VERSION ""

NS_ :

BS_:

BU_: VCM SCIM IC CCM

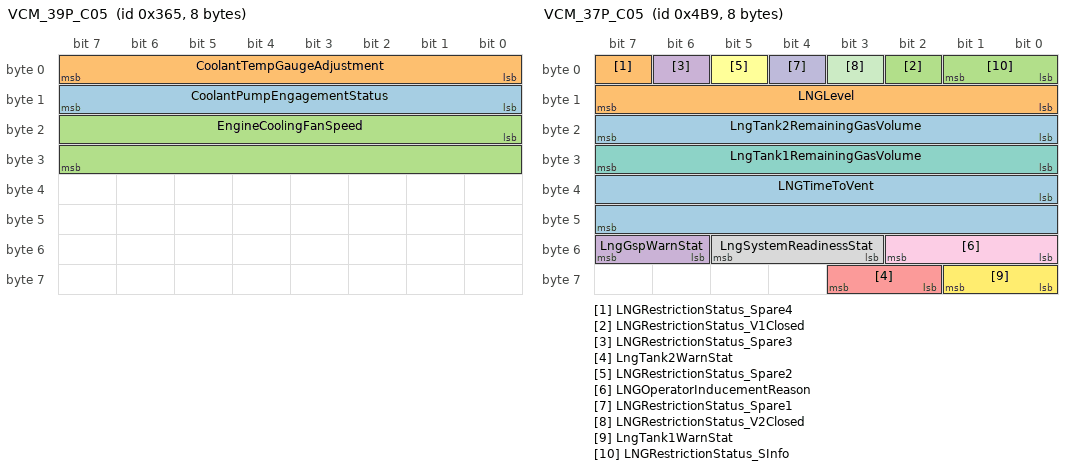
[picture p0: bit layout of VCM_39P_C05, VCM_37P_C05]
BO_ 869 VCM_39P_C05: 8 VCM
 SG_ CoolantPumpEngagementStatus : 8|8@1+ (0.4,0) [0|102] "Percent"  CCM
 SG_ CoolantTempGaugeAdjustment : 0|8@1+ (0.4,0) [0|102] "Percent"  IC
 SG_ EngineCoolingFanSpeed : 16|16@1+ (1,0) [0|65535] "rpm"  CCM

BO_ 881 VCM_38P_C05_FCM: 8 CCM
 SG_ VCM_38P_C05_FCS : 0|64@1+ (1,0) [0|0] ""  VCM

BO_ 880 VCM_38P_C05: 13 VCM
 SG_ PHTimerTGWEvCmd_PhTimer1_cmd : 46|3@1+ (1,0) [0|0] ""  CCM
 SG_ PHTimerTGWEvCmd_Timer2Temp : 7|5@1+ (1,0) [0|0] ""  CCM
 SG_ PHTimerTGWEvCmd_Timer2Hours : 95|8@1+ (1,0) [0|255] "h"  CCM
 SG_ PHTimerTGWEvCmd_Timer3StartDay : 30|4@1+ (1,0) [0|0] ""  CCM
 SG_ PHTimerTGWEvCmd_Timer2StartDay : 38|4@1+ (1,0) [0|0] ""  CCM
 SG_ PHTimerTGWEvCmd_PhTimer3_cmd : 52|3@1+ (1,0) [0|0] ""  CCM
 SG_ PHTimerTGWEvCmd_Timer3Hours : 87|8@1+ (1,0) [0|255] "h"  CCM
 SG_ PHTimerTGWEvCmd_Timer2Recur : 42|4@1+ (1,0) [0|0] ""  CCM
 SG_ PHTimerTGWEvCmd_PhTimer2_cmd : 49|3@1+ (1,0) [0|0] ""  CCM
 SG_ PHTimerTGWEvCmd_Timer3Temp : 12|5@1+ (1,0) [0|0] ""  CCM
 SG_ PHTimerTGWEvCmd_Timer1Hours : 71|8@1+ (1,0) [0|255] "h"  CCM
 SG_ PHTimerTGWEvCmd_Timer3Recur : 26|4@1+ (1,0) [0|0] ""  CCM
 SG_ PHTimerTGWEvCmd_Timer3Minutes : 55|8@1+ (1,0) [0|255] "min"  CCM
 SG_ PHTimerTGWEvCmd_Timer1Minutes : 79|8@1+ (1,0) [0|255] "min"  CCM
 SG_ PHTimerTGWEvCmd_Timer1Recur : 34|4@1+ (1,0) [0|0] ""  CCM
 SG_ PHTimerTGWEvCmd_Timer1StartDay : 22|4@1+ (1,0) [0|0] ""  CCM
 SG_ PHTimerTGWEvCmd_Timer2Minutes : 63|8@1+ (1,0) [0|255] "min"  CCM
 SG_ PHTimerTGWEvCmd_Timer1Duration : 0|7@1+ (1,0) [0|127] "min"  CCM
 SG_ PHTimerTGWEvCmd_Timer1Temp : 17|5@1+ (1,0) [0|0] ""  CCM

BO_ 1209 VCM_37P_C05: 8 VCM
 SG_ LngTank2RemainingGasVolume : 16|8@1+ (0.4,0) [0|102] "Percent"  IC
 SG_ LNGRestrictionStatus_Spare4 : 7|1@1+ (1,0) [0|0] ""  IC
 SG_ LNGRestrictionStatus_V1Closed : 2|1@1+ (1,0) [0|0] ""  IC
 SG_ LNGRestrictionStatus_Spare3 : 6|1@1+ (1,0) [0|0] ""  IC
 SG_ LngTank2WarnStat : 58|2@1+ (1,0) [0|0] ""  IC
 SG_ LNGRestrictionStatus_Spare2 : 5|1@1+ (1,0) [0|0] ""  IC
 SG_ LngTank1RemainingGasVolume : 24|8@1+ (0.4,0) [0|102] "Percent"  IC
 SG_ LngSystemReadinessStat : 51|3@1+ (1,0) [0|0] ""  IC
 SG_ LNGOperatorInducementReason : 48|3@1+ (1,0) [0|0] ""  IC
 SG_ LNGRestrictionStatus_Spare1 : 4|1@1+ (1,0) [0|0] ""  IC
 SG_ LNGRestrictionStatus_V2Closed : 3|1@1+ (1,0) [0|0] ""  IC
 SG_ LngTank1WarnStat : 56|2@1+ (1,0) [0|0] ""  IC
 SG_ LNGTimeToVent : 32|16@1+ (1,0) [0|65535] "min"  IC
 SG_ LNGLevel : 8|8@1+ (0.4,0) [0|102] "Percent"  IC
 SG_ LNGRestrictionStatus_SInfo : 0|2@1+ (1,0) [0|0] ""  IC
 SG_ LngGspWarnStat : 54|2@1+ (1,0) [0|0] ""  IC

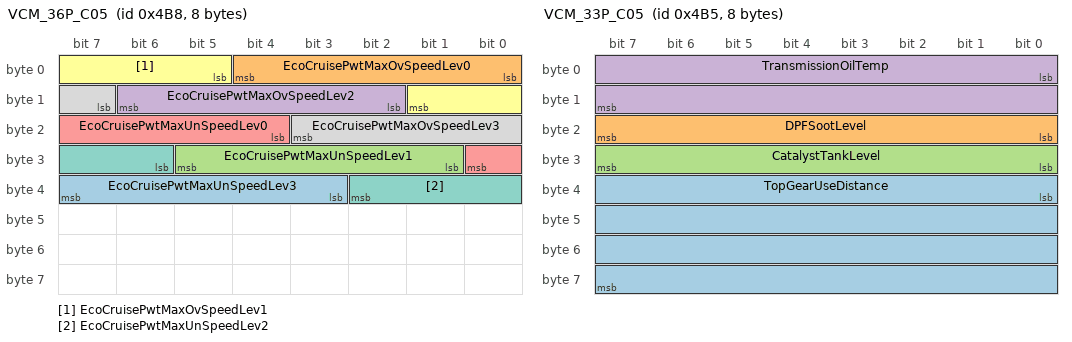
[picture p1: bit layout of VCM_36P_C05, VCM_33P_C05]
BO_ 1208 VCM_36P_C05: 8 VCM
 SG_ EcoCruisePwtMaxUnSpeedLev3 : 35|5@1+ (1,0) [0|31] "Km_per_h"  IC
 SG_ EcoCruisePwtMaxOvSpeedLev0 : 0|5@1+ (1,0) [0|31] "Km_per_h"  IC
 SG_ EcoCruisePwtMaxUnSpeedLev1 : 25|5@1+ (1,0) [0|31] "Km_per_h"  IC
 SG_ EcoCruisePwtMaxOvSpeedLev2 : 10|5@1+ (1,0) [0|31] "Km_per_h"  IC
 SG_ EcoCruisePwtMaxUnSpeedLev0 : 20|5@1+ (1,0) [0|31] "Km_per_h"  IC
 SG_ EcoCruisePwtMaxOvSpeedLev1 : 5|5@1+ (1,0) [0|31] "Km_per_h"  IC
 SG_ EcoCruisePwtMaxUnSpeedLev2 : 30|5@1+ (1,0) [0|31] "Km_per_h"  IC
 SG_ EcoCruisePwtMaxOvSpeedLev3 : 15|5@1+ (1,0) [0|31] "Km_per_h"  IC

BO_ 1207 VCM_35P_C05: 8 VCM
 SG_ EngineTotalLngConsumed : 32|32@1+ (0.01,0) [0|42949672.95] "kg"  IC
 SG_ TotalVehicleDistanceHighRes : 0|32@1+ (5,0) [0|21474836475] "m"  CCM

BO_ 1206 VCM_34P_C05: 8 VCM
 SG_ PredictedMileageOfNextPadChg : 0|32@1+ (1,0) [0|4294967295] "km"  IC
 SG_ EngineRunningTime : 32|32@1+ (1,0) [0|4294967295] "s"  IC

BO_ 1205 VCM_33P_C05: 8 VCM
 SG_ TopGearUseDistance : 32|32@1+ (0.01,0) [0|42949672.95] "km"  IC
 SG_ DPFSootLevel : 16|8@1+ (1,0) [0|255] "Percent"  IC
 SG_ CatalystTankLevel : 24|8@1+ (0.4,0) [0|102] "Percent"  IC
 SG_ TransmissionOilTemp : 0|16@1+ (0.03125,-273) [-273|1774.96875] "DegreeC"  IC

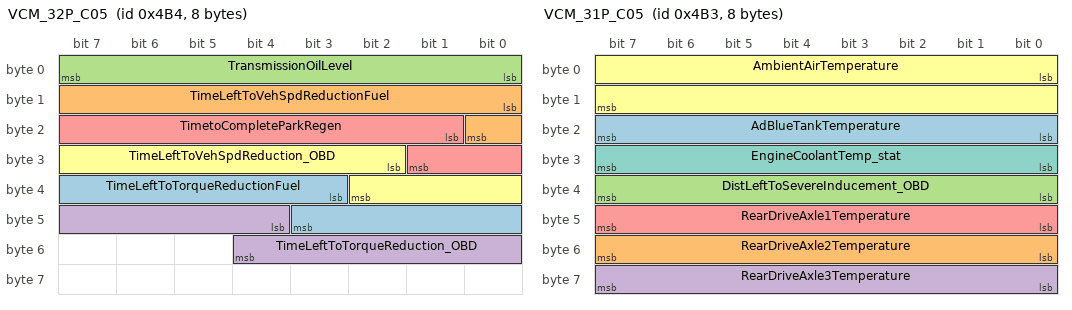
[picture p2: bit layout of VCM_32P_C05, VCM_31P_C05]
BO_ 1204 VCM_32P_C05: 8 VCM
 SG_ TimeLeftToTorqueReductionFuel : 35|9@1+ (12,0) [0|6132] "min"  IC
 SG_ TimeLeftToVehSpdReductionFuel : 8|9@1+ (15,0) [0|7665] "min"  IC
 SG_ TransmissionOilLevel : 0|8@1+ (0.4,0) [0|102] "Percent"  IC
 SG_ TimeLeftToTorqueReduction_OBD : 44|9@1+ (12,0) [0|6132] "min"  IC
 SG_ TimetoCompleteParkRegen : 17|9@1+ (15,0) [0|7665] "min"  IC
 SG_ TimeLeftToVehSpdReduction_OBD : 26|9@1+ (15,0) [0|7665] "min"  IC

BO_ 1203 VCM_31P_C05: 8 VCM
 SG_ AdBlueTankTemperature : 16|8@1+ (1,-50) [-50|205] "DegreeC"  IC
 SG_ RearDriveAxle2Temperature : 48|8@1+ (1,0) [0|255] "DegreeC"  IC
 SG_ DistLeftToSevereInducement_OBD : 32|8@1+ (5,0) [0|1275] "km"  IC
 SG_ RearDriveAxle3Temperature : 56|8@1+ (1,0) [0|255] "DegreeC"  IC
 SG_ RearDriveAxle1Temperature : 40|8@1+ (1,0) [0|255] "DegreeC"  IC
 SG_ AmbientAirTemperature : 0|16@1+ (0.03125,-273) [-273|1774.96875] "DegreeC"  CCM
 SG_ EngineCoolantTemp_stat : 24|8@1+ (1,-40) [-40|215] "DegreeC"  CCM

BO_ 1202 VCM_30P_C05: 8 VCM
 SG_ FasUsrDefinedDampingSetting : 42|5@1+ (1,-10) [-10|21] ""  IC
 SG_ SCROperatorInducementSeverity : 12|3@1+ (1,0) [0|0] ""  IC
 SG_ CatalystTankLevelLow : 57|2@1+ (1,0) [0|0] ""  IC
 SG_ MIStatusExtEMS : 61|2@1+ (1,0) [0|0] ""  IC
 SG_ FuelOperatorDeratingReason : 4|2@1+ (1,0) [0|0] ""  IC
 SG_ ActualFasPersSettingsButton : 18|3@1+ (1,0) [0|0] ""  IC
 SG_ BatteryEndOfCharge : 0|2@1+ (1,0) [0|0] ""  IC
 SG_ FasUsrDefStiffStraightSetting : 32|5@1+ (1,-10) [-10|21] ""  IC
 SG_ LiningWearWarning : 2|2@1+ (1,0) [0|0] ""  IC
 SG_ TorqueReductionStatus_OBD : 21|3@1+ (1,0) [0|0] ""  IC
 SG_ LoadCalibrationFeedback : 9|3@1+ (1,0) [0|0] ""  IC
 SG_ FasUsrDefLowSpeedReturnSetting : 47|5@1+ (1,-10) [-10|21] ""  IC
 SG_ FuelOperatorDeratingSeverity : 6|3@1+ (1,0) [0|0] ""  IC
 SG_ FasUsrDefStiffnessCurveSetting : 37|5@1+ (1,-10) [-10|21] ""  IC
 SG_ SCROperatorInducementReason : 15|3@1+ (1,0) [0|0] ""  IC
 SG_ ActualFasManualOffsetSetting : 52|5@1+ (1,-10) [-10|21] ""  IC
 SG_ MIDistinctWarningExtEMS : 24|4@1+ (1,0) [0|0] ""  IC
 SG_ FasDriver : 28|4@1+ (1,0) [0|0] ""  IC
 SG_ MIDistinctWarning : 59|2@1+ (1,0) [0|0] ""  IC

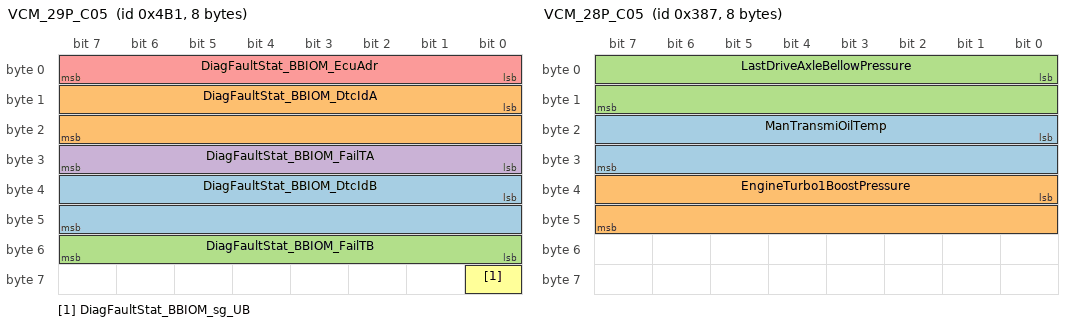
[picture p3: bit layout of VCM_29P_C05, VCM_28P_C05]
BO_ 1201 VCM_29P_C05: 8 VCM
 SG_ DiagFaultStat_BBIOM_DtcIdB : 32|16@1+ (1,0) [0|65535] ""  IC
 SG_ DiagFaultStat_BBIOM_DtcIdA : 8|16@1+ (1,0) [0|65535] ""  IC
 SG_ DiagFaultStat_BBIOM_FailTB : 48|8@1+ (1,0) [0|255] ""  IC
 SG_ DiagFaultStat_BBIOM_FailTA : 24|8@1+ (1,0) [0|255] ""  IC
 SG_ DiagFaultStat_BBIOM_EcuAdr : 0|8@1+ (1,0) [0|255] ""  IC
 SG_ DiagFaultStat_BBIOM_sg_UB : 56|1@1+ (1,0) [0|0] ""  IC

BO_ 903 VCM_28P_C05: 8 VCM
 SG_ ManTransmiOilTemp : 16|16@1+ (0.03125,-273) [-273|1774.96875] "DegreeC"  IC
 SG_ EngineTurbo1BoostPressure : 32|16@1+ (0.125,0) [0|8191.875] "kPa"  IC
 SG_ LastDriveAxleBellowPressure : 0|16@1+ (0.1,0) [0|6553.5] "kPa"  IC

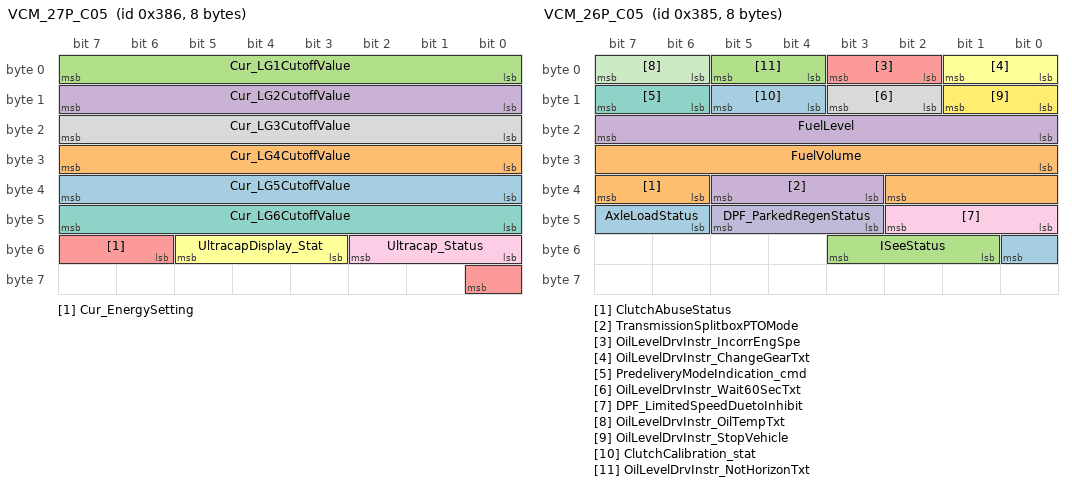
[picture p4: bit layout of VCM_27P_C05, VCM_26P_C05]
BO_ 902 VCM_27P_C05: 8 VCM
 SG_ Cur_LG5CutoffValue : 32|8@1+ (1,0) [0|255] "Percent"  IC
 SG_ Cur_LG4CutoffValue : 24|8@1+ (1,0) [0|255] "Percent"  IC
 SG_ Cur_LG1CutoffValue : 0|8@1+ (1,0) [0|255] "Percent"  IC
 SG_ Cur_LG2CutoffValue : 8|8@1+ (1,0) [0|255] "Percent"  IC
 SG_ Cur_EnergySetting : 54|3@1+ (1,0) [0|0] ""  IC
 SG_ UltracapDisplay_Stat : 51|3@1+ (1,0) [0|0] ""  IC
 SG_ Cur_LG6CutoffValue : 40|8@1+ (1,0) [0|255] "Percent"  IC
 SG_ Cur_LG3CutoffValue : 16|8@1+ (1,0) [0|255] "Percent"  IC
 SG_ Ultracap_Status : 48|3@1+ (1,0) [0|0] ""  IC

BO_ 901 VCM_26P_C05: 8 VCM
 SG_ AxleLoadStatus : 46|3@1+ (1,0) [0|0] ""  IC
 SG_ ClutchAbuseStatus : 38|2@1+ (1,0) [0|0] ""  IC
 SG_ ISeeStatus : 49|3@1+ (1,0) [0|0] ""  IC
 SG_ TransmissionSplitboxPTOMode : 35|3@1+ (1,0) [0|0] ""  IC
 SG_ OilLevelDrvInstr_IncorrEngSpe : 2|2@1+ (1,0) [0|0] ""  IC
 SG_ OilLevelDrvInstr_ChangeGearTxt : 0|2@1+ (1,0) [0|0] ""  IC
 SG_ PredeliveryModeIndication_cmd : 14|2@1+ (1,0) [0|0] ""  IC
 SG_ OilLevelDrvInstr_Wait60SecTxt : 10|2@1+ (1,0) [0|0] ""  IC
 SG_ DPF_LimitedSpeedDuetoInhibit : 40|3@1+ (1,0) [0|0] ""  IC
 SG_ DPF_ParkedRegenStatus : 43|3@1+ (1,0) [0|0] ""  IC
 SG_ OilLevelDrvInstr_OilTempTxt : 6|2@1+ (1,0) [0|0] ""  IC
 SG_ OilLevelDrvInstr_StopVehicle : 8|2@1+ (1,0) [0|0] ""  IC
 SG_ ClutchCalibration_stat : 12|2@1+ (1,0) [0|0] ""  IC
 SG_ FuelVolume : 24|11@1+ (1,0) [0|2047] "l"  CCM,IC
 SG_ OilLevelDrvInstr_NotHorizonTxt : 4|2@1+ (1,0) [0|0] ""  IC
 SG_ FuelLevel : 16|8@1+ (0.4,0) [0|102] "Percent"  CCM

BO_ 868 VCM_25P_C05: 8 VCM
 SG_ DrainPrimingStatus : 60|3@1+ (1,0) [0|0] ""  IC
 SG_ FrontConspicLamp_stat_HiRight : 0|3@1+ (1,0) [0|0] ""  IC
 SG_ FrontConspicLamp_stat_LoRight : 3|3@1+ (1,0) [0|0] ""  IC
 SG_ CoolantTempHigh : 54|3@1+ (1,0) [0|0] ""  IC
 SG_ AutoWheelBrakesStatus : 32|3@1+ (1,0) [0|0] ""  IC
 SG_ OilLevelLow : 51|3@1+ (1,0) [0|0] ""  IC
 SG_ InletAirHeaterStatus1 : 40|2@1+ (1,0) [0|0] ""  IC
 SG_ DeicingFunction_Stat : 45|3@1+ (1,0) [0|0] ""  IC
 SG_ SelfStartAssist_stat : 14|2@1+ (1,0) [0|0] ""  IC
 SG_ TrailerDirIndLeftOutputStat : 19|3@1+ (1,0) [0|0] ""  IC
 SG_ TrailerPosLightLeftOutputStat : 24|3@1+ (1,0) [0|0] ""  IC
 SG_ TrailerBrakeLightOutputStat : 16|3@1+ (1,0) [0|0] ""  IC
 SG_ StartBatteryDisplay_stat : 35|3@1+ (1,0) [0|0] ""  IC
 SG_ DeicingBulb_Stat : 42|3@1+ (1,0) [0|0] ""  IC
 SG_ LivBatDisconnectDetectStat : 30|2@1+ (1,0) [0|0] ""  IC
 SG_ FrontConspicLamp_stat_LoLeft : 9|3@1+ (1,0) [0|0] ""  IC
 SG_ FuelFilterClogged : 57|3@1+ (1,0) [0|0] ""  IC
 SG_ EngineFanOverspeed : 22|2@1+ (1,0) [0|0] ""  IC
 SG_ JumpChargeInterface_stat : 38|2@1+ (1,0) [0|0] ""  IC
 SG_ OilPressureLow : 48|3@1+ (1,0) [0|0] ""  IC
 SG_ FrontConspicLamp_stat_HiLeft : 6|3@1+ (1,0) [0|0] ""  IC
 SG_ GChargerStatus : 27|3@1+ (1,0) [0|0] ""  IC
 SG_ TrailerRevAndFogOutput_stat : 12|2@1+ (1,0) [0|0] ""  IC

BO_ 867 VCM_24P_C05: 8 VCM
 SG_ DirIndSideLamp_stat : 54|3@1+ (1,0) [0|0] ""  IC
 SG_ DirInd_Front_Status : 27|3@1+ (1,0) [0|0] ""  IC
 SG_ FogLightFrontLamp_stat : 3|3@1+ (1,0) [0|0] ""  IC
 SG_ MainBeamLEDStatusRight : 33|3@1+ (1,0) [0|0] ""  IC
 SG_ RevLightLamp_stat : 0|3@1+ (1,0) [0|0] ""  IC
 SG_ ExtraMainBeamLamp_stat : 24|3@1+ (1,0) [0|0] ""  IC
 SG_ MainBeamLEDStatusLeft : 18|3@1+ (1,0) [0|0] ""  IC
 SG_ PositionLightRearLamp_stat : 36|3@1+ (1,0) [0|0] ""  IC
 SG_ TrailerPosLightRightOutputStat : 12|3@1+ (1,0) [0|0] ""  IC
 SG_ DirIndRearLamp_Stat : 51|3@1+ (1,0) [0|0] ""  IC
 SG_ FogLightRearLamp_stat : 48|3@1+ (1,0) [0|0] ""  IC
 SG_ BrakeLightLamp_stat : 45|3@1+ (1,0) [0|0] ""  IC
 SG_ DippedBeamLamp_stat : 15|3@1+ (1,0) [0|0] ""  IC
 SG_ ChassiInstepLightsLamp_stat : 30|3@1+ (1,0) [0|0] ""  IC
 SG_ DRLLamp_stat : 42|3@1+ (1,0) [0|0] ""  IC
 SG_ TrailerDirIndRightOutputStat : 6|3@1+ (1,0) [0|0] ""  IC
 SG_ HeadlampFan_stat : 60|3@1+ (1,0) [0|0] ""  IC
 SG_ MainBeamLamp_stat : 21|3@1+ (1,0) [0|0] ""  IC
 SG_ StaticCornerLightLamp_stat : 57|3@1+ (1,0) [0|0] ""  IC
 SG_ AuxFogLightLamp_stat : 9|3@1+ (1,0) [0|0] ""  IC
 SG_ PositionLightLamp_stat : 39|3@1+ (1,0) [0|0] ""  IC

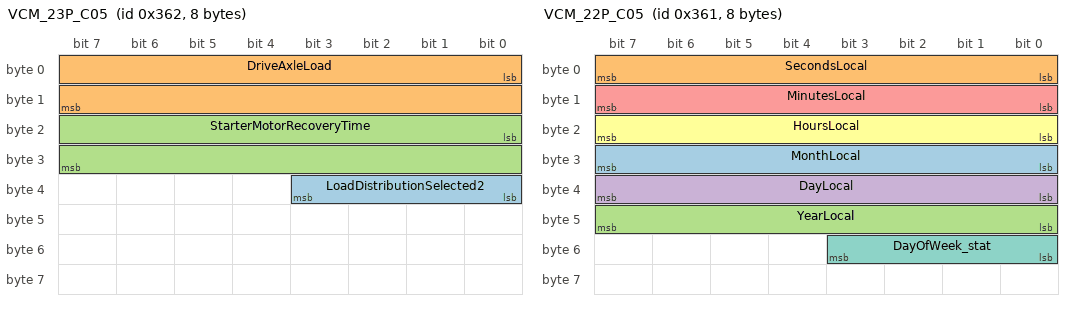
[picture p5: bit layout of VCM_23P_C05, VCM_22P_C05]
BO_ 866 VCM_23P_C05: 8 VCM
 SG_ LoadDistributionSelected2 : 32|4@1+ (1,0) [0|0] ""  IC
 SG_ DriveAxleLoad : 0|16@1+ (0.5,0) [0|32767.5] "kg"  IC
 SG_ StarterMotorRecoveryTime : 16|16@1+ (1,0) [0|65535] "s"  IC

BO_ 865 VCM_22P_C05: 8 VCM
 SG_ MonthLocal : 24|8@1+ (1,0) [0|255] "Months"  CCM
 SG_ SecondsLocal : 0|8@1+ (0.25,0) [0|63.75] "s"  CCM
 SG_ YearLocal : 40|8@1+ (1,1985) [1985|2240] "Years"  CCM
 SG_ DayLocal : 32|8@1+ (0.25,0) [0|63.75] "Days"  CCM
 SG_ MinutesLocal : 8|8@1+ (1,0) [0|255] "min"  CCM
 SG_ HoursLocal : 16|8@1+ (1,0) [0|255] "h"  CCM
 SG_ DayOfWeek_stat : 48|4@1+ (1,0) [0|0] ""  CCM,IC

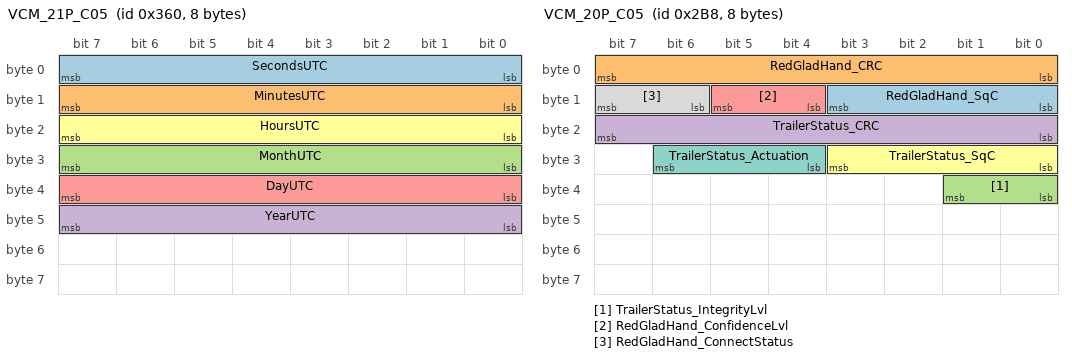
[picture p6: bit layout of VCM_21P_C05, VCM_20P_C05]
BO_ 864 VCM_21P_C05: 8 VCM
 SG_ SecondsUTC : 0|8@1+ (0.25,0) [0|63.75] "s"  CCM
 SG_ MinutesUTC : 8|8@1+ (1,0) [0|255] "min"  CCM
 SG_ MonthUTC : 24|8@1+ (1,0) [0|255] "Months"  CCM
 SG_ YearUTC : 40|8@1+ (1,1985) [1985|2240] "Years"  CCM
 SG_ DayUTC : 32|8@1+ (0.25,0) [0|63.75] "Days"  CCM
 SG_ HoursUTC : 16|8@1+ (1,0) [0|255] "h"  CCM

BO_ 696 VCM_20P_C05: 8 VCM
 SG_ RedGladHand_SqC : 8|4@1+ (1,0) [0|14] "NotApplicable"  IC
 SG_ RedGladHand_CRC : 0|8@1+ (1,0) [0|255] ""  IC
 SG_ TrailerStatus_IntegrityLvl : 32|2@1+ (1,0) [0|0] ""  IC
 SG_ TrailerStatus_CRC : 16|8@1+ (1,0) [0|255] ""  IC
 SG_ RedGladHand_ConfidenceLvl : 12|2@1+ (1,0) [0|0] ""  IC
 SG_ TrailerStatus_SqC : 24|4@1+ (1,0) [0|14] "NotApplicable"  IC
 SG_ TrailerStatus_Actuation : 28|3@1+ (1,0) [0|0] ""  IC
 SG_ RedGladHand_ConnectStatus : 14|2@1+ (1,0) [0|0] ""  IC

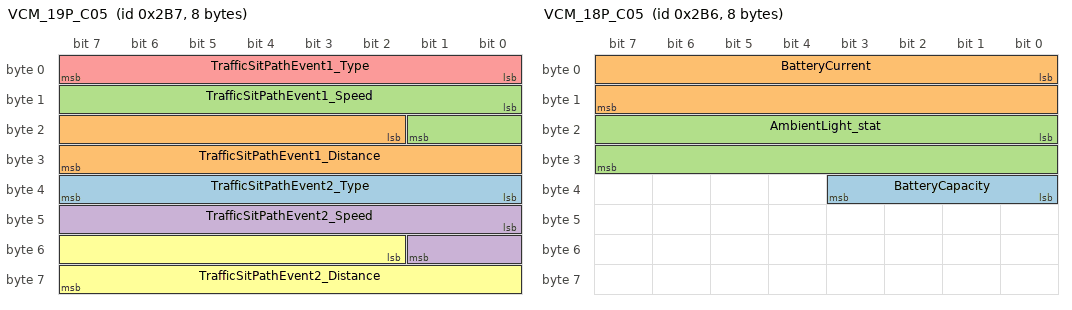
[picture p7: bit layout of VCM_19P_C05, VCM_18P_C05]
BO_ 695 VCM_19P_C05: 8 VCM
 SG_ TrafficSitPathEvent2_Type : 32|8@1+ (1,0) [0|0] ""  IC
 SG_ TrafficSitPathEvent1_Distance : 18|14@1+ (1,0) [0|16383] "m"  IC
 SG_ TrafficSitPathEvent1_Speed : 8|10@1+ (0.25,0) [0|255.75] "Km_per_h"  IC
 SG_ TrafficSitPathEvent2_Speed : 40|10@1+ (0.25,0) [0|255.75] "Km_per_h"  IC
 SG_ TrafficSitPathEvent1_Type : 0|8@1+ (1,0) [0|0] ""  IC
 SG_ TrafficSitPathEvent2_Distance : 50|14@1+ (1,0) [0|16383] "m"  IC

BO_ 694 VCM_18P_C05: 8 VCM
 SG_ BatteryCapacity : 32|4@1+ (1,0) [0|0] ""  IC
 SG_ BatteryCurrent : 0|16@1+ (0.05,-1600) [-1600|1676.75] "A"  IC
 SG_ AmbientLight_stat : 16|16@1+ (1,0) [0|65535] "lx"  IC

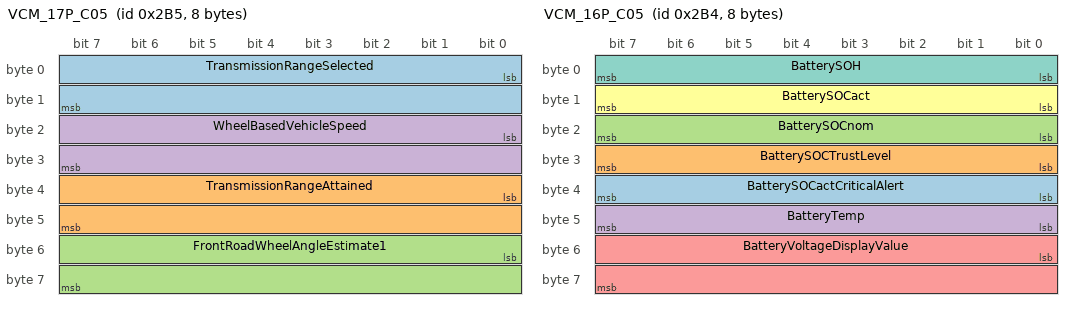
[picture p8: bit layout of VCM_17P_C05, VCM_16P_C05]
BO_ 693 VCM_17P_C05: 8 VCM
 SG_ TransmissionRangeSelected : 0|16@1+ (1,0) [0|0] ""  IC
 SG_ TransmissionRangeAttained : 32|16@1+ (1,0) [0|0] ""  IC
 SG_ FrontRoadWheelAngleEstimate1 : 48|16@1+ (5E-005,-1.6) [-1.6|1.67675] "rad"  IC
 SG_ WheelBasedVehicleSpeed : 16|16@1+ (0.00390625,0) [0|255.99609375] "Km_per_h"  CCM

BO_ 692 VCM_16P_C05: 8 VCM
 SG_ BatterySOCactCriticalAlert : 32|8@1+ (0.5,0) [0|127.5] "Percent"  IC
 SG_ BatterySOCTrustLevel : 24|8@1+ (0.5,0) [0|127.5] "Percent"  IC
 SG_ BatterySOCnom : 16|8@1+ (0.5,0) [0|127.5] "Percent"  IC
 SG_ BatteryTemp : 40|8@1+ (1,-45) [-45|210] "DegreeC"  IC
 SG_ BatteryVoltageDisplayValue : 48|16@1+ (0.05,0) [0|3276.75] "V"  IC
 SG_ BatterySOCact : 8|8@1+ (0.5,0) [0|127.5] "Percent"  IC
 SG_ BatterySOH : 0|8@1+ (0.5,0) [0|127.5] "Percent"  IC

CM_ "COM_MATRIX_T3_1.9.0";
CM_ BU_ VCM "Vehicle Control Module";
CM_ BU_ SCIM "Security and Cab Interface Module";
CM_ BU_ IC "Instrument Cluster";
CM_ BU_ CCM "Climate Control Module";
BA_DEF_ BO_  "GenMsgStartDelayTime" INT 0 0;
BA_DEF_ BO_  "GenMsgDelayTime" INT 0 0;
BA_DEF_ BO_  "GenMsgCycleTime" INT 0 0;
BA_DEF_ BO_  "GenMsgSendType" ENUM  "Cyclic","NotUsed","NotUsed","NotUsed","NotUsed","NotUsed","NotUsed","IfActive","NoMsgSendType","NotUsed";
BA_DEF_ SG_  "GenSigStartValue" INT 0 0;
BA_DEF_ SG_  "GenSigCycleTimeActive" INT 0 0;
BA_DEF_ SG_  "GenSigCycleTime" INT 0 0;
BA_DEF_ SG_  "GenSigSendType" ENUM  "Cyclic","OnWrite","OnWriteWithRepetition","OnChange","OnChangeWithRepetition","IfActive","IfActiveWithRepetition","NoSigSendType","NotUsed","NotUsed","NotUsed","NotUsed","NotUsed";
BA_DEF_  "Baudrate" INT 0 1000000;
BA_DEF_  "NmType" STRING ;
BA_DEF_  "Manufacturer" STRING ;
BA_DEF_  "VersionYear" INT 0 99;
BA_DEF_  "VersionNumber" INT 0 99;
BA_DEF_  "VersionMonth" INT 1 12;
BA_DEF_  "VersionDay" INT 1 31;
BA_DEF_ BO_  "VFrameFormat" ENUM  "StandardCAN","ExtendedCAN","reserved","J1939PG","reserved","reserved","reserved","reserved","reserved","reserved","reserved","reserved","reserved","reserved","StandardCAN_FD","ExtendedCAN_FD";
BA_DEF_ BU_  "TpOwnSystemEcuNumber" HEX 0 255;
BA_DEF_ SG_  "SigType" ENUM  "Default","Range","RangeSigned","ASCII","Discrete","Control","ReferencePGN","DTC","StringDelimiter","StringLength","StringLengthControl";
BA_DEF_ BU_  "NmStationAddress" INT 0 255;
BA_DEF_  "NmAsrWaitBusSleepTime" INT 0 65535;
BA_DEF_  "NmAsrTimeoutTime" INT 0 65535;
BA_DEF_  "NmAsrRepeatMessageTime" INT 0 65535;
BA_DEF_ BU_  "NmAsrNodeIdentifier" HEX 0 253;
BA_DEF_ BU_  "NmAsrNode" ENUM  "No","Yes";
BA_DEF_  "NmAsrMessageCount" INT 1 256;
BA_DEF_ BO_  "NmAsrMessage" ENUM  "No","Yes";
BA_DEF_  "NmAsrCanMsgCycleTime" INT 0 65535;
BA_DEF_  "NmAsrBaseAddress" HEX 0 536870911;
BA_DEF_ SG_  "NeedsUpdateBit" ENUM  "No","Yes";
BA_DEF_ SG_  "MmAnSignal" ENUM  "No","Yes";
BA_DEF_ BU_  "IsOBDrelevant" ENUM  "No","Yes";
BA_DEF_ SG_  "GenSigMaxLatency" INT 0 65535;
BA_DEF_ SG_  "GenSigILSupport" ENUM  "Yes","No";
BA_DEF_ BO_  "GenMsgILSupport" ENUM  "No","Yes";
BA_DEF_ SG_  "E2EProfile" STRING ;
BA_DEF_  "E2EP05WindowSize" INT 0 65535;
BA_DEF_  "E2EP05ProfileName" STRING ;
BA_DEF_  "E2EP05MinOkStateValid" INT 0 65535;
BA_DEF_  "E2EP05MinOkStateInvalid" INT 0 65535;
BA_DEF_  "E2EP05MinOkStateInit" INT 0 65535;
BA_DEF_  "E2EP05MaxErrorStateValid" INT 0 65535;
BA_DEF_  "E2EP05MaxErrorStateInvalid" INT 0 65535;
BA_DEF_  "E2EP05MaxErrorStateInit" INT 0 65535;
BA_DEF_  "E2EP05MaxDeltaCounter" INT 0 65535;
BA_DEF_  "E2EP01WindowSize" INT 0 65535;
BA_DEF_  "E2EP01SyncCounterInit" INT 0 65535;
BA_DEF_  "E2EP01ProfileName" STRING ;
BA_DEF_  "E2EP01MinOkStateValid" INT 0 65535;
BA_DEF_  "E2EP01MinOkStateInvalid" INT 0 65535;
BA_DEF_  "E2EP01MinOkStateInit" INT 0 65535;
BA_DEF_  "E2EP01MaxNoNewOrRepeatedData" INT 0 65535;
BA_DEF_  "E2EP01MaxErrorStateValid" INT 0 65535;
BA_DEF_  "E2EP01MaxErrorStateInvalid" INT 0 65535;
BA_DEF_  "E2EP01MaxErrorStateInit" INT 0 65535;
BA_DEF_  "E2EP01MaxDeltaCounter" INT 0 65535;
BA_DEF_  "E2EP01DataIdMode" ENUM  "all16Bit","alternating8Bit","lower12Bit","lower8Bit";
BA_DEF_  "E2EP01CounterOffset" INT 0 65535;
BA_DEF_ SG_  "E2EDataLength" INT 0 65535;
BA_DEF_ SG_  "E2EDataId" INT 0 65535;
BA_DEF_ BU_  "DiagnosticClientAddress" HEX 0 255;
BA_DEF_ BO_  "DiagUUDTResponse" ENUM  "No","Yes";
BA_DEF_ BO_  "DiagState" ENUM  "No","Yes";
BA_DEF_ BU_  "DiagRole" ENUM  "None","OBDTester","ExternalTester","InternalTester";
BA_DEF_ BO_  "DiagResponse" ENUM  "No","Yes";
BA_DEF_ BO_  "DiagRequest" ENUM  "No","Yes";
BA_DEF_ BO_  "DiagConnection" HEX 0 65535;
BA_DEF_  "DBName" STRING ;
BA_DEF_ BO_  "CanTpFcFrameId" HEX 0 2147483647;
BA_DEF_ BO_  "CanTpBs" INT 0 255;
BA_DEF_  "BusType" STRING ;
BA_DEF_  "BaudrateCANFD" INT 0 5000000;
BA_DEF_REL_ BU_SG_REL_  "GenSigTimeoutTime" INT 0 65535;
BA_DEF_REL_ BU_SG_REL_  "GenSigFirstTimeoutTime" INT 0 65535;
BA_DEF_DEF_  "GenMsgStartDelayTime" 0;
BA_DEF_DEF_  "GenMsgDelayTime" 0;
BA_DEF_DEF_  "GenMsgCycleTime" 0;
BA_DEF_DEF_  "GenMsgSendType" "Cyclic";
BA_DEF_DEF_  "GenSigStartValue" 0;
BA_DEF_DEF_  "GenSigCycleTimeActive" 0;
BA_DEF_DEF_  "GenSigCycleTime" 0;
BA_DEF_DEF_  "GenSigSendType" "Cyclic";
BA_DEF_DEF_  "Baudrate" 500000;
BA_DEF_DEF_  "NmType" "";
BA_DEF_DEF_  "Manufacturer" "VOLVO_AB";
BA_DEF_DEF_  "VersionYear" 0;
BA_DEF_DEF_  "VersionNumber" 0;
BA_DEF_DEF_  "VersionMonth" 1;
BA_DEF_DEF_  "VersionDay" 1;
BA_DEF_DEF_  "VFrameFormat" "ExtendedCAN";
BA_DEF_DEF_  "TpOwnSystemEcuNumber" 0;
BA_DEF_DEF_  "SigType" "Default";
BA_DEF_DEF_  "NmStationAddress" 254;
BA_DEF_DEF_  "NmAsrWaitBusSleepTime" 750;
BA_DEF_DEF_  "NmAsrTimeoutTime" 5000;
BA_DEF_DEF_  "NmAsrRepeatMessageTime" 300;
BA_DEF_DEF_  "NmAsrNodeIdentifier" 0;
BA_DEF_DEF_  "NmAsrNode" "Yes";
BA_DEF_DEF_  "NmAsrMessageCount" 256;
BA_DEF_DEF_  "NmAsrMessage" "No";
BA_DEF_DEF_  "NmAsrCanMsgCycleTime" 200;
BA_DEF_DEF_  "NmAsrBaseAddress" 486506496;
BA_DEF_DEF_  "NeedsUpdateBit" "No";
BA_DEF_DEF_  "MmAnSignal" "No";
BA_DEF_DEF_  "IsOBDrelevant" "No";
BA_DEF_DEF_  "GenSigMaxLatency" 0;
BA_DEF_DEF_  "GenSigILSupport" "Yes";
BA_DEF_DEF_  "GenMsgILSupport" "Yes";
BA_DEF_DEF_  "E2EProfile" "none";
BA_DEF_DEF_  "E2EP05WindowSize" 5;
BA_DEF_DEF_  "E2EP05ProfileName" "PROFILE_05";
BA_DEF_DEF_  "E2EP05MinOkStateValid" 1;
BA_DEF_DEF_  "E2EP05MinOkStateInvalid" 3;
BA_DEF_DEF_  "E2EP05MinOkStateInit" 1;
BA_DEF_DEF_  "E2EP05MaxErrorStateValid" 3;
BA_DEF_DEF_  "E2EP05MaxErrorStateInvalid" 1;
BA_DEF_DEF_  "E2EP05MaxErrorStateInit" 2;
BA_DEF_DEF_  "E2EP05MaxDeltaCounter" 1;
BA_DEF_DEF_  "E2EP01WindowSize" 5;
BA_DEF_DEF_  "E2EP01SyncCounterInit" 1;
BA_DEF_DEF_  "E2EP01ProfileName" "PROFILE_01";
BA_DEF_DEF_  "E2EP01MinOkStateValid" 1;
BA_DEF_DEF_  "E2EP01MinOkStateInvalid" 3;
BA_DEF_DEF_  "E2EP01MinOkStateInit" 1;
BA_DEF_DEF_  "E2EP01MaxNoNewOrRepeatedData" 5;
BA_DEF_DEF_  "E2EP01MaxErrorStateValid" 3;
BA_DEF_DEF_  "E2EP01MaxErrorStateInvalid" 1;
BA_DEF_DEF_  "E2EP01MaxErrorStateInit" 2;
BA_DEF_DEF_  "E2EP01MaxDeltaCounter" 1;
BA_DEF_DEF_  "E2EP01DataIdMode" "all16Bit";
BA_DEF_DEF_  "E2EP01CounterOffset" 8;
BA_DEF_DEF_  "E2EDataLength" 0;
BA_DEF_DEF_  "E2EDataId" 0;
BA_DEF_DEF_  "DiagnosticClientAddress" 0;
BA_DEF_DEF_  "DiagUUDTResponse" "No";
BA_DEF_DEF_  "DiagState" "No";
BA_DEF_DEF_  "DiagRole" "None";
BA_DEF_DEF_  "DiagResponse" "No";
BA_DEF_DEF_  "DiagRequest" "No";
BA_DEF_DEF_  "DiagConnection" 0;
BA_DEF_DEF_  "DBName" "";
BA_DEF_DEF_  "CanTpFcFrameId" 2147483647;
BA_DEF_DEF_  "CanTpBs" 255;
BA_DEF_DEF_  "BusType" "";
BA_DEF_DEF_  "BaudrateCANFD" 0;
BA_DEF_DEF_REL_ "GenSigTimeoutTime" 0;
BA_DEF_DEF_REL_ "GenSigFirstTimeoutTime" 0;
BA_ "NmType" "NmAsr";
BA_ "BusType" "CAN";
BA_ "BaudrateCANFD" 1000000;
BA_ "VersionDay" 24;
BA_ "VersionMonth" 2;
BA_ "VersionNumber" 1;
BA_ "VersionYear" 22;
BA_ "DBName" "CAN05";
BA_ "DiagRole" BU_ VCM 3;
BA_ "DiagnosticClientAddress" BU_ VCM 244;
BA_ "IsOBDrelevant" BU_ VCM 1;
BA_ "TpOwnSystemEcuNumber" BU_ VCM 36;
BA_ "NmAsrNodeIdentifier" BU_ VCM 36;
BA_ "TpOwnSystemEcuNumber" BU_ SCIM 64;
BA_ "NmAsrNodeIdentifier" BU_ SCIM 64;
BA_ "TpOwnSystemEcuNumber" BU_ IC 97;
BA_ "NmAsrNodeIdentifier" BU_ IC 97;
BA_ "TpOwnSystemEcuNumber" BU_ CCM 152;
BA_ "NmAsrNodeIdentifier" BU_ CCM 152;
BA_ "VFrameFormat" BO_ 869 0;
BA_ "GenMsgCycleTime" BO_ 869 250;
BA_ "GenMsgILSupport" BO_ 881 0;
BA_ "VFrameFormat" BO_ 881 0;
BA_ "GenMsgSendType" BO_ 881 8;
BA_ "CanTpFcFrameId" BO_ 880 881;
BA_ "VFrameFormat" BO_ 880 0;
BA_ "GenMsgCycleTime" BO_ 880 100;
BA_ "VFrameFormat" BO_ 1209 0;
BA_ "GenMsgCycleTime" BO_ 1209 1000;
BA_ "VFrameFormat" BO_ 1208 0;
BA_ "GenMsgCycleTime" BO_ 1208 1000;
BA_ "VFrameFormat" BO_ 1207 0;
BA_ "GenMsgCycleTime" BO_ 1207 1000;
BA_ "VFrameFormat" BO_ 1206 0;
BA_ "GenMsgCycleTime" BO_ 1206 1000;
BA_ "VFrameFormat" BO_ 1205 0;
BA_ "GenMsgCycleTime" BO_ 1205 1000;
BA_ "VFrameFormat" BO_ 1204 0;
BA_ "GenMsgCycleTime" BO_ 1204 1000;
BA_ "VFrameFormat" BO_ 1203 0;
BA_ "GenMsgCycleTime" BO_ 1203 1000;
BA_ "VFrameFormat" BO_ 1202 0;
BA_ "GenMsgCycleTime" BO_ 1202 1000;
BA_ "VFrameFormat" BO_ 1201 0;
BA_ "GenMsgCycleTime" BO_ 1201 1000;
BA_ "VFrameFormat" BO_ 903 0;
BA_ "GenMsgCycleTime" BO_ 903 500;
BA_ "VFrameFormat" BO_ 902 0;
BA_ "GenMsgCycleTime" BO_ 902 500;
BA_ "VFrameFormat" BO_ 901 0;
BA_ "GenMsgCycleTime" BO_ 901 500;
BA_ "VFrameFormat" BO_ 868 0;
BA_ "GenMsgCycleTime" BO_ 868 250;
BA_ "VFrameFormat" BO_ 867 0;
BA_ "GenMsgCycleTime" BO_ 867 250;
BA_ "VFrameFormat" BO_ 866 0;
BA_ "GenMsgCycleTime" BO_ 866 250;
BA_ "VFrameFormat" BO_ 865 0;
BA_ "GenMsgCycleTime" BO_ 865 250;
BA_ "VFrameFormat" BO_ 864 0;
BA_ "GenMsgCycleTime" BO_ 864 250;
BA_ "VFrameFormat" BO_ 696 0;
BA_ "GenMsgCycleTime" BO_ 696 100;
BA_ "VFrameFormat" BO_ 695 0;
BA_ "GenMsgCycleTime" BO_ 695 100;
BA_ "VFrameFormat" BO_ 694 0;
BA_ "GenMsgCycleTime" BO_ 694 100;
BA_ "VFrameFormat" BO_ 693 0;
BA_ "GenMsgCycleTime" BO_ 693 100;
BA_ "VFrameFormat" BO_ 692 0;
BA_ "GenMsgCycleTime" BO_ 692 100;
BA_ "GenSigCycleTime" SG_ 869 CoolantPumpEngagementStatus 100;
BA_ "GenSigCycleTimeActive" SG_ 869 CoolantPumpEngagementStatus 100;
BA_ "GenSigStartValue" SG_ 869 CoolantPumpEngagementStatus 255;
BA_ "GenSigMaxLatency" SG_ 869 CoolantPumpEngagementStatus 260;
BA_ "GenSigCycleTime" SG_ 869 CoolantTempGaugeAdjustment 100;
BA_ "GenSigCycleTimeActive" SG_ 869 CoolantTempGaugeAdjustment 100;
BA_ "GenSigStartValue" SG_ 869 CoolantTempGaugeAdjustment 255;
BA_ "GenSigMaxLatency" SG_ 869 CoolantTempGaugeAdjustment 260;
BA_ "GenSigCycleTime" SG_ 869 EngineCoolingFanSpeed 100;
BA_ "GenSigCycleTimeActive" SG_ 869 EngineCoolingFanSpeed 100;
BA_ "GenSigStartValue" SG_ 869 EngineCoolingFanSpeed 65535;
BA_ "GenSigMaxLatency" SG_ 869 EngineCoolingFanSpeed 250;
BA_ "GenSigSendType" SG_ 881 VCM_38P_C05_FCS 7;
BA_ "GenSigCycleTime" SG_ 880 PHTimerTGWEvCmd_PhTimer1_cmd 100;
BA_ "GenSigCycleTimeActive" SG_ 880 PHTimerTGWEvCmd_PhTimer1_cmd 100;
BA_ "GenSigStartValue" SG_ 880 PHTimerTGWEvCmd_PhTimer1_cmd 7;
BA_ "GenSigMaxLatency" SG_ 880 PHTimerTGWEvCmd_PhTimer1_cmd 100;
BA_ "GenSigCycleTime" SG_ 880 PHTimerTGWEvCmd_Timer2Temp 100;
BA_ "GenSigCycleTimeActive" SG_ 880 PHTimerTGWEvCmd_Timer2Temp 100;
BA_ "GenSigStartValue" SG_ 880 PHTimerTGWEvCmd_Timer2Temp 31;
BA_ "GenSigMaxLatency" SG_ 880 PHTimerTGWEvCmd_Timer2Temp 100;
BA_ "GenSigCycleTime" SG_ 880 PHTimerTGWEvCmd_Timer2Hours 100;
BA_ "GenSigCycleTimeActive" SG_ 880 PHTimerTGWEvCmd_Timer2Hours 100;
BA_ "GenSigStartValue" SG_ 880 PHTimerTGWEvCmd_Timer2Hours 255;
BA_ "GenSigMaxLatency" SG_ 880 PHTimerTGWEvCmd_Timer2Hours 100;
BA_ "GenSigCycleTime" SG_ 880 PHTimerTGWEvCmd_Timer3StartDay 100;
BA_ "GenSigCycleTimeActive" SG_ 880 PHTimerTGWEvCmd_Timer3StartDay 100;
BA_ "GenSigStartValue" SG_ 880 PHTimerTGWEvCmd_Timer3StartDay 15;
BA_ "GenSigMaxLatency" SG_ 880 PHTimerTGWEvCmd_Timer3StartDay 100;
BA_ "GenSigCycleTime" SG_ 880 PHTimerTGWEvCmd_Timer2StartDay 100;
BA_ "GenSigCycleTimeActive" SG_ 880 PHTimerTGWEvCmd_Timer2StartDay 100;
BA_ "GenSigStartValue" SG_ 880 PHTimerTGWEvCmd_Timer2StartDay 15;
BA_ "GenSigMaxLatency" SG_ 880 PHTimerTGWEvCmd_Timer2StartDay 100;
BA_ "GenSigCycleTime" SG_ 880 PHTimerTGWEvCmd_PhTimer3_cmd 100;
BA_ "GenSigCycleTimeActive" SG_ 880 PHTimerTGWEvCmd_PhTimer3_cmd 100;
BA_ "GenSigStartValue" SG_ 880 PHTimerTGWEvCmd_PhTimer3_cmd 7;
BA_ "GenSigMaxLatency" SG_ 880 PHTimerTGWEvCmd_PhTimer3_cmd 100;
BA_ "GenSigCycleTime" SG_ 880 PHTimerTGWEvCmd_Timer3Hours 100;
BA_ "GenSigCycleTimeActive" SG_ 880 PHTimerTGWEvCmd_Timer3Hours 100;
BA_ "GenSigStartValue" SG_ 880 PHTimerTGWEvCmd_Timer3Hours 255;
BA_ "GenSigMaxLatency" SG_ 880 PHTimerTGWEvCmd_Timer3Hours 100;
BA_ "GenSigCycleTime" SG_ 880 PHTimerTGWEvCmd_Timer2Recur 100;
BA_ "GenSigCycleTimeActive" SG_ 880 PHTimerTGWEvCmd_Timer2Recur 100;
BA_ "GenSigStartValue" SG_ 880 PHTimerTGWEvCmd_Timer2Recur 15;
BA_ "GenSigMaxLatency" SG_ 880 PHTimerTGWEvCmd_Timer2Recur 100;
BA_ "GenSigCycleTime" SG_ 880 PHTimerTGWEvCmd_PhTimer2_cmd 100;
BA_ "GenSigCycleTimeActive" SG_ 880 PHTimerTGWEvCmd_PhTimer2_cmd 100;
BA_ "GenSigStartValue" SG_ 880 PHTimerTGWEvCmd_PhTimer2_cmd 7;
BA_ "GenSigMaxLatency" SG_ 880 PHTimerTGWEvCmd_PhTimer2_cmd 100;
BA_ "GenSigCycleTime" SG_ 880 PHTimerTGWEvCmd_Timer3Temp 100;
BA_ "GenSigCycleTimeActive" SG_ 880 PHTimerTGWEvCmd_Timer3Temp 100;
BA_ "GenSigStartValue" SG_ 880 PHTimerTGWEvCmd_Timer3Temp 31;
BA_ "GenSigMaxLatency" SG_ 880 PHTimerTGWEvCmd_Timer3Temp 100;
BA_ "GenSigCycleTime" SG_ 880 PHTimerTGWEvCmd_Timer1Hours 100;
BA_ "GenSigCycleTimeActive" SG_ 880 PHTimerTGWEvCmd_Timer1Hours 100;
BA_ "GenSigStartValue" SG_ 880 PHTimerTGWEvCmd_Timer1Hours 255;
BA_ "GenSigMaxLatency" SG_ 880 PHTimerTGWEvCmd_Timer1Hours 100;
BA_ "GenSigCycleTime" SG_ 880 PHTimerTGWEvCmd_Timer3Recur 100;
BA_ "GenSigCycleTimeActive" SG_ 880 PHTimerTGWEvCmd_Timer3Recur 100;
BA_ "GenSigStartValue" SG_ 880 PHTimerTGWEvCmd_Timer3Recur 15;
BA_ "GenSigMaxLatency" SG_ 880 PHTimerTGWEvCmd_Timer3Recur 100;
BA_ "GenSigCycleTime" SG_ 880 PHTimerTGWEvCmd_Timer3Minutes 100;
BA_ "GenSigCycleTimeActive" SG_ 880 PHTimerTGWEvCmd_Timer3Minutes 100;
BA_ "GenSigStartValue" SG_ 880 PHTimerTGWEvCmd_Timer3Minutes 255;
BA_ "GenSigMaxLatency" SG_ 880 PHTimerTGWEvCmd_Timer3Minutes 100;
BA_ "GenSigCycleTime" SG_ 880 PHTimerTGWEvCmd_Timer1Minutes 100;
BA_ "GenSigCycleTimeActive" SG_ 880 PHTimerTGWEvCmd_Timer1Minutes 100;
BA_ "GenSigStartValue" SG_ 880 PHTimerTGWEvCmd_Timer1Minutes 255;
BA_ "GenSigMaxLatency" SG_ 880 PHTimerTGWEvCmd_Timer1Minutes 100;
BA_ "GenSigCycleTime" SG_ 880 PHTimerTGWEvCmd_Timer1Recur 100;
BA_ "GenSigCycleTimeActive" SG_ 880 PHTimerTGWEvCmd_Timer1Recur 100;
BA_ "GenSigStartValue" SG_ 880 PHTimerTGWEvCmd_Timer1Recur 15;
BA_ "GenSigMaxLatency" SG_ 880 PHTimerTGWEvCmd_Timer1Recur 100;
BA_ "GenSigCycleTime" SG_ 880 PHTimerTGWEvCmd_Timer1StartDay 100;
BA_ "GenSigCycleTimeActive" SG_ 880 PHTimerTGWEvCmd_Timer1StartDay 100;
BA_ "GenSigStartValue" SG_ 880 PHTimerTGWEvCmd_Timer1StartDay 15;
BA_ "GenSigMaxLatency" SG_ 880 PHTimerTGWEvCmd_Timer1StartDay 100;
BA_ "GenSigCycleTime" SG_ 880 PHTimerTGWEvCmd_Timer2Minutes 100;
BA_ "GenSigCycleTimeActive" SG_ 880 PHTimerTGWEvCmd_Timer2Minutes 100;
BA_ "GenSigStartValue" SG_ 880 PHTimerTGWEvCmd_Timer2Minutes 255;
BA_ "GenSigMaxLatency" SG_ 880 PHTimerTGWEvCmd_Timer2Minutes 100;
BA_ "GenSigCycleTime" SG_ 880 PHTimerTGWEvCmd_Timer1Duration 100;
BA_ "GenSigCycleTimeActive" SG_ 880 PHTimerTGWEvCmd_Timer1Duration 100;
BA_ "GenSigStartValue" SG_ 880 PHTimerTGWEvCmd_Timer1Duration 127;
BA_ "GenSigMaxLatency" SG_ 880 PHTimerTGWEvCmd_Timer1Duration 100;
BA_ "GenSigCycleTime" SG_ 880 PHTimerTGWEvCmd_Timer1Temp 100;
BA_ "GenSigCycleTimeActive" SG_ 880 PHTimerTGWEvCmd_Timer1Temp 100;
BA_ "GenSigStartValue" SG_ 880 PHTimerTGWEvCmd_Timer1Temp 31;
BA_ "GenSigMaxLatency" SG_ 880 PHTimerTGWEvCmd_Timer1Temp 100;
BA_ "GenSigCycleTime" SG_ 1209 LngTank2RemainingGasVolume 100;
BA_ "GenSigCycleTimeActive" SG_ 1209 LngTank2RemainingGasVolume 100;
BA_ "GenSigStartValue" SG_ 1209 LngTank2RemainingGasVolume 255;
BA_ "GenSigMaxLatency" SG_ 1209 LngTank2RemainingGasVolume 1030;
BA_ "GenSigCycleTime" SG_ 1209 LNGRestrictionStatus_Spare4 100;
BA_ "GenSigCycleTimeActive" SG_ 1209 LNGRestrictionStatus_Spare4 100;
BA_ "GenSigMaxLatency" SG_ 1209 LNGRestrictionStatus_Spare4 1030;
BA_ "GenSigCycleTime" SG_ 1209 LNGRestrictionStatus_V1Closed 100;
BA_ "GenSigCycleTimeActive" SG_ 1209 LNGRestrictionStatus_V1Closed 100;
BA_ "GenSigMaxLatency" SG_ 1209 LNGRestrictionStatus_V1Closed 1030;
BA_ "GenSigCycleTime" SG_ 1209 LNGRestrictionStatus_Spare3 100;
BA_ "GenSigCycleTimeActive" SG_ 1209 LNGRestrictionStatus_Spare3 100;
BA_ "GenSigMaxLatency" SG_ 1209 LNGRestrictionStatus_Spare3 1030;
BA_ "GenSigCycleTime" SG_ 1209 LngTank2WarnStat 100;
BA_ "GenSigCycleTimeActive" SG_ 1209 LngTank2WarnStat 100;
BA_ "GenSigStartValue" SG_ 1209 LngTank2WarnStat 3;
BA_ "GenSigMaxLatency" SG_ 1209 LngTank2WarnStat 1030;
BA_ "GenSigCycleTime" SG_ 1209 LNGRestrictionStatus_Spare2 100;
BA_ "GenSigCycleTimeActive" SG_ 1209 LNGRestrictionStatus_Spare2 100;
BA_ "GenSigMaxLatency" SG_ 1209 LNGRestrictionStatus_Spare2 1030;
BA_ "GenSigCycleTime" SG_ 1209 LngTank1RemainingGasVolume 100;
BA_ "GenSigCycleTimeActive" SG_ 1209 LngTank1RemainingGasVolume 100;
BA_ "GenSigStartValue" SG_ 1209 LngTank1RemainingGasVolume 255;
BA_ "GenSigMaxLatency" SG_ 1209 LngTank1RemainingGasVolume 1030;
BA_ "GenSigCycleTime" SG_ 1209 LngSystemReadinessStat 100;
BA_ "GenSigCycleTimeActive" SG_ 1209 LngSystemReadinessStat 100;
BA_ "GenSigStartValue" SG_ 1209 LngSystemReadinessStat 7;
BA_ "GenSigMaxLatency" SG_ 1209 LngSystemReadinessStat 1030;
BA_ "GenSigCycleTime" SG_ 1209 LNGOperatorInducementReason 100;
BA_ "GenSigCycleTimeActive" SG_ 1209 LNGOperatorInducementReason 100;
BA_ "GenSigStartValue" SG_ 1209 LNGOperatorInducementReason 7;
BA_ "GenSigMaxLatency" SG_ 1209 LNGOperatorInducementReason 1030;
BA_ "GenSigCycleTime" SG_ 1209 LNGRestrictionStatus_Spare1 100;
BA_ "GenSigCycleTimeActive" SG_ 1209 LNGRestrictionStatus_Spare1 100;
BA_ "GenSigMaxLatency" SG_ 1209 LNGRestrictionStatus_Spare1 1030;
BA_ "GenSigCycleTime" SG_ 1209 LNGRestrictionStatus_V2Closed 100;
BA_ "GenSigCycleTimeActive" SG_ 1209 LNGRestrictionStatus_V2Closed 100;
BA_ "GenSigMaxLatency" SG_ 1209 LNGRestrictionStatus_V2Closed 1030;
BA_ "GenSigCycleTime" SG_ 1209 LngTank1WarnStat 100;
BA_ "GenSigCycleTimeActive" SG_ 1209 LngTank1WarnStat 100;
BA_ "GenSigStartValue" SG_ 1209 LngTank1WarnStat 3;
BA_ "GenSigMaxLatency" SG_ 1209 LngTank1WarnStat 1030;
BA_ "GenSigCycleTime" SG_ 1209 LNGTimeToVent 100;
BA_ "GenSigCycleTimeActive" SG_ 1209 LNGTimeToVent 100;
BA_ "GenSigStartValue" SG_ 1209 LNGTimeToVent 65535;
BA_ "GenSigMaxLatency" SG_ 1209 LNGTimeToVent 1030;
BA_ "GenSigCycleTime" SG_ 1209 LNGLevel 100;
BA_ "GenSigCycleTimeActive" SG_ 1209 LNGLevel 100;
BA_ "GenSigStartValue" SG_ 1209 LNGLevel 255;
BA_ "GenSigMaxLatency" SG_ 1209 LNGLevel 1030;
BA_ "GenSigCycleTime" SG_ 1209 LNGRestrictionStatus_SInfo 100;
BA_ "GenSigCycleTimeActive" SG_ 1209 LNGRestrictionStatus_SInfo 100;
BA_ "GenSigStartValue" SG_ 1209 LNGRestrictionStatus_SInfo 3;
BA_ "GenSigMaxLatency" SG_ 1209 LNGRestrictionStatus_SInfo 1030;
BA_ "GenSigCycleTime" SG_ 1209 LngGspWarnStat 100;
BA_ "GenSigCycleTimeActive" SG_ 1209 LngGspWarnStat 100;
BA_ "GenSigStartValue" SG_ 1209 LngGspWarnStat 3;
BA_ "GenSigMaxLatency" SG_ 1209 LngGspWarnStat 1030;
BA_ "GenSigCycleTime" SG_ 1208 EcoCruisePwtMaxUnSpeedLev3 100;
BA_ "GenSigCycleTimeActive" SG_ 1208 EcoCruisePwtMaxUnSpeedLev3 100;
BA_ "GenSigStartValue" SG_ 1208 EcoCruisePwtMaxUnSpeedLev3 31;
BA_ "GenSigMaxLatency" SG_ 1208 EcoCruisePwtMaxUnSpeedLev3 1020;
BA_ "GenSigCycleTime" SG_ 1208 EcoCruisePwtMaxOvSpeedLev0 100;
BA_ "GenSigCycleTimeActive" SG_ 1208 EcoCruisePwtMaxOvSpeedLev0 100;
BA_ "GenSigStartValue" SG_ 1208 EcoCruisePwtMaxOvSpeedLev0 31;
BA_ "GenSigMaxLatency" SG_ 1208 EcoCruisePwtMaxOvSpeedLev0 1020;
BA_ "GenSigCycleTime" SG_ 1208 EcoCruisePwtMaxUnSpeedLev1 100;
BA_ "GenSigCycleTimeActive" SG_ 1208 EcoCruisePwtMaxUnSpeedLev1 100;
BA_ "GenSigStartValue" SG_ 1208 EcoCruisePwtMaxUnSpeedLev1 31;
BA_ "GenSigMaxLatency" SG_ 1208 EcoCruisePwtMaxUnSpeedLev1 1020;
BA_ "GenSigCycleTime" SG_ 1208 EcoCruisePwtMaxOvSpeedLev2 100;
BA_ "GenSigCycleTimeActive" SG_ 1208 EcoCruisePwtMaxOvSpeedLev2 100;
BA_ "GenSigStartValue" SG_ 1208 EcoCruisePwtMaxOvSpeedLev2 31;
BA_ "GenSigMaxLatency" SG_ 1208 EcoCruisePwtMaxOvSpeedLev2 1020;
BA_ "GenSigCycleTime" SG_ 1208 EcoCruisePwtMaxUnSpeedLev0 100;
BA_ "GenSigCycleTimeActive" SG_ 1208 EcoCruisePwtMaxUnSpeedLev0 100;
BA_ "GenSigStartValue" SG_ 1208 EcoCruisePwtMaxUnSpeedLev0 31;
BA_ "GenSigMaxLatency" SG_ 1208 EcoCruisePwtMaxUnSpeedLev0 1020;
BA_ "GenSigCycleTime" SG_ 1208 EcoCruisePwtMaxOvSpeedLev1 100;
BA_ "GenSigCycleTimeActive" SG_ 1208 EcoCruisePwtMaxOvSpeedLev1 100;
BA_ "GenSigStartValue" SG_ 1208 EcoCruisePwtMaxOvSpeedLev1 31;
BA_ "GenSigMaxLatency" SG_ 1208 EcoCruisePwtMaxOvSpeedLev1 1020;
BA_ "GenSigCycleTime" SG_ 1208 EcoCruisePwtMaxUnSpeedLev2 100;
BA_ "GenSigCycleTimeActive" SG_ 1208 EcoCruisePwtMaxUnSpeedLev2 100;
BA_ "GenSigStartValue" SG_ 1208 EcoCruisePwtMaxUnSpeedLev2 31;
BA_ "GenSigMaxLatency" SG_ 1208 EcoCruisePwtMaxUnSpeedLev2 1020;
BA_ "GenSigCycleTime" SG_ 1208 EcoCruisePwtMaxOvSpeedLev3 100;
BA_ "GenSigCycleTimeActive" SG_ 1208 EcoCruisePwtMaxOvSpeedLev3 100;
BA_ "GenSigStartValue" SG_ 1208 EcoCruisePwtMaxOvSpeedLev3 31;
BA_ "GenSigMaxLatency" SG_ 1208 EcoCruisePwtMaxOvSpeedLev3 1020;
BA_ "GenSigCycleTime" SG_ 1207 EngineTotalLngConsumed 100;
BA_ "GenSigCycleTimeActive" SG_ 1207 EngineTotalLngConsumed 100;
BA_ "GenSigStartValue" SG_ 1207 EngineTotalLngConsumed 4294967295;
BA_ "GenSigMaxLatency" SG_ 1207 EngineTotalLngConsumed 1000;
BA_ "GenSigCycleTime" SG_ 1207 TotalVehicleDistanceHighRes 100;
BA_ "GenSigCycleTimeActive" SG_ 1207 TotalVehicleDistanceHighRes 100;
BA_ "GenSigStartValue" SG_ 1207 TotalVehicleDistanceHighRes 4294967295;
BA_ "GenSigMaxLatency" SG_ 1207 TotalVehicleDistanceHighRes 1000;
BA_ "GenSigCycleTime" SG_ 1206 PredictedMileageOfNextPadChg 100;
BA_ "GenSigCycleTimeActive" SG_ 1206 PredictedMileageOfNextPadChg 100;
BA_ "GenSigStartValue" SG_ 1206 PredictedMileageOfNextPadChg 4294967295;
BA_ "GenSigMaxLatency" SG_ 1206 PredictedMileageOfNextPadChg 1000;
BA_ "GenSigCycleTime" SG_ 1206 EngineRunningTime 100;
BA_ "GenSigCycleTimeActive" SG_ 1206 EngineRunningTime 100;
BA_ "GenSigStartValue" SG_ 1206 EngineRunningTime 4294967295;
BA_ "GenSigMaxLatency" SG_ 1206 EngineRunningTime 1000;
BA_ "GenSigCycleTime" SG_ 1205 TopGearUseDistance 100;
BA_ "GenSigCycleTimeActive" SG_ 1205 TopGearUseDistance 100;
BA_ "GenSigStartValue" SG_ 1205 TopGearUseDistance 4294967295;
BA_ "GenSigMaxLatency" SG_ 1205 TopGearUseDistance 1000;
BA_ "GenSigCycleTime" SG_ 1205 DPFSootLevel 100;
BA_ "GenSigCycleTimeActive" SG_ 1205 DPFSootLevel 100;
BA_ "GenSigStartValue" SG_ 1205 DPFSootLevel 255;
BA_ "GenSigMaxLatency" SG_ 1205 DPFSootLevel 1000;
BA_ "GenSigCycleTime" SG_ 1205 CatalystTankLevel 100;
BA_ "GenSigCycleTimeActive" SG_ 1205 CatalystTankLevel 100;
BA_ "GenSigStartValue" SG_ 1205 CatalystTankLevel 255;
BA_ "GenSigMaxLatency" SG_ 1205 CatalystTankLevel 1000;
BA_ "GenSigCycleTime" SG_ 1205 TransmissionOilTemp 100;
BA_ "GenSigCycleTimeActive" SG_ 1205 TransmissionOilTemp 100;
BA_ "GenSigStartValue" SG_ 1205 TransmissionOilTemp 65535;
BA_ "GenSigMaxLatency" SG_ 1205 TransmissionOilTemp 1000;
BA_ "GenSigCycleTime" SG_ 1204 TimeLeftToTorqueReductionFuel 100;
BA_ "GenSigCycleTimeActive" SG_ 1204 TimeLeftToTorqueReductionFuel 100;
BA_ "GenSigStartValue" SG_ 1204 TimeLeftToTorqueReductionFuel 511;
BA_ "GenSigMaxLatency" SG_ 1204 TimeLeftToTorqueReductionFuel 1000;
BA_ "GenSigCycleTime" SG_ 1204 TimeLeftToVehSpdReductionFuel 100;
BA_ "GenSigCycleTimeActive" SG_ 1204 TimeLeftToVehSpdReductionFuel 100;
BA_ "GenSigStartValue" SG_ 1204 TimeLeftToVehSpdReductionFuel 511;
BA_ "GenSigMaxLatency" SG_ 1204 TimeLeftToVehSpdReductionFuel 1000;
BA_ "GenSigCycleTime" SG_ 1204 TransmissionOilLevel 100;
BA_ "GenSigCycleTimeActive" SG_ 1204 TransmissionOilLevel 100;
BA_ "GenSigStartValue" SG_ 1204 TransmissionOilLevel 255;
BA_ "GenSigMaxLatency" SG_ 1204 TransmissionOilLevel 1000;
BA_ "GenSigCycleTime" SG_ 1204 TimeLeftToTorqueReduction_OBD 100;
BA_ "GenSigCycleTimeActive" SG_ 1204 TimeLeftToTorqueReduction_OBD 100;
BA_ "GenSigStartValue" SG_ 1204 TimeLeftToTorqueReduction_OBD 511;
BA_ "GenSigMaxLatency" SG_ 1204 TimeLeftToTorqueReduction_OBD 1000;
BA_ "GenSigCycleTime" SG_ 1204 TimetoCompleteParkRegen 100;
BA_ "GenSigCycleTimeActive" SG_ 1204 TimetoCompleteParkRegen 100;
BA_ "GenSigStartValue" SG_ 1204 TimetoCompleteParkRegen 511;
BA_ "GenSigMaxLatency" SG_ 1204 TimetoCompleteParkRegen 1000;
BA_ "GenSigCycleTime" SG_ 1204 TimeLeftToVehSpdReduction_OBD 100;
BA_ "GenSigCycleTimeActive" SG_ 1204 TimeLeftToVehSpdReduction_OBD 100;
BA_ "GenSigStartValue" SG_ 1204 TimeLeftToVehSpdReduction_OBD 511;
BA_ "GenSigMaxLatency" SG_ 1204 TimeLeftToVehSpdReduction_OBD 1000;
BA_ "GenSigCycleTime" SG_ 1203 AdBlueTankTemperature 100;
BA_ "GenSigCycleTimeActive" SG_ 1203 AdBlueTankTemperature 100;
BA_ "GenSigStartValue" SG_ 1203 AdBlueTankTemperature 255;
BA_ "GenSigMaxLatency" SG_ 1203 AdBlueTankTemperature 1000;
BA_ "GenSigCycleTime" SG_ 1203 RearDriveAxle2Temperature 100;
BA_ "GenSigCycleTimeActive" SG_ 1203 RearDriveAxle2Temperature 100;
BA_ "GenSigStartValue" SG_ 1203 RearDriveAxle2Temperature 255;
BA_ "GenSigMaxLatency" SG_ 1203 RearDriveAxle2Temperature 1000;
BA_ "GenSigCycleTime" SG_ 1203 DistLeftToSevereInducement_OBD 100;
BA_ "GenSigCycleTimeActive" SG_ 1203 DistLeftToSevereInducement_OBD 100;
BA_ "GenSigStartValue" SG_ 1203 DistLeftToSevereInducement_OBD 255;
BA_ "GenSigMaxLatency" SG_ 1203 DistLeftToSevereInducement_OBD 1000;
BA_ "GenSigCycleTime" SG_ 1203 RearDriveAxle3Temperature 100;
BA_ "GenSigCycleTimeActive" SG_ 1203 RearDriveAxle3Temperature 100;
BA_ "GenSigStartValue" SG_ 1203 RearDriveAxle3Temperature 255;
BA_ "GenSigMaxLatency" SG_ 1203 RearDriveAxle3Temperature 1000;
BA_ "GenSigCycleTime" SG_ 1203 RearDriveAxle1Temperature 100;
BA_ "GenSigCycleTimeActive" SG_ 1203 RearDriveAxle1Temperature 100;
BA_ "GenSigStartValue" SG_ 1203 RearDriveAxle1Temperature 255;
BA_ "GenSigMaxLatency" SG_ 1203 RearDriveAxle1Temperature 1000;
BA_ "GenSigCycleTime" SG_ 1203 AmbientAirTemperature 100;
BA_ "GenSigCycleTimeActive" SG_ 1203 AmbientAirTemperature 100;
BA_ "GenSigStartValue" SG_ 1203 AmbientAirTemperature 65535;
BA_ "GenSigMaxLatency" SG_ 1203 AmbientAirTemperature 1000;
BA_ "GenSigCycleTime" SG_ 1203 EngineCoolantTemp_stat 100;
BA_ "GenSigCycleTimeActive" SG_ 1203 EngineCoolantTemp_stat 100;
BA_ "GenSigStartValue" SG_ 1203 EngineCoolantTemp_stat 255;
BA_ "GenSigMaxLatency" SG_ 1203 EngineCoolantTemp_stat 1000;
BA_ "GenSigCycleTime" SG_ 1202 FasUsrDefinedDampingSetting 100;
BA_ "GenSigCycleTimeActive" SG_ 1202 FasUsrDefinedDampingSetting 100;
BA_ "GenSigStartValue" SG_ 1202 FasUsrDefinedDampingSetting 31;
BA_ "GenSigMaxLatency" SG_ 1202 FasUsrDefinedDampingSetting 1000;
BA_ "GenSigCycleTime" SG_ 1202 SCROperatorInducementSeverity 100;
BA_ "GenSigCycleTimeActive" SG_ 1202 SCROperatorInducementSeverity 100;
BA_ "GenSigStartValue" SG_ 1202 SCROperatorInducementSeverity 7;
BA_ "GenSigMaxLatency" SG_ 1202 SCROperatorInducementSeverity 1000;
BA_ "GenSigCycleTime" SG_ 1202 CatalystTankLevelLow 100;
BA_ "GenSigCycleTimeActive" SG_ 1202 CatalystTankLevelLow 100;
BA_ "GenSigStartValue" SG_ 1202 CatalystTankLevelLow 3;
BA_ "GenSigMaxLatency" SG_ 1202 CatalystTankLevelLow 1000;
BA_ "GenSigCycleTime" SG_ 1202 MIStatusExtEMS 100;
BA_ "GenSigCycleTimeActive" SG_ 1202 MIStatusExtEMS 100;
BA_ "GenSigStartValue" SG_ 1202 MIStatusExtEMS 3;
BA_ "GenSigMaxLatency" SG_ 1202 MIStatusExtEMS 1000;
BA_ "GenSigCycleTime" SG_ 1202 FuelOperatorDeratingReason 100;
BA_ "GenSigCycleTimeActive" SG_ 1202 FuelOperatorDeratingReason 100;
BA_ "GenSigStartValue" SG_ 1202 FuelOperatorDeratingReason 3;
BA_ "GenSigMaxLatency" SG_ 1202 FuelOperatorDeratingReason 1000;
BA_ "GenSigCycleTime" SG_ 1202 ActualFasPersSettingsButton 100;
BA_ "GenSigCycleTimeActive" SG_ 1202 ActualFasPersSettingsButton 100;
BA_ "GenSigStartValue" SG_ 1202 ActualFasPersSettingsButton 7;
BA_ "GenSigMaxLatency" SG_ 1202 ActualFasPersSettingsButton 1000;
BA_ "GenSigCycleTime" SG_ 1202 BatteryEndOfCharge 100;
BA_ "GenSigCycleTimeActive" SG_ 1202 BatteryEndOfCharge 100;
BA_ "GenSigStartValue" SG_ 1202 BatteryEndOfCharge 3;
BA_ "GenSigMaxLatency" SG_ 1202 BatteryEndOfCharge 1000;
BA_ "GenSigCycleTime" SG_ 1202 FasUsrDefStiffStraightSetting 100;
BA_ "GenSigCycleTimeActive" SG_ 1202 FasUsrDefStiffStraightSetting 100;
BA_ "GenSigStartValue" SG_ 1202 FasUsrDefStiffStraightSetting 31;
BA_ "GenSigMaxLatency" SG_ 1202 FasUsrDefStiffStraightSetting 1000;
BA_ "GenSigCycleTime" SG_ 1202 LiningWearWarning 100;
BA_ "GenSigCycleTimeActive" SG_ 1202 LiningWearWarning 100;
BA_ "GenSigStartValue" SG_ 1202 LiningWearWarning 3;
BA_ "GenSigMaxLatency" SG_ 1202 LiningWearWarning 1000;
BA_ "GenSigCycleTime" SG_ 1202 TorqueReductionStatus_OBD 100;
BA_ "GenSigCycleTimeActive" SG_ 1202 TorqueReductionStatus_OBD 100;
BA_ "GenSigStartValue" SG_ 1202 TorqueReductionStatus_OBD 7;
BA_ "GenSigMaxLatency" SG_ 1202 TorqueReductionStatus_OBD 1000;
BA_ "GenSigCycleTime" SG_ 1202 LoadCalibrationFeedback 100;
BA_ "GenSigCycleTimeActive" SG_ 1202 LoadCalibrationFeedback 100;
BA_ "GenSigStartValue" SG_ 1202 LoadCalibrationFeedback 7;
BA_ "GenSigMaxLatency" SG_ 1202 LoadCalibrationFeedback 1000;
BA_ "GenSigCycleTime" SG_ 1202 FasUsrDefLowSpeedReturnSetting 100;
BA_ "GenSigCycleTimeActive" SG_ 1202 FasUsrDefLowSpeedReturnSetting 100;
BA_ "GenSigStartValue" SG_ 1202 FasUsrDefLowSpeedReturnSetting 31;
BA_ "GenSigMaxLatency" SG_ 1202 FasUsrDefLowSpeedReturnSetting 1000;
BA_ "GenSigCycleTime" SG_ 1202 FuelOperatorDeratingSeverity 100;
BA_ "GenSigCycleTimeActive" SG_ 1202 FuelOperatorDeratingSeverity 100;
BA_ "GenSigStartValue" SG_ 1202 FuelOperatorDeratingSeverity 7;
BA_ "GenSigMaxLatency" SG_ 1202 FuelOperatorDeratingSeverity 1000;
BA_ "GenSigCycleTime" SG_ 1202 FasUsrDefStiffnessCurveSetting 100;
BA_ "GenSigCycleTimeActive" SG_ 1202 FasUsrDefStiffnessCurveSetting 100;
BA_ "GenSigStartValue" SG_ 1202 FasUsrDefStiffnessCurveSetting 31;
BA_ "GenSigMaxLatency" SG_ 1202 FasUsrDefStiffnessCurveSetting 1000;
BA_ "GenSigCycleTime" SG_ 1202 SCROperatorInducementReason 100;
BA_ "GenSigCycleTimeActive" SG_ 1202 SCROperatorInducementReason 100;
BA_ "GenSigStartValue" SG_ 1202 SCROperatorInducementReason 7;
BA_ "GenSigMaxLatency" SG_ 1202 SCROperatorInducementReason 1000;
BA_ "GenSigCycleTime" SG_ 1202 ActualFasManualOffsetSetting 100;
BA_ "GenSigCycleTimeActive" SG_ 1202 ActualFasManualOffsetSetting 100;
BA_ "GenSigStartValue" SG_ 1202 ActualFasManualOffsetSetting 31;
BA_ "GenSigMaxLatency" SG_ 1202 ActualFasManualOffsetSetting 1000;
BA_ "GenSigCycleTime" SG_ 1202 MIDistinctWarningExtEMS 100;
BA_ "GenSigCycleTimeActive" SG_ 1202 MIDistinctWarningExtEMS 100;
BA_ "GenSigStartValue" SG_ 1202 MIDistinctWarningExtEMS 15;
BA_ "GenSigMaxLatency" SG_ 1202 MIDistinctWarningExtEMS 1000;
BA_ "GenSigCycleTime" SG_ 1202 FasDriver 100;
BA_ "GenSigCycleTimeActive" SG_ 1202 FasDriver 100;
BA_ "GenSigStartValue" SG_ 1202 FasDriver 15;
BA_ "GenSigMaxLatency" SG_ 1202 FasDriver 1000;
BA_ "GenSigCycleTime" SG_ 1202 MIDistinctWarning 100;
BA_ "GenSigCycleTimeActive" SG_ 1202 MIDistinctWarning 100;
BA_ "GenSigStartValue" SG_ 1202 MIDistinctWarning 3;
BA_ "GenSigMaxLatency" SG_ 1202 MIDistinctWarning 1000;
BA_ "GenSigCycleTime" SG_ 1201 DiagFaultStat_BBIOM_DtcIdB 100;
BA_ "GenSigCycleTimeActive" SG_ 1201 DiagFaultStat_BBIOM_DtcIdB 100;
BA_ "GenSigStartValue" SG_ 1201 DiagFaultStat_BBIOM_DtcIdB 65535;
BA_ "GenSigMaxLatency" SG_ 1201 DiagFaultStat_BBIOM_DtcIdB 1000;
BA_ "NeedsUpdateBit" SG_ 1201 DiagFaultStat_BBIOM_DtcIdB 1;
BA_ "GenSigCycleTime" SG_ 1201 DiagFaultStat_BBIOM_DtcIdA 100;
BA_ "GenSigCycleTimeActive" SG_ 1201 DiagFaultStat_BBIOM_DtcIdA 100;
BA_ "GenSigStartValue" SG_ 1201 DiagFaultStat_BBIOM_DtcIdA 65535;
BA_ "GenSigMaxLatency" SG_ 1201 DiagFaultStat_BBIOM_DtcIdA 1000;
BA_ "NeedsUpdateBit" SG_ 1201 DiagFaultStat_BBIOM_DtcIdA 1;
BA_ "GenSigCycleTime" SG_ 1201 DiagFaultStat_BBIOM_FailTB 100;
BA_ "GenSigCycleTimeActive" SG_ 1201 DiagFaultStat_BBIOM_FailTB 100;
BA_ "GenSigStartValue" SG_ 1201 DiagFaultStat_BBIOM_FailTB 255;
BA_ "GenSigMaxLatency" SG_ 1201 DiagFaultStat_BBIOM_FailTB 1000;
BA_ "NeedsUpdateBit" SG_ 1201 DiagFaultStat_BBIOM_FailTB 1;
BA_ "GenSigCycleTime" SG_ 1201 DiagFaultStat_BBIOM_FailTA 100;
BA_ "GenSigCycleTimeActive" SG_ 1201 DiagFaultStat_BBIOM_FailTA 100;
BA_ "GenSigStartValue" SG_ 1201 DiagFaultStat_BBIOM_FailTA 255;
BA_ "GenSigMaxLatency" SG_ 1201 DiagFaultStat_BBIOM_FailTA 1000;
BA_ "NeedsUpdateBit" SG_ 1201 DiagFaultStat_BBIOM_FailTA 1;
BA_ "GenSigCycleTime" SG_ 1201 DiagFaultStat_BBIOM_EcuAdr 100;
BA_ "GenSigCycleTimeActive" SG_ 1201 DiagFaultStat_BBIOM_EcuAdr 100;
BA_ "GenSigStartValue" SG_ 1201 DiagFaultStat_BBIOM_EcuAdr 255;
BA_ "GenSigMaxLatency" SG_ 1201 DiagFaultStat_BBIOM_EcuAdr 1000;
BA_ "NeedsUpdateBit" SG_ 1201 DiagFaultStat_BBIOM_EcuAdr 1;
BA_ "GenSigSendType" SG_ 1201 DiagFaultStat_BBIOM_sg_UB 7;
BA_ "GenSigCycleTime" SG_ 903 ManTransmiOilTemp 100;
BA_ "GenSigCycleTimeActive" SG_ 903 ManTransmiOilTemp 100;
BA_ "GenSigStartValue" SG_ 903 ManTransmiOilTemp 65535;
BA_ "GenSigMaxLatency" SG_ 903 ManTransmiOilTemp 500;
BA_ "GenSigCycleTime" SG_ 903 EngineTurbo1BoostPressure 100;
BA_ "GenSigCycleTimeActive" SG_ 903 EngineTurbo1BoostPressure 100;
BA_ "GenSigStartValue" SG_ 903 EngineTurbo1BoostPressure 65535;
BA_ "GenSigMaxLatency" SG_ 903 EngineTurbo1BoostPressure 500;
BA_ "GenSigCycleTime" SG_ 903 LastDriveAxleBellowPressure 100;
BA_ "GenSigCycleTimeActive" SG_ 903 LastDriveAxleBellowPressure 100;
BA_ "GenSigStartValue" SG_ 903 LastDriveAxleBellowPressure 65535;
BA_ "GenSigMaxLatency" SG_ 903 LastDriveAxleBellowPressure 500;
BA_ "GenSigCycleTime" SG_ 902 Cur_LG5CutoffValue 100;
BA_ "GenSigCycleTimeActive" SG_ 902 Cur_LG5CutoffValue 100;
BA_ "GenSigStartValue" SG_ 902 Cur_LG5CutoffValue 255;
BA_ "GenSigMaxLatency" SG_ 902 Cur_LG5CutoffValue 500;
BA_ "GenSigCycleTime" SG_ 902 Cur_LG4CutoffValue 100;
BA_ "GenSigCycleTimeActive" SG_ 902 Cur_LG4CutoffValue 100;
BA_ "GenSigStartValue" SG_ 902 Cur_LG4CutoffValue 255;
BA_ "GenSigMaxLatency" SG_ 902 Cur_LG4CutoffValue 500;
BA_ "GenSigCycleTime" SG_ 902 Cur_LG1CutoffValue 100;
BA_ "GenSigCycleTimeActive" SG_ 902 Cur_LG1CutoffValue 100;
BA_ "GenSigStartValue" SG_ 902 Cur_LG1CutoffValue 255;
BA_ "GenSigMaxLatency" SG_ 902 Cur_LG1CutoffValue 500;
BA_ "GenSigCycleTime" SG_ 902 Cur_LG2CutoffValue 100;
BA_ "GenSigCycleTimeActive" SG_ 902 Cur_LG2CutoffValue 100;
BA_ "GenSigStartValue" SG_ 902 Cur_LG2CutoffValue 255;
BA_ "GenSigMaxLatency" SG_ 902 Cur_LG2CutoffValue 500;
BA_ "GenSigCycleTime" SG_ 902 Cur_EnergySetting 100;
BA_ "GenSigCycleTimeActive" SG_ 902 Cur_EnergySetting 100;
BA_ "GenSigStartValue" SG_ 902 Cur_EnergySetting 7;
BA_ "GenSigMaxLatency" SG_ 902 Cur_EnergySetting 500;
BA_ "GenSigCycleTime" SG_ 902 UltracapDisplay_Stat 100;
BA_ "GenSigCycleTimeActive" SG_ 902 UltracapDisplay_Stat 100;
BA_ "GenSigStartValue" SG_ 902 UltracapDisplay_Stat 7;
BA_ "GenSigMaxLatency" SG_ 902 UltracapDisplay_Stat 500;
BA_ "GenSigCycleTime" SG_ 902 Cur_LG6CutoffValue 100;
BA_ "GenSigCycleTimeActive" SG_ 902 Cur_LG6CutoffValue 100;
BA_ "GenSigStartValue" SG_ 902 Cur_LG6CutoffValue 255;
BA_ "GenSigMaxLatency" SG_ 902 Cur_LG6CutoffValue 500;
BA_ "GenSigCycleTime" SG_ 902 Cur_LG3CutoffValue 100;
BA_ "GenSigCycleTimeActive" SG_ 902 Cur_LG3CutoffValue 100;
BA_ "GenSigStartValue" SG_ 902 Cur_LG3CutoffValue 255;
BA_ "GenSigMaxLatency" SG_ 902 Cur_LG3CutoffValue 500;
BA_ "GenSigCycleTime" SG_ 902 Ultracap_Status 100;
BA_ "GenSigCycleTimeActive" SG_ 902 Ultracap_Status 100;
BA_ "GenSigStartValue" SG_ 902 Ultracap_Status 7;
BA_ "GenSigMaxLatency" SG_ 902 Ultracap_Status 500;
BA_ "GenSigCycleTime" SG_ 901 AxleLoadStatus 100;
BA_ "GenSigCycleTimeActive" SG_ 901 AxleLoadStatus 100;
BA_ "GenSigStartValue" SG_ 901 AxleLoadStatus 7;
BA_ "GenSigMaxLatency" SG_ 901 AxleLoadStatus 500;
BA_ "GenSigCycleTime" SG_ 901 ClutchAbuseStatus 100;
BA_ "GenSigCycleTimeActive" SG_ 901 ClutchAbuseStatus 100;
BA_ "GenSigStartValue" SG_ 901 ClutchAbuseStatus 3;
BA_ "GenSigMaxLatency" SG_ 901 ClutchAbuseStatus 500;
BA_ "GenSigCycleTime" SG_ 901 ISeeStatus 100;
BA_ "GenSigCycleTimeActive" SG_ 901 ISeeStatus 100;
BA_ "GenSigStartValue" SG_ 901 ISeeStatus 7;
BA_ "GenSigMaxLatency" SG_ 901 ISeeStatus 500;
BA_ "GenSigCycleTime" SG_ 901 TransmissionSplitboxPTOMode 100;
BA_ "GenSigCycleTimeActive" SG_ 901 TransmissionSplitboxPTOMode 100;
BA_ "GenSigStartValue" SG_ 901 TransmissionSplitboxPTOMode 7;
BA_ "GenSigMaxLatency" SG_ 901 TransmissionSplitboxPTOMode 500;
BA_ "GenSigCycleTime" SG_ 901 OilLevelDrvInstr_IncorrEngSpe 100;
BA_ "GenSigCycleTimeActive" SG_ 901 OilLevelDrvInstr_IncorrEngSpe 100;
BA_ "GenSigStartValue" SG_ 901 OilLevelDrvInstr_IncorrEngSpe 3;
BA_ "GenSigMaxLatency" SG_ 901 OilLevelDrvInstr_IncorrEngSpe 500;
BA_ "GenSigCycleTime" SG_ 901 OilLevelDrvInstr_ChangeGearTxt 100;
BA_ "GenSigCycleTimeActive" SG_ 901 OilLevelDrvInstr_ChangeGearTxt 100;
BA_ "GenSigStartValue" SG_ 901 OilLevelDrvInstr_ChangeGearTxt 3;
BA_ "GenSigMaxLatency" SG_ 901 OilLevelDrvInstr_ChangeGearTxt 500;
BA_ "GenSigCycleTime" SG_ 901 PredeliveryModeIndication_cmd 100;
BA_ "GenSigCycleTimeActive" SG_ 901 PredeliveryModeIndication_cmd 100;
BA_ "GenSigStartValue" SG_ 901 PredeliveryModeIndication_cmd 3;
BA_ "GenSigMaxLatency" SG_ 901 PredeliveryModeIndication_cmd 500;
BA_ "GenSigCycleTime" SG_ 901 OilLevelDrvInstr_Wait60SecTxt 100;
BA_ "GenSigCycleTimeActive" SG_ 901 OilLevelDrvInstr_Wait60SecTxt 100;
BA_ "GenSigStartValue" SG_ 901 OilLevelDrvInstr_Wait60SecTxt 3;
BA_ "GenSigMaxLatency" SG_ 901 OilLevelDrvInstr_Wait60SecTxt 500;
BA_ "GenSigCycleTime" SG_ 901 DPF_LimitedSpeedDuetoInhibit 100;
BA_ "GenSigCycleTimeActive" SG_ 901 DPF_LimitedSpeedDuetoInhibit 100;
BA_ "GenSigStartValue" SG_ 901 DPF_LimitedSpeedDuetoInhibit 7;
BA_ "GenSigMaxLatency" SG_ 901 DPF_LimitedSpeedDuetoInhibit 500;
BA_ "GenSigCycleTime" SG_ 901 DPF_ParkedRegenStatus 100;
BA_ "GenSigCycleTimeActive" SG_ 901 DPF_ParkedRegenStatus 100;
BA_ "GenSigStartValue" SG_ 901 DPF_ParkedRegenStatus 7;
BA_ "GenSigMaxLatency" SG_ 901 DPF_ParkedRegenStatus 500;
BA_ "GenSigCycleTime" SG_ 901 OilLevelDrvInstr_OilTempTxt 100;
BA_ "GenSigCycleTimeActive" SG_ 901 OilLevelDrvInstr_OilTempTxt 100;
BA_ "GenSigStartValue" SG_ 901 OilLevelDrvInstr_OilTempTxt 3;
BA_ "GenSigMaxLatency" SG_ 901 OilLevelDrvInstr_OilTempTxt 500;
BA_ "GenSigCycleTime" SG_ 901 OilLevelDrvInstr_StopVehicle 100;
BA_ "GenSigCycleTimeActive" SG_ 901 OilLevelDrvInstr_StopVehicle 100;
BA_ "GenSigStartValue" SG_ 901 OilLevelDrvInstr_StopVehicle 3;
BA_ "GenSigMaxLatency" SG_ 901 OilLevelDrvInstr_StopVehicle 500;
BA_ "GenSigCycleTime" SG_ 901 ClutchCalibration_stat 100;
BA_ "GenSigCycleTimeActive" SG_ 901 ClutchCalibration_stat 100;
BA_ "GenSigStartValue" SG_ 901 ClutchCalibration_stat 3;
BA_ "GenSigMaxLatency" SG_ 901 ClutchCalibration_stat 500;
BA_ "GenSigCycleTime" SG_ 901 FuelVolume 100;
BA_ "GenSigCycleTimeActive" SG_ 901 FuelVolume 100;
BA_ "GenSigStartValue" SG_ 901 FuelVolume 2047;
BA_ "GenSigMaxLatency" SG_ 901 FuelVolume 500;
BA_ "GenSigCycleTime" SG_ 901 OilLevelDrvInstr_NotHorizonTxt 100;
BA_ "GenSigCycleTimeActive" SG_ 901 OilLevelDrvInstr_NotHorizonTxt 100;
BA_ "GenSigStartValue" SG_ 901 OilLevelDrvInstr_NotHorizonTxt 3;
BA_ "GenSigMaxLatency" SG_ 901 OilLevelDrvInstr_NotHorizonTxt 500;
BA_ "GenSigCycleTime" SG_ 901 FuelLevel 100;
BA_ "GenSigCycleTimeActive" SG_ 901 FuelLevel 100;
BA_ "GenSigStartValue" SG_ 901 FuelLevel 255;
BA_ "GenSigMaxLatency" SG_ 901 FuelLevel 500;
BA_ "GenSigCycleTime" SG_ 868 DrainPrimingStatus 100;
BA_ "GenSigCycleTimeActive" SG_ 868 DrainPrimingStatus 100;
BA_ "GenSigStartValue" SG_ 868 DrainPrimingStatus 7;
BA_ "GenSigMaxLatency" SG_ 868 DrainPrimingStatus 250;
BA_ "GenSigCycleTime" SG_ 868 FrontConspicLamp_stat_HiRight 100;
BA_ "GenSigCycleTimeActive" SG_ 868 FrontConspicLamp_stat_HiRight 100;
BA_ "GenSigStartValue" SG_ 868 FrontConspicLamp_stat_HiRight 7;
BA_ "GenSigMaxLatency" SG_ 868 FrontConspicLamp_stat_HiRight 250;
BA_ "GenSigCycleTime" SG_ 868 FrontConspicLamp_stat_LoRight 100;
BA_ "GenSigCycleTimeActive" SG_ 868 FrontConspicLamp_stat_LoRight 100;
BA_ "GenSigStartValue" SG_ 868 FrontConspicLamp_stat_LoRight 7;
BA_ "GenSigMaxLatency" SG_ 868 FrontConspicLamp_stat_LoRight 250;
BA_ "GenSigCycleTime" SG_ 868 CoolantTempHigh 100;
BA_ "GenSigCycleTimeActive" SG_ 868 CoolantTempHigh 100;
BA_ "GenSigStartValue" SG_ 868 CoolantTempHigh 7;
BA_ "GenSigMaxLatency" SG_ 868 CoolantTempHigh 250;
BA_ "GenSigCycleTime" SG_ 868 AutoWheelBrakesStatus 100;
BA_ "GenSigCycleTimeActive" SG_ 868 AutoWheelBrakesStatus 100;
BA_ "GenSigStartValue" SG_ 868 AutoWheelBrakesStatus 7;
BA_ "GenSigMaxLatency" SG_ 868 AutoWheelBrakesStatus 250;
BA_ "GenSigCycleTime" SG_ 868 OilLevelLow 100;
BA_ "GenSigCycleTimeActive" SG_ 868 OilLevelLow 100;
BA_ "GenSigStartValue" SG_ 868 OilLevelLow 7;
BA_ "GenSigMaxLatency" SG_ 868 OilLevelLow 250;
BA_ "GenSigCycleTime" SG_ 868 InletAirHeaterStatus1 100;
BA_ "GenSigCycleTimeActive" SG_ 868 InletAirHeaterStatus1 100;
BA_ "GenSigStartValue" SG_ 868 InletAirHeaterStatus1 3;
BA_ "GenSigMaxLatency" SG_ 868 InletAirHeaterStatus1 250;
BA_ "GenSigCycleTime" SG_ 868 DeicingFunction_Stat 100;
BA_ "GenSigCycleTimeActive" SG_ 868 DeicingFunction_Stat 100;
BA_ "GenSigStartValue" SG_ 868 DeicingFunction_Stat 7;
BA_ "GenSigMaxLatency" SG_ 868 DeicingFunction_Stat 250;
BA_ "GenSigCycleTime" SG_ 868 SelfStartAssist_stat 100;
BA_ "GenSigCycleTimeActive" SG_ 868 SelfStartAssist_stat 100;
BA_ "GenSigStartValue" SG_ 868 SelfStartAssist_stat 3;
BA_ "GenSigMaxLatency" SG_ 868 SelfStartAssist_stat 250;
BA_ "GenSigCycleTime" SG_ 868 TrailerDirIndLeftOutputStat 100;
BA_ "GenSigCycleTimeActive" SG_ 868 TrailerDirIndLeftOutputStat 100;
BA_ "GenSigStartValue" SG_ 868 TrailerDirIndLeftOutputStat 7;
BA_ "GenSigMaxLatency" SG_ 868 TrailerDirIndLeftOutputStat 250;
BA_ "GenSigCycleTime" SG_ 868 TrailerPosLightLeftOutputStat 100;
BA_ "GenSigCycleTimeActive" SG_ 868 TrailerPosLightLeftOutputStat 100;
BA_ "GenSigStartValue" SG_ 868 TrailerPosLightLeftOutputStat 7;
BA_ "GenSigMaxLatency" SG_ 868 TrailerPosLightLeftOutputStat 250;
BA_ "GenSigCycleTime" SG_ 868 TrailerBrakeLightOutputStat 100;
BA_ "GenSigCycleTimeActive" SG_ 868 TrailerBrakeLightOutputStat 100;
BA_ "GenSigStartValue" SG_ 868 TrailerBrakeLightOutputStat 7;
BA_ "GenSigMaxLatency" SG_ 868 TrailerBrakeLightOutputStat 250;
BA_ "GenSigCycleTime" SG_ 868 StartBatteryDisplay_stat 100;
BA_ "GenSigCycleTimeActive" SG_ 868 StartBatteryDisplay_stat 100;
BA_ "GenSigStartValue" SG_ 868 StartBatteryDisplay_stat 7;
BA_ "GenSigMaxLatency" SG_ 868 StartBatteryDisplay_stat 250;
BA_ "GenSigCycleTime" SG_ 868 DeicingBulb_Stat 100;
BA_ "GenSigCycleTimeActive" SG_ 868 DeicingBulb_Stat 100;
BA_ "GenSigStartValue" SG_ 868 DeicingBulb_Stat 7;
BA_ "GenSigMaxLatency" SG_ 868 DeicingBulb_Stat 250;
BA_ "GenSigCycleTime" SG_ 868 LivBatDisconnectDetectStat 100;
BA_ "GenSigCycleTimeActive" SG_ 868 LivBatDisconnectDetectStat 100;
BA_ "GenSigStartValue" SG_ 868 LivBatDisconnectDetectStat 3;
BA_ "GenSigMaxLatency" SG_ 868 LivBatDisconnectDetectStat 250;
BA_ "GenSigCycleTime" SG_ 868 FrontConspicLamp_stat_LoLeft 100;
BA_ "GenSigCycleTimeActive" SG_ 868 FrontConspicLamp_stat_LoLeft 100;
BA_ "GenSigStartValue" SG_ 868 FrontConspicLamp_stat_LoLeft 7;
BA_ "GenSigMaxLatency" SG_ 868 FrontConspicLamp_stat_LoLeft 250;
BA_ "GenSigCycleTime" SG_ 868 FuelFilterClogged 100;
BA_ "GenSigCycleTimeActive" SG_ 868 FuelFilterClogged 100;
BA_ "GenSigStartValue" SG_ 868 FuelFilterClogged 7;
BA_ "GenSigMaxLatency" SG_ 868 FuelFilterClogged 250;
BA_ "GenSigCycleTime" SG_ 868 EngineFanOverspeed 100;
BA_ "GenSigCycleTimeActive" SG_ 868 EngineFanOverspeed 100;
BA_ "GenSigStartValue" SG_ 868 EngineFanOverspeed 3;
BA_ "GenSigMaxLatency" SG_ 868 EngineFanOverspeed 250;
BA_ "GenSigCycleTime" SG_ 868 JumpChargeInterface_stat 100;
BA_ "GenSigCycleTimeActive" SG_ 868 JumpChargeInterface_stat 100;
BA_ "GenSigStartValue" SG_ 868 JumpChargeInterface_stat 3;
BA_ "GenSigMaxLatency" SG_ 868 JumpChargeInterface_stat 250;
BA_ "GenSigCycleTime" SG_ 868 OilPressureLow 100;
BA_ "GenSigCycleTimeActive" SG_ 868 OilPressureLow 100;
BA_ "GenSigStartValue" SG_ 868 OilPressureLow 7;
BA_ "GenSigMaxLatency" SG_ 868 OilPressureLow 250;
BA_ "GenSigCycleTime" SG_ 868 FrontConspicLamp_stat_HiLeft 100;
BA_ "GenSigCycleTimeActive" SG_ 868 FrontConspicLamp_stat_HiLeft 100;
BA_ "GenSigStartValue" SG_ 868 FrontConspicLamp_stat_HiLeft 7;
BA_ "GenSigMaxLatency" SG_ 868 FrontConspicLamp_stat_HiLeft 250;
BA_ "GenSigCycleTime" SG_ 868 GChargerStatus 100;
BA_ "GenSigCycleTimeActive" SG_ 868 GChargerStatus 100;
BA_ "GenSigStartValue" SG_ 868 GChargerStatus 7;
BA_ "GenSigMaxLatency" SG_ 868 GChargerStatus 250;
BA_ "GenSigCycleTime" SG_ 868 TrailerRevAndFogOutput_stat 100;
BA_ "GenSigCycleTimeActive" SG_ 868 TrailerRevAndFogOutput_stat 100;
BA_ "GenSigStartValue" SG_ 868 TrailerRevAndFogOutput_stat 3;
BA_ "GenSigMaxLatency" SG_ 868 TrailerRevAndFogOutput_stat 250;
BA_ "GenSigCycleTime" SG_ 867 DirIndSideLamp_stat 100;
BA_ "GenSigCycleTimeActive" SG_ 867 DirIndSideLamp_stat 100;
BA_ "GenSigStartValue" SG_ 867 DirIndSideLamp_stat 7;
BA_ "GenSigMaxLatency" SG_ 867 DirIndSideLamp_stat 250;
BA_ "GenSigCycleTime" SG_ 867 DirInd_Front_Status 100;
BA_ "GenSigCycleTimeActive" SG_ 867 DirInd_Front_Status 100;
BA_ "GenSigStartValue" SG_ 867 DirInd_Front_Status 7;
BA_ "GenSigMaxLatency" SG_ 867 DirInd_Front_Status 250;
BA_ "GenSigCycleTime" SG_ 867 FogLightFrontLamp_stat 100;
BA_ "GenSigCycleTimeActive" SG_ 867 FogLightFrontLamp_stat 100;
BA_ "GenSigStartValue" SG_ 867 FogLightFrontLamp_stat 7;
BA_ "GenSigMaxLatency" SG_ 867 FogLightFrontLamp_stat 250;
BA_ "GenSigCycleTime" SG_ 867 MainBeamLEDStatusRight 100;
BA_ "GenSigCycleTimeActive" SG_ 867 MainBeamLEDStatusRight 100;
BA_ "GenSigStartValue" SG_ 867 MainBeamLEDStatusRight 7;
BA_ "GenSigMaxLatency" SG_ 867 MainBeamLEDStatusRight 250;
BA_ "GenSigCycleTime" SG_ 867 RevLightLamp_stat 100;
BA_ "GenSigCycleTimeActive" SG_ 867 RevLightLamp_stat 100;
BA_ "GenSigStartValue" SG_ 867 RevLightLamp_stat 7;
BA_ "GenSigMaxLatency" SG_ 867 RevLightLamp_stat 250;
BA_ "GenSigCycleTime" SG_ 867 ExtraMainBeamLamp_stat 100;
BA_ "GenSigCycleTimeActive" SG_ 867 ExtraMainBeamLamp_stat 100;
BA_ "GenSigStartValue" SG_ 867 ExtraMainBeamLamp_stat 7;
BA_ "GenSigMaxLatency" SG_ 867 ExtraMainBeamLamp_stat 250;
BA_ "GenSigCycleTime" SG_ 867 MainBeamLEDStatusLeft 100;
BA_ "GenSigCycleTimeActive" SG_ 867 MainBeamLEDStatusLeft 100;
BA_ "GenSigStartValue" SG_ 867 MainBeamLEDStatusLeft 7;
BA_ "GenSigMaxLatency" SG_ 867 MainBeamLEDStatusLeft 250;
BA_ "GenSigCycleTime" SG_ 867 PositionLightRearLamp_stat 100;
BA_ "GenSigCycleTimeActive" SG_ 867 PositionLightRearLamp_stat 100;
BA_ "GenSigStartValue" SG_ 867 PositionLightRearLamp_stat 7;
BA_ "GenSigMaxLatency" SG_ 867 PositionLightRearLamp_stat 250;
BA_ "GenSigCycleTime" SG_ 867 TrailerPosLightRightOutputStat 100;
BA_ "GenSigCycleTimeActive" SG_ 867 TrailerPosLightRightOutputStat 100;
BA_ "GenSigStartValue" SG_ 867 TrailerPosLightRightOutputStat 7;
BA_ "GenSigMaxLatency" SG_ 867 TrailerPosLightRightOutputStat 250;
BA_ "GenSigCycleTime" SG_ 867 DirIndRearLamp_Stat 100;
BA_ "GenSigCycleTimeActive" SG_ 867 DirIndRearLamp_Stat 100;
BA_ "GenSigStartValue" SG_ 867 DirIndRearLamp_Stat 7;
BA_ "GenSigMaxLatency" SG_ 867 DirIndRearLamp_Stat 250;
BA_ "GenSigCycleTime" SG_ 867 FogLightRearLamp_stat 100;
BA_ "GenSigCycleTimeActive" SG_ 867 FogLightRearLamp_stat 100;
BA_ "GenSigStartValue" SG_ 867 FogLightRearLamp_stat 7;
BA_ "GenSigMaxLatency" SG_ 867 FogLightRearLamp_stat 250;
BA_ "GenSigCycleTime" SG_ 867 BrakeLightLamp_stat 100;
BA_ "GenSigCycleTimeActive" SG_ 867 BrakeLightLamp_stat 100;
BA_ "GenSigStartValue" SG_ 867 BrakeLightLamp_stat 7;
BA_ "GenSigMaxLatency" SG_ 867 BrakeLightLamp_stat 250;
BA_ "GenSigCycleTime" SG_ 867 DippedBeamLamp_stat 100;
BA_ "GenSigCycleTimeActive" SG_ 867 DippedBeamLamp_stat 100;
BA_ "GenSigStartValue" SG_ 867 DippedBeamLamp_stat 7;
BA_ "GenSigMaxLatency" SG_ 867 DippedBeamLamp_stat 250;
BA_ "GenSigCycleTime" SG_ 867 ChassiInstepLightsLamp_stat 100;
BA_ "GenSigCycleTimeActive" SG_ 867 ChassiInstepLightsLamp_stat 100;
BA_ "GenSigStartValue" SG_ 867 ChassiInstepLightsLamp_stat 7;
BA_ "GenSigMaxLatency" SG_ 867 ChassiInstepLightsLamp_stat 250;
BA_ "GenSigCycleTime" SG_ 867 DRLLamp_stat 100;
BA_ "GenSigCycleTimeActive" SG_ 867 DRLLamp_stat 100;
BA_ "GenSigStartValue" SG_ 867 DRLLamp_stat 7;
BA_ "GenSigMaxLatency" SG_ 867 DRLLamp_stat 250;
BA_ "GenSigCycleTime" SG_ 867 TrailerDirIndRightOutputStat 100;
BA_ "GenSigCycleTimeActive" SG_ 867 TrailerDirIndRightOutputStat 100;
BA_ "GenSigStartValue" SG_ 867 TrailerDirIndRightOutputStat 7;
BA_ "GenSigMaxLatency" SG_ 867 TrailerDirIndRightOutputStat 250;
BA_ "GenSigCycleTime" SG_ 867 HeadlampFan_stat 100;
BA_ "GenSigCycleTimeActive" SG_ 867 HeadlampFan_stat 100;
BA_ "GenSigStartValue" SG_ 867 HeadlampFan_stat 7;
BA_ "GenSigMaxLatency" SG_ 867 HeadlampFan_stat 250;
BA_ "GenSigCycleTime" SG_ 867 MainBeamLamp_stat 100;
BA_ "GenSigCycleTimeActive" SG_ 867 MainBeamLamp_stat 100;
BA_ "GenSigStartValue" SG_ 867 MainBeamLamp_stat 7;
BA_ "GenSigMaxLatency" SG_ 867 MainBeamLamp_stat 250;
BA_ "GenSigCycleTime" SG_ 867 StaticCornerLightLamp_stat 100;
BA_ "GenSigCycleTimeActive" SG_ 867 StaticCornerLightLamp_stat 100;
BA_ "GenSigStartValue" SG_ 867 StaticCornerLightLamp_stat 7;
BA_ "GenSigMaxLatency" SG_ 867 StaticCornerLightLamp_stat 250;
BA_ "GenSigCycleTime" SG_ 867 AuxFogLightLamp_stat 100;
BA_ "GenSigCycleTimeActive" SG_ 867 AuxFogLightLamp_stat 100;
BA_ "GenSigStartValue" SG_ 867 AuxFogLightLamp_stat 7;
BA_ "GenSigMaxLatency" SG_ 867 AuxFogLightLamp_stat 250;
BA_ "GenSigCycleTime" SG_ 867 PositionLightLamp_stat 100;
BA_ "GenSigCycleTimeActive" SG_ 867 PositionLightLamp_stat 100;
BA_ "GenSigStartValue" SG_ 867 PositionLightLamp_stat 7;
BA_ "GenSigMaxLatency" SG_ 867 PositionLightLamp_stat 250;
BA_ "GenSigCycleTime" SG_ 866 LoadDistributionSelected2 100;
BA_ "GenSigCycleTimeActive" SG_ 866 LoadDistributionSelected2 100;
BA_ "GenSigStartValue" SG_ 866 LoadDistributionSelected2 15;
BA_ "GenSigMaxLatency" SG_ 866 LoadDistributionSelected2 260;
BA_ "GenSigCycleTime" SG_ 866 DriveAxleLoad 100;
BA_ "GenSigCycleTimeActive" SG_ 866 DriveAxleLoad 100;
BA_ "GenSigStartValue" SG_ 866 DriveAxleLoad 65535;
BA_ "GenSigMaxLatency" SG_ 866 DriveAxleLoad 250;
BA_ "GenSigCycleTime" SG_ 866 StarterMotorRecoveryTime 100;
BA_ "GenSigCycleTimeActive" SG_ 866 StarterMotorRecoveryTime 100;
BA_ "GenSigStartValue" SG_ 866 StarterMotorRecoveryTime 65535;
BA_ "GenSigMaxLatency" SG_ 866 StarterMotorRecoveryTime 250;
BA_ "GenSigCycleTime" SG_ 865 MonthLocal 100;
BA_ "GenSigCycleTimeActive" SG_ 865 MonthLocal 100;
BA_ "GenSigStartValue" SG_ 865 MonthLocal 255;
BA_ "GenSigMaxLatency" SG_ 865 MonthLocal 250;
BA_ "GenSigCycleTime" SG_ 865 SecondsLocal 100;
BA_ "GenSigCycleTimeActive" SG_ 865 SecondsLocal 100;
BA_ "GenSigStartValue" SG_ 865 SecondsLocal 255;
BA_ "GenSigMaxLatency" SG_ 865 SecondsLocal 250;
BA_ "GenSigCycleTime" SG_ 865 YearLocal 100;
BA_ "GenSigCycleTimeActive" SG_ 865 YearLocal 100;
BA_ "GenSigStartValue" SG_ 865 YearLocal 255;
BA_ "GenSigMaxLatency" SG_ 865 YearLocal 250;
BA_ "GenSigCycleTime" SG_ 865 DayLocal 100;
BA_ "GenSigCycleTimeActive" SG_ 865 DayLocal 100;
BA_ "GenSigStartValue" SG_ 865 DayLocal 255;
BA_ "GenSigMaxLatency" SG_ 865 DayLocal 250;
BA_ "GenSigCycleTime" SG_ 865 MinutesLocal 100;
BA_ "GenSigCycleTimeActive" SG_ 865 MinutesLocal 100;
BA_ "GenSigStartValue" SG_ 865 MinutesLocal 255;
BA_ "GenSigMaxLatency" SG_ 865 MinutesLocal 250;
BA_ "GenSigCycleTime" SG_ 865 HoursLocal 100;
BA_ "GenSigCycleTimeActive" SG_ 865 HoursLocal 100;
BA_ "GenSigStartValue" SG_ 865 HoursLocal 255;
BA_ "GenSigMaxLatency" SG_ 865 HoursLocal 250;
BA_ "GenSigCycleTime" SG_ 865 DayOfWeek_stat 100;
BA_ "GenSigCycleTimeActive" SG_ 865 DayOfWeek_stat 100;
BA_ "GenSigStartValue" SG_ 865 DayOfWeek_stat 15;
BA_ "GenSigMaxLatency" SG_ 865 DayOfWeek_stat 250;
BA_ "GenSigCycleTime" SG_ 864 SecondsUTC 100;
BA_ "GenSigCycleTimeActive" SG_ 864 SecondsUTC 100;
BA_ "GenSigStartValue" SG_ 864 SecondsUTC 255;
BA_ "GenSigMaxLatency" SG_ 864 SecondsUTC 255;
BA_ "GenSigCycleTime" SG_ 864 MinutesUTC 100;
BA_ "GenSigCycleTimeActive" SG_ 864 MinutesUTC 100;
BA_ "GenSigStartValue" SG_ 864 MinutesUTC 255;
BA_ "GenSigMaxLatency" SG_ 864 MinutesUTC 255;
BA_ "GenSigCycleTime" SG_ 864 MonthUTC 100;
BA_ "GenSigCycleTimeActive" SG_ 864 MonthUTC 100;
BA_ "GenSigStartValue" SG_ 864 MonthUTC 255;
BA_ "GenSigMaxLatency" SG_ 864 MonthUTC 255;
BA_ "GenSigCycleTime" SG_ 864 YearUTC 100;
BA_ "GenSigCycleTimeActive" SG_ 864 YearUTC 100;
BA_ "GenSigStartValue" SG_ 864 YearUTC 255;
BA_ "GenSigMaxLatency" SG_ 864 YearUTC 255;
BA_ "GenSigCycleTime" SG_ 864 DayUTC 100;
BA_ "GenSigCycleTimeActive" SG_ 864 DayUTC 100;
BA_ "GenSigStartValue" SG_ 864 DayUTC 255;
BA_ "GenSigMaxLatency" SG_ 864 DayUTC 255;
BA_ "GenSigCycleTime" SG_ 864 HoursUTC 100;
BA_ "GenSigCycleTimeActive" SG_ 864 HoursUTC 100;
BA_ "GenSigStartValue" SG_ 864 HoursUTC 255;
BA_ "GenSigMaxLatency" SG_ 864 HoursUTC 255;
BA_ "GenSigCycleTime" SG_ 696 RedGladHand_SqC 100;
BA_ "GenSigCycleTimeActive" SG_ 696 RedGladHand_SqC 100;
BA_ "GenSigStartValue" SG_ 696 RedGladHand_SqC 14;
BA_ "GenSigMaxLatency" SG_ 696 RedGladHand_SqC 110;
BA_ "GenSigCycleTime" SG_ 696 RedGladHand_CRC 100;
BA_ "GenSigCycleTimeActive" SG_ 696 RedGladHand_CRC 100;
BA_ "GenSigStartValue" SG_ 696 RedGladHand_CRC 255;
BA_ "GenSigMaxLatency" SG_ 696 RedGladHand_CRC 110;
BA_ "E2EDataId" SG_ 696 RedGladHand_CRC 146;
BA_ "E2EDataLength" SG_ 696 RedGladHand_CRC 16;
BA_ "E2EProfile" SG_ 696 RedGladHand_CRC "P01";
BA_ "GenSigCycleTime" SG_ 696 TrailerStatus_IntegrityLvl 100;
BA_ "GenSigCycleTimeActive" SG_ 696 TrailerStatus_IntegrityLvl 100;
BA_ "GenSigStartValue" SG_ 696 TrailerStatus_IntegrityLvl 3;
BA_ "GenSigMaxLatency" SG_ 696 TrailerStatus_IntegrityLvl 110;
BA_ "GenSigCycleTime" SG_ 696 TrailerStatus_CRC 100;
BA_ "GenSigCycleTimeActive" SG_ 696 TrailerStatus_CRC 100;
BA_ "GenSigStartValue" SG_ 696 TrailerStatus_CRC 255;
BA_ "GenSigMaxLatency" SG_ 696 TrailerStatus_CRC 110;
BA_ "E2EDataId" SG_ 696 TrailerStatus_CRC 116;
BA_ "E2EDataLength" SG_ 696 TrailerStatus_CRC 24;
BA_ "E2EProfile" SG_ 696 TrailerStatus_CRC "P01";
BA_ "GenSigCycleTime" SG_ 696 RedGladHand_ConfidenceLvl 100;
BA_ "GenSigCycleTimeActive" SG_ 696 RedGladHand_ConfidenceLvl 100;
BA_ "GenSigStartValue" SG_ 696 RedGladHand_ConfidenceLvl 3;
BA_ "GenSigMaxLatency" SG_ 696 RedGladHand_ConfidenceLvl 110;
BA_ "GenSigCycleTime" SG_ 696 TrailerStatus_SqC 100;
BA_ "GenSigCycleTimeActive" SG_ 696 TrailerStatus_SqC 100;
BA_ "GenSigStartValue" SG_ 696 TrailerStatus_SqC 14;
BA_ "GenSigMaxLatency" SG_ 696 TrailerStatus_SqC 110;
BA_ "GenSigCycleTime" SG_ 696 TrailerStatus_Actuation 100;
BA_ "GenSigCycleTimeActive" SG_ 696 TrailerStatus_Actuation 100;
BA_ "GenSigStartValue" SG_ 696 TrailerStatus_Actuation 7;
BA_ "GenSigMaxLatency" SG_ 696 TrailerStatus_Actuation 110;
BA_ "GenSigCycleTime" SG_ 696 RedGladHand_ConnectStatus 100;
BA_ "GenSigCycleTimeActive" SG_ 696 RedGladHand_ConnectStatus 100;
BA_ "GenSigStartValue" SG_ 696 RedGladHand_ConnectStatus 3;
BA_ "GenSigMaxLatency" SG_ 696 RedGladHand_ConnectStatus 110;
BA_ "GenSigCycleTime" SG_ 695 TrafficSitPathEvent2_Type 100;
BA_ "GenSigCycleTimeActive" SG_ 695 TrafficSitPathEvent2_Type 100;
BA_ "GenSigStartValue" SG_ 695 TrafficSitPathEvent2_Type 255;
BA_ "GenSigMaxLatency" SG_ 695 TrafficSitPathEvent2_Type 105;
BA_ "GenSigCycleTime" SG_ 695 TrafficSitPathEvent1_Distance 100;
BA_ "GenSigCycleTimeActive" SG_ 695 TrafficSitPathEvent1_Distance 100;
BA_ "GenSigStartValue" SG_ 695 TrafficSitPathEvent1_Distance 16383;
BA_ "GenSigMaxLatency" SG_ 695 TrafficSitPathEvent1_Distance 105;
BA_ "GenSigCycleTime" SG_ 695 TrafficSitPathEvent1_Speed 100;
BA_ "GenSigCycleTimeActive" SG_ 695 TrafficSitPathEvent1_Speed 100;
BA_ "GenSigStartValue" SG_ 695 TrafficSitPathEvent1_Speed 1023;
BA_ "GenSigMaxLatency" SG_ 695 TrafficSitPathEvent1_Speed 105;
BA_ "GenSigCycleTime" SG_ 695 TrafficSitPathEvent2_Speed 100;
BA_ "GenSigCycleTimeActive" SG_ 695 TrafficSitPathEvent2_Speed 100;
BA_ "GenSigStartValue" SG_ 695 TrafficSitPathEvent2_Speed 1023;
BA_ "GenSigMaxLatency" SG_ 695 TrafficSitPathEvent2_Speed 105;
BA_ "GenSigCycleTime" SG_ 695 TrafficSitPathEvent1_Type 100;
BA_ "GenSigCycleTimeActive" SG_ 695 TrafficSitPathEvent1_Type 100;
BA_ "GenSigStartValue" SG_ 695 TrafficSitPathEvent1_Type 255;
BA_ "GenSigMaxLatency" SG_ 695 TrafficSitPathEvent1_Type 105;
BA_ "GenSigCycleTime" SG_ 695 TrafficSitPathEvent2_Distance 100;
BA_ "GenSigCycleTimeActive" SG_ 695 TrafficSitPathEvent2_Distance 100;
BA_ "GenSigStartValue" SG_ 695 TrafficSitPathEvent2_Distance 16383;
BA_ "GenSigMaxLatency" SG_ 695 TrafficSitPathEvent2_Distance 105;
BA_ "GenSigCycleTime" SG_ 694 BatteryCapacity 100;
BA_ "GenSigCycleTimeActive" SG_ 694 BatteryCapacity 100;
BA_ "GenSigStartValue" SG_ 694 BatteryCapacity 15;
BA_ "GenSigMaxLatency" SG_ 694 BatteryCapacity 100;
BA_ "GenSigCycleTime" SG_ 694 BatteryCurrent 100;
BA_ "GenSigCycleTimeActive" SG_ 694 BatteryCurrent 100;
BA_ "GenSigStartValue" SG_ 694 BatteryCurrent 65535;
BA_ "GenSigMaxLatency" SG_ 694 BatteryCurrent 100;
BA_ "GenSigCycleTime" SG_ 694 AmbientLight_stat 100;
BA_ "GenSigCycleTimeActive" SG_ 694 AmbientLight_stat 100;
BA_ "GenSigStartValue" SG_ 694 AmbientLight_stat 65535;
BA_ "GenSigMaxLatency" SG_ 694 AmbientLight_stat 100;
BA_ "GenSigCycleTime" SG_ 693 TransmissionRangeSelected 100;
BA_ "GenSigCycleTimeActive" SG_ 693 TransmissionRangeSelected 100;
BA_ "GenSigMaxLatency" SG_ 693 TransmissionRangeSelected 100;
BA_ "GenSigCycleTime" SG_ 693 TransmissionRangeAttained 100;
BA_ "GenSigCycleTimeActive" SG_ 693 TransmissionRangeAttained 100;
BA_ "GenSigMaxLatency" SG_ 693 TransmissionRangeAttained 100;
BA_ "GenSigCycleTime" SG_ 693 FrontRoadWheelAngleEstimate1 100;
BA_ "GenSigCycleTimeActive" SG_ 693 FrontRoadWheelAngleEstimate1 100;
BA_ "GenSigStartValue" SG_ 693 FrontRoadWheelAngleEstimate1 65535;
BA_ "GenSigMaxLatency" SG_ 693 FrontRoadWheelAngleEstimate1 100;
BA_ "GenSigCycleTime" SG_ 693 WheelBasedVehicleSpeed 100;
BA_ "GenSigCycleTimeActive" SG_ 693 WheelBasedVehicleSpeed 100;
BA_ "GenSigStartValue" SG_ 693 WheelBasedVehicleSpeed 65535;
BA_ "GenSigMaxLatency" SG_ 693 WheelBasedVehicleSpeed 100;
BA_ "GenSigCycleTime" SG_ 692 BatterySOCactCriticalAlert 100;
BA_ "GenSigCycleTimeActive" SG_ 692 BatterySOCactCriticalAlert 100;
BA_ "GenSigStartValue" SG_ 692 BatterySOCactCriticalAlert 255;
BA_ "GenSigMaxLatency" SG_ 692 BatterySOCactCriticalAlert 100;
BA_ "GenSigCycleTime" SG_ 692 BatterySOCTrustLevel 100;
BA_ "GenSigCycleTimeActive" SG_ 692 BatterySOCTrustLevel 100;
BA_ "GenSigStartValue" SG_ 692 BatterySOCTrustLevel 255;
BA_ "GenSigMaxLatency" SG_ 692 BatterySOCTrustLevel 100;
BA_ "GenSigCycleTime" SG_ 692 BatterySOCnom 100;
BA_ "GenSigCycleTimeActive" SG_ 692 BatterySOCnom 100;
BA_ "GenSigStartValue" SG_ 692 BatterySOCnom 255;
BA_ "GenSigMaxLatency" SG_ 692 BatterySOCnom 100;
BA_ "GenSigCycleTime" SG_ 692 BatteryTemp 100;
BA_ "GenSigCycleTimeActive" SG_ 692 BatteryTemp 100;
BA_ "GenSigStartValue" SG_ 692 BatteryTemp 255;
BA_ "GenSigMaxLatency" SG_ 692 BatteryTemp 100;
BA_ "GenSigCycleTime" SG_ 692 BatteryVoltageDisplayValue 100;
BA_ "GenSigCycleTimeActive" SG_ 692 BatteryVoltageDisplayValue 100;
BA_ "GenSigStartValue" SG_ 692 BatteryVoltageDisplayValue 65535;
BA_ "GenSigMaxLatency" SG_ 692 BatteryVoltageDisplayValue 100;
BA_ "GenSigCycleTime" SG_ 692 BatterySOCact 100;
BA_ "GenSigCycleTimeActive" SG_ 692 BatterySOCact 100;
BA_ "GenSigStartValue" SG_ 692 BatterySOCact 255;
BA_ "GenSigMaxLatency" SG_ 692 BatterySOCact 100;
BA_ "GenSigCycleTime" SG_ 692 BatterySOH 100;
BA_ "GenSigCycleTimeActive" SG_ 692 BatterySOH 100;
BA_ "GenSigStartValue" SG_ 692 BatterySOH 255;
BA_ "GenSigMaxLatency" SG_ 692 BatterySOH 100;
BA_REL_ "GenSigFirstTimeoutTime" BU_SG_REL_ CCM SG_ 869 CoolantPumpEngagementStatus 6000;
BA_REL_ "GenSigTimeoutTime" BU_SG_REL_ CCM SG_ 869 CoolantPumpEngagementStatus 1500;
BA_REL_ "GenSigFirstTimeoutTime" BU_SG_REL_ IC SG_ 869 CoolantTempGaugeAdjustment 3000;
BA_REL_ "GenSigTimeoutTime" BU_SG_REL_ IC SG_ 869 CoolantTempGaugeAdjustment 1500;
BA_REL_ "GenSigFirstTimeoutTime" BU_SG_REL_ CCM SG_ 869 EngineCoolingFanSpeed 6000;
BA_REL_ "GenSigTimeoutTime" BU_SG_REL_ CCM SG_ 869 EngineCoolingFanSpeed 1500;
BA_REL_ "GenSigFirstTimeoutTime" BU_SG_REL_ CCM SG_ 880 PHTimerTGWEvCmd_PhTimer1_cmd 3000;
BA_REL_ "GenSigTimeoutTime" BU_SG_REL_ CCM SG_ 880 PHTimerTGWEvCmd_PhTimer1_cmd 600;
BA_REL_ "GenSigFirstTimeoutTime" BU_SG_REL_ CCM SG_ 880 PHTimerTGWEvCmd_Timer2Temp 3000;
BA_REL_ "GenSigTimeoutTime" BU_SG_REL_ CCM SG_ 880 PHTimerTGWEvCmd_Timer2Temp 600;
BA_REL_ "GenSigFirstTimeoutTime" BU_SG_REL_ CCM SG_ 880 PHTimerTGWEvCmd_Timer2Hours 3000;
BA_REL_ "GenSigTimeoutTime" BU_SG_REL_ CCM SG_ 880 PHTimerTGWEvCmd_Timer2Hours 600;
BA_REL_ "GenSigFirstTimeoutTime" BU_SG_REL_ CCM SG_ 880 PHTimerTGWEvCmd_Timer3StartDay 3000;
BA_REL_ "GenSigTimeoutTime" BU_SG_REL_ CCM SG_ 880 PHTimerTGWEvCmd_Timer3StartDay 600;
BA_REL_ "GenSigFirstTimeoutTime" BU_SG_REL_ CCM SG_ 880 PHTimerTGWEvCmd_Timer2StartDay 3000;
BA_REL_ "GenSigTimeoutTime" BU_SG_REL_ CCM SG_ 880 PHTimerTGWEvCmd_Timer2StartDay 600;
BA_REL_ "GenSigFirstTimeoutTime" BU_SG_REL_ CCM SG_ 880 PHTimerTGWEvCmd_PhTimer3_cmd 3000;
BA_REL_ "GenSigTimeoutTime" BU_SG_REL_ CCM SG_ 880 PHTimerTGWEvCmd_PhTimer3_cmd 600;
BA_REL_ "GenSigFirstTimeoutTime" BU_SG_REL_ CCM SG_ 880 PHTimerTGWEvCmd_Timer3Hours 3000;
BA_REL_ "GenSigTimeoutTime" BU_SG_REL_ CCM SG_ 880 PHTimerTGWEvCmd_Timer3Hours 600;
BA_REL_ "GenSigFirstTimeoutTime" BU_SG_REL_ CCM SG_ 880 PHTimerTGWEvCmd_Timer2Recur 3000;
BA_REL_ "GenSigTimeoutTime" BU_SG_REL_ CCM SG_ 880 PHTimerTGWEvCmd_Timer2Recur 600;
BA_REL_ "GenSigFirstTimeoutTime" BU_SG_REL_ CCM SG_ 880 PHTimerTGWEvCmd_PhTimer2_cmd 3000;
BA_REL_ "GenSigTimeoutTime" BU_SG_REL_ CCM SG_ 880 PHTimerTGWEvCmd_PhTimer2_cmd 600;
BA_REL_ "GenSigFirstTimeoutTime" BU_SG_REL_ CCM SG_ 880 PHTimerTGWEvCmd_Timer3Temp 3000;
BA_REL_ "GenSigTimeoutTime" BU_SG_REL_ CCM SG_ 880 PHTimerTGWEvCmd_Timer3Temp 600;
BA_REL_ "GenSigFirstTimeoutTime" BU_SG_REL_ CCM SG_ 880 PHTimerTGWEvCmd_Timer1Hours 3000;
BA_REL_ "GenSigTimeoutTime" BU_SG_REL_ CCM SG_ 880 PHTimerTGWEvCmd_Timer1Hours 600;
BA_REL_ "GenSigFirstTimeoutTime" BU_SG_REL_ CCM SG_ 880 PHTimerTGWEvCmd_Timer3Recur 3000;
BA_REL_ "GenSigTimeoutTime" BU_SG_REL_ CCM SG_ 880 PHTimerTGWEvCmd_Timer3Recur 600;
BA_REL_ "GenSigFirstTimeoutTime" BU_SG_REL_ CCM SG_ 880 PHTimerTGWEvCmd_Timer3Minutes 3000;
BA_REL_ "GenSigTimeoutTime" BU_SG_REL_ CCM SG_ 880 PHTimerTGWEvCmd_Timer3Minutes 600;
BA_REL_ "GenSigFirstTimeoutTime" BU_SG_REL_ CCM SG_ 880 PHTimerTGWEvCmd_Timer1Minutes 3000;
BA_REL_ "GenSigTimeoutTime" BU_SG_REL_ CCM SG_ 880 PHTimerTGWEvCmd_Timer1Minutes 600;
BA_REL_ "GenSigFirstTimeoutTime" BU_SG_REL_ CCM SG_ 880 PHTimerTGWEvCmd_Timer1Recur 3000;
BA_REL_ "GenSigTimeoutTime" BU_SG_REL_ CCM SG_ 880 PHTimerTGWEvCmd_Timer1Recur 600;
BA_REL_ "GenSigFirstTimeoutTime" BU_SG_REL_ CCM SG_ 880 PHTimerTGWEvCmd_Timer1StartDay 3000;
BA_REL_ "GenSigTimeoutTime" BU_SG_REL_ CCM SG_ 880 PHTimerTGWEvCmd_Timer1StartDay 600;
BA_REL_ "GenSigFirstTimeoutTime" BU_SG_REL_ CCM SG_ 880 PHTimerTGWEvCmd_Timer2Minutes 3000;
BA_REL_ "GenSigTimeoutTime" BU_SG_REL_ CCM SG_ 880 PHTimerTGWEvCmd_Timer2Minutes 600;
BA_REL_ "GenSigFirstTimeoutTime" BU_SG_REL_ CCM SG_ 880 PHTimerTGWEvCmd_Timer1Duration 3000;
BA_REL_ "GenSigTimeoutTime" BU_SG_REL_ CCM SG_ 880 PHTimerTGWEvCmd_Timer1Duration 600;
BA_REL_ "GenSigFirstTimeoutTime" BU_SG_REL_ CCM SG_ 880 PHTimerTGWEvCmd_Timer1Temp 3000;
BA_REL_ "GenSigTimeoutTime" BU_SG_REL_ CCM SG_ 880 PHTimerTGWEvCmd_Timer1Temp 600;
BA_REL_ "GenSigFirstTimeoutTime" BU_SG_REL_ IC SG_ 1209 LngTank2RemainingGasVolume 24000;
BA_REL_ "GenSigTimeoutTime" BU_SG_REL_ IC SG_ 1209 LngTank2RemainingGasVolume 6000;
BA_REL_ "GenSigFirstTimeoutTime" BU_SG_REL_ IC SG_ 1209 LNGRestrictionStatus_Spare4 24000;
BA_REL_ "GenSigTimeoutTime" BU_SG_REL_ IC SG_ 1209 LNGRestrictionStatus_Spare4 6000;
BA_REL_ "GenSigFirstTimeoutTime" BU_SG_REL_ IC SG_ 1209 LNGRestrictionStatus_V1Closed 24000;
BA_REL_ "GenSigTimeoutTime" BU_SG_REL_ IC SG_ 1209 LNGRestrictionStatus_V1Closed 6000;
BA_REL_ "GenSigFirstTimeoutTime" BU_SG_REL_ IC SG_ 1209 LNGRestrictionStatus_Spare3 24000;
BA_REL_ "GenSigTimeoutTime" BU_SG_REL_ IC SG_ 1209 LNGRestrictionStatus_Spare3 6000;
BA_REL_ "GenSigFirstTimeoutTime" BU_SG_REL_ IC SG_ 1209 LngTank2WarnStat 24000;
BA_REL_ "GenSigTimeoutTime" BU_SG_REL_ IC SG_ 1209 LngTank2WarnStat 6000;
BA_REL_ "GenSigFirstTimeoutTime" BU_SG_REL_ IC SG_ 1209 LNGRestrictionStatus_Spare2 24000;
BA_REL_ "GenSigTimeoutTime" BU_SG_REL_ IC SG_ 1209 LNGRestrictionStatus_Spare2 6000;
BA_REL_ "GenSigFirstTimeoutTime" BU_SG_REL_ IC SG_ 1209 LngTank1RemainingGasVolume 24000;
BA_REL_ "GenSigTimeoutTime" BU_SG_REL_ IC SG_ 1209 LngTank1RemainingGasVolume 6000;
BA_REL_ "GenSigFirstTimeoutTime" BU_SG_REL_ IC SG_ 1209 LngSystemReadinessStat 24000;
BA_REL_ "GenSigTimeoutTime" BU_SG_REL_ IC SG_ 1209 LngSystemReadinessStat 6000;
BA_REL_ "GenSigFirstTimeoutTime" BU_SG_REL_ IC SG_ 1209 LNGOperatorInducementReason 24000;
BA_REL_ "GenSigTimeoutTime" BU_SG_REL_ IC SG_ 1209 LNGOperatorInducementReason 6000;
BA_REL_ "GenSigFirstTimeoutTime" BU_SG_REL_ IC SG_ 1209 LNGRestrictionStatus_Spare1 24000;
BA_REL_ "GenSigTimeoutTime" BU_SG_REL_ IC SG_ 1209 LNGRestrictionStatus_Spare1 6000;
BA_REL_ "GenSigFirstTimeoutTime" BU_SG_REL_ IC SG_ 1209 LNGRestrictionStatus_V2Closed 24000;
BA_REL_ "GenSigTimeoutTime" BU_SG_REL_ IC SG_ 1209 LNGRestrictionStatus_V2Closed 6000;
BA_REL_ "GenSigFirstTimeoutTime" BU_SG_REL_ IC SG_ 1209 LngTank1WarnStat 24000;
BA_REL_ "GenSigTimeoutTime" BU_SG_REL_ IC SG_ 1209 LngTank1WarnStat 6000;
BA_REL_ "GenSigFirstTimeoutTime" BU_SG_REL_ IC SG_ 1209 LNGTimeToVent 24000;
BA_REL_ "GenSigTimeoutTime" BU_SG_REL_ IC SG_ 1209 LNGTimeToVent 6000;
BA_REL_ "GenSigFirstTimeoutTime" BU_SG_REL_ IC SG_ 1209 LNGLevel 24000;
BA_REL_ "GenSigTimeoutTime" BU_SG_REL_ IC SG_ 1209 LNGLevel 6000;
BA_REL_ "GenSigFirstTimeoutTime" BU_SG_REL_ IC SG_ 1209 LNGRestrictionStatus_SInfo 24000;
BA_REL_ "GenSigTimeoutTime" BU_SG_REL_ IC SG_ 1209 LNGRestrictionStatus_SInfo 6000;
BA_REL_ "GenSigFirstTimeoutTime" BU_SG_REL_ IC SG_ 1209 LngGspWarnStat 24000;
BA_REL_ "GenSigTimeoutTime" BU_SG_REL_ IC SG_ 1209 LngGspWarnStat 6000;
BA_REL_ "GenSigFirstTimeoutTime" BU_SG_REL_ IC SG_ 1208 EcoCruisePwtMaxUnSpeedLev3 24000;
BA_REL_ "GenSigTimeoutTime" BU_SG_REL_ IC SG_ 1208 EcoCruisePwtMaxUnSpeedLev3 6000;
BA_REL_ "GenSigFirstTimeoutTime" BU_SG_REL_ IC SG_ 1208 EcoCruisePwtMaxOvSpeedLev0 24000;
BA_REL_ "GenSigTimeoutTime" BU_SG_REL_ IC SG_ 1208 EcoCruisePwtMaxOvSpeedLev0 6000;
BA_REL_ "GenSigFirstTimeoutTime" BU_SG_REL_ IC SG_ 1208 EcoCruisePwtMaxUnSpeedLev1 24000;
BA_REL_ "GenSigTimeoutTime" BU_SG_REL_ IC SG_ 1208 EcoCruisePwtMaxUnSpeedLev1 6000;
BA_REL_ "GenSigFirstTimeoutTime" BU_SG_REL_ IC SG_ 1208 EcoCruisePwtMaxOvSpeedLev2 24000;
BA_REL_ "GenSigTimeoutTime" BU_SG_REL_ IC SG_ 1208 EcoCruisePwtMaxOvSpeedLev2 6000;
BA_REL_ "GenSigFirstTimeoutTime" BU_SG_REL_ IC SG_ 1208 EcoCruisePwtMaxUnSpeedLev0 24000;
BA_REL_ "GenSigTimeoutTime" BU_SG_REL_ IC SG_ 1208 EcoCruisePwtMaxUnSpeedLev0 6000;
BA_REL_ "GenSigFirstTimeoutTime" BU_SG_REL_ IC SG_ 1208 EcoCruisePwtMaxOvSpeedLev1 24000;
BA_REL_ "GenSigTimeoutTime" BU_SG_REL_ IC SG_ 1208 EcoCruisePwtMaxOvSpeedLev1 6000;
BA_REL_ "GenSigFirstTimeoutTime" BU_SG_REL_ IC SG_ 1208 EcoCruisePwtMaxUnSpeedLev2 24000;
BA_REL_ "GenSigTimeoutTime" BU_SG_REL_ IC SG_ 1208 EcoCruisePwtMaxUnSpeedLev2 6000;
BA_REL_ "GenSigFirstTimeoutTime" BU_SG_REL_ IC SG_ 1208 EcoCruisePwtMaxOvSpeedLev3 24000;
BA_REL_ "GenSigTimeoutTime" BU_SG_REL_ IC SG_ 1208 EcoCruisePwtMaxOvSpeedLev3 6000;
BA_REL_ "GenSigFirstTimeoutTime" BU_SG_REL_ IC SG_ 1207 EngineTotalLngConsumed 24000;
BA_REL_ "GenSigTimeoutTime" BU_SG_REL_ IC SG_ 1207 EngineTotalLngConsumed 6000;
BA_REL_ "GenSigFirstTimeoutTime" BU_SG_REL_ CCM SG_ 1207 TotalVehicleDistanceHighRes 24000;
BA_REL_ "GenSigTimeoutTime" BU_SG_REL_ CCM SG_ 1207 TotalVehicleDistanceHighRes 6000;
BA_REL_ "GenSigFirstTimeoutTime" BU_SG_REL_ IC SG_ 1206 PredictedMileageOfNextPadChg 24000;
BA_REL_ "GenSigTimeoutTime" BU_SG_REL_ IC SG_ 1206 PredictedMileageOfNextPadChg 6000;
BA_REL_ "GenSigFirstTimeoutTime" BU_SG_REL_ IC SG_ 1206 EngineRunningTime 24000;
BA_REL_ "GenSigTimeoutTime" BU_SG_REL_ IC SG_ 1206 EngineRunningTime 6000;
BA_REL_ "GenSigFirstTimeoutTime" BU_SG_REL_ IC SG_ 1205 TopGearUseDistance 24000;
BA_REL_ "GenSigTimeoutTime" BU_SG_REL_ IC SG_ 1205 TopGearUseDistance 6000;
BA_REL_ "GenSigFirstTimeoutTime" BU_SG_REL_ IC SG_ 1205 DPFSootLevel 24000;
BA_REL_ "GenSigTimeoutTime" BU_SG_REL_ IC SG_ 1205 DPFSootLevel 6000;
BA_REL_ "GenSigFirstTimeoutTime" BU_SG_REL_ IC SG_ 1205 CatalystTankLevel 24000;
BA_REL_ "GenSigTimeoutTime" BU_SG_REL_ IC SG_ 1205 CatalystTankLevel 6000;
BA_REL_ "GenSigFirstTimeoutTime" BU_SG_REL_ IC SG_ 1205 TransmissionOilTemp 24000;
BA_REL_ "GenSigTimeoutTime" BU_SG_REL_ IC SG_ 1205 TransmissionOilTemp 6000;
BA_REL_ "GenSigFirstTimeoutTime" BU_SG_REL_ IC SG_ 1204 TimeLeftToTorqueReductionFuel 24000;
BA_REL_ "GenSigTimeoutTime" BU_SG_REL_ IC SG_ 1204 TimeLeftToTorqueReductionFuel 6000;
BA_REL_ "GenSigFirstTimeoutTime" BU_SG_REL_ IC SG_ 1204 TimeLeftToVehSpdReductionFuel 24000;
BA_REL_ "GenSigTimeoutTime" BU_SG_REL_ IC SG_ 1204 TimeLeftToVehSpdReductionFuel 6000;
BA_REL_ "GenSigFirstTimeoutTime" BU_SG_REL_ IC SG_ 1204 TransmissionOilLevel 24000;
BA_REL_ "GenSigTimeoutTime" BU_SG_REL_ IC SG_ 1204 TransmissionOilLevel 6000;
BA_REL_ "GenSigFirstTimeoutTime" BU_SG_REL_ IC SG_ 1204 TimeLeftToTorqueReduction_OBD 24000;
BA_REL_ "GenSigTimeoutTime" BU_SG_REL_ IC SG_ 1204 TimeLeftToTorqueReduction_OBD 6000;
BA_REL_ "GenSigFirstTimeoutTime" BU_SG_REL_ IC SG_ 1204 TimetoCompleteParkRegen 24000;
BA_REL_ "GenSigTimeoutTime" BU_SG_REL_ IC SG_ 1204 TimetoCompleteParkRegen 6000;
BA_REL_ "GenSigFirstTimeoutTime" BU_SG_REL_ IC SG_ 1204 TimeLeftToVehSpdReduction_OBD 24000;
BA_REL_ "GenSigTimeoutTime" BU_SG_REL_ IC SG_ 1204 TimeLeftToVehSpdReduction_OBD 6000;
BA_REL_ "GenSigFirstTimeoutTime" BU_SG_REL_ IC SG_ 1203 AdBlueTankTemperature 24000;
BA_REL_ "GenSigTimeoutTime" BU_SG_REL_ IC SG_ 1203 AdBlueTankTemperature 6000;
BA_REL_ "GenSigFirstTimeoutTime" BU_SG_REL_ IC SG_ 1203 RearDriveAxle2Temperature 24000;
BA_REL_ "GenSigTimeoutTime" BU_SG_REL_ IC SG_ 1203 RearDriveAxle2Temperature 6000;
BA_REL_ "GenSigFirstTimeoutTime" BU_SG_REL_ IC SG_ 1203 DistLeftToSevereInducement_OBD 24000;
BA_REL_ "GenSigTimeoutTime" BU_SG_REL_ IC SG_ 1203 DistLeftToSevereInducement_OBD 6000;
BA_REL_ "GenSigFirstTimeoutTime" BU_SG_REL_ IC SG_ 1203 RearDriveAxle3Temperature 24000;
BA_REL_ "GenSigTimeoutTime" BU_SG_REL_ IC SG_ 1203 RearDriveAxle3Temperature 6000;
BA_REL_ "GenSigFirstTimeoutTime" BU_SG_REL_ IC SG_ 1203 RearDriveAxle1Temperature 24000;
BA_REL_ "GenSigTimeoutTime" BU_SG_REL_ IC SG_ 1203 RearDriveAxle1Temperature 6000;
BA_REL_ "GenSigFirstTimeoutTime" BU_SG_REL_ CCM SG_ 1203 AmbientAirTemperature 24000;
BA_REL_ "GenSigTimeoutTime" BU_SG_REL_ CCM SG_ 1203 AmbientAirTemperature 6000;
BA_REL_ "GenSigFirstTimeoutTime" BU_SG_REL_ CCM SG_ 1203 EngineCoolantTemp_stat 24000;
BA_REL_ "GenSigTimeoutTime" BU_SG_REL_ CCM SG_ 1203 EngineCoolantTemp_stat 6000;
BA_REL_ "GenSigFirstTimeoutTime" BU_SG_REL_ IC SG_ 1202 FasUsrDefinedDampingSetting 24000;
BA_REL_ "GenSigTimeoutTime" BU_SG_REL_ IC SG_ 1202 FasUsrDefinedDampingSetting 6000;
BA_REL_ "GenSigFirstTimeoutTime" BU_SG_REL_ IC SG_ 1202 SCROperatorInducementSeverity 24000;
BA_REL_ "GenSigTimeoutTime" BU_SG_REL_ IC SG_ 1202 SCROperatorInducementSeverity 6000;
BA_REL_ "GenSigFirstTimeoutTime" BU_SG_REL_ IC SG_ 1202 CatalystTankLevelLow 24000;
BA_REL_ "GenSigTimeoutTime" BU_SG_REL_ IC SG_ 1202 CatalystTankLevelLow 6000;
BA_REL_ "GenSigFirstTimeoutTime" BU_SG_REL_ IC SG_ 1202 MIStatusExtEMS 24000;
BA_REL_ "GenSigTimeoutTime" BU_SG_REL_ IC SG_ 1202 MIStatusExtEMS 6000;
BA_REL_ "GenSigFirstTimeoutTime" BU_SG_REL_ IC SG_ 1202 FuelOperatorDeratingReason 24000;
BA_REL_ "GenSigTimeoutTime" BU_SG_REL_ IC SG_ 1202 FuelOperatorDeratingReason 6000;
BA_REL_ "GenSigFirstTimeoutTime" BU_SG_REL_ IC SG_ 1202 ActualFasPersSettingsButton 24000;
BA_REL_ "GenSigTimeoutTime" BU_SG_REL_ IC SG_ 1202 ActualFasPersSettingsButton 6000;
BA_REL_ "GenSigFirstTimeoutTime" BU_SG_REL_ IC SG_ 1202 BatteryEndOfCharge 24000;
BA_REL_ "GenSigTimeoutTime" BU_SG_REL_ IC SG_ 1202 BatteryEndOfCharge 6000;
BA_REL_ "GenSigFirstTimeoutTime" BU_SG_REL_ IC SG_ 1202 FasUsrDefStiffStraightSetting 24000;
BA_REL_ "GenSigTimeoutTime" BU_SG_REL_ IC SG_ 1202 FasUsrDefStiffStraightSetting 6000;
BA_REL_ "GenSigFirstTimeoutTime" BU_SG_REL_ IC SG_ 1202 LiningWearWarning 24000;
BA_REL_ "GenSigTimeoutTime" BU_SG_REL_ IC SG_ 1202 LiningWearWarning 6000;
BA_REL_ "GenSigFirstTimeoutTime" BU_SG_REL_ IC SG_ 1202 TorqueReductionStatus_OBD 24000;
BA_REL_ "GenSigTimeoutTime" BU_SG_REL_ IC SG_ 1202 TorqueReductionStatus_OBD 6000;
BA_REL_ "GenSigFirstTimeoutTime" BU_SG_REL_ IC SG_ 1202 LoadCalibrationFeedback 24000;
BA_REL_ "GenSigTimeoutTime" BU_SG_REL_ IC SG_ 1202 LoadCalibrationFeedback 6000;
BA_REL_ "GenSigFirstTimeoutTime" BU_SG_REL_ IC SG_ 1202 FasUsrDefLowSpeedReturnSetting 24000;
BA_REL_ "GenSigTimeoutTime" BU_SG_REL_ IC SG_ 1202 FasUsrDefLowSpeedReturnSetting 6000;
BA_REL_ "GenSigFirstTimeoutTime" BU_SG_REL_ IC SG_ 1202 FuelOperatorDeratingSeverity 24000;
BA_REL_ "GenSigTimeoutTime" BU_SG_REL_ IC SG_ 1202 FuelOperatorDeratingSeverity 6000;
BA_REL_ "GenSigFirstTimeoutTime" BU_SG_REL_ IC SG_ 1202 FasUsrDefStiffnessCurveSetting 24000;
BA_REL_ "GenSigTimeoutTime" BU_SG_REL_ IC SG_ 1202 FasUsrDefStiffnessCurveSetting 6000;
BA_REL_ "GenSigFirstTimeoutTime" BU_SG_REL_ IC SG_ 1202 SCROperatorInducementReason 24000;
BA_REL_ "GenSigTimeoutTime" BU_SG_REL_ IC SG_ 1202 SCROperatorInducementReason 6000;
BA_REL_ "GenSigFirstTimeoutTime" BU_SG_REL_ IC SG_ 1202 ActualFasManualOffsetSetting 24000;
BA_REL_ "GenSigTimeoutTime" BU_SG_REL_ IC SG_ 1202 ActualFasManualOffsetSetting 6000;
BA_REL_ "GenSigFirstTimeoutTime" BU_SG_REL_ IC SG_ 1202 MIDistinctWarningExtEMS 24000;
BA_REL_ "GenSigTimeoutTime" BU_SG_REL_ IC SG_ 1202 MIDistinctWarningExtEMS 6000;
BA_REL_ "GenSigFirstTimeoutTime" BU_SG_REL_ IC SG_ 1202 FasDriver 24000;
BA_REL_ "GenSigTimeoutTime" BU_SG_REL_ IC SG_ 1202 FasDriver 6000;
BA_REL_ "GenSigFirstTimeoutTime" BU_SG_REL_ IC SG_ 1202 MIDistinctWarning 24000;
BA_REL_ "GenSigTimeoutTime" BU_SG_REL_ IC SG_ 1202 MIDistinctWarning 6000;
BA_REL_ "GenSigFirstTimeoutTime" BU_SG_REL_ IC SG_ 1201 DiagFaultStat_BBIOM_DtcIdB 24000;
BA_REL_ "GenSigTimeoutTime" BU_SG_REL_ IC SG_ 1201 DiagFaultStat_BBIOM_DtcIdB 6000;
BA_REL_ "GenSigFirstTimeoutTime" BU_SG_REL_ IC SG_ 1201 DiagFaultStat_BBIOM_DtcIdA 24000;
BA_REL_ "GenSigTimeoutTime" BU_SG_REL_ IC SG_ 1201 DiagFaultStat_BBIOM_DtcIdA 6000;
BA_REL_ "GenSigFirstTimeoutTime" BU_SG_REL_ IC SG_ 1201 DiagFaultStat_BBIOM_FailTB 24000;
BA_REL_ "GenSigTimeoutTime" BU_SG_REL_ IC SG_ 1201 DiagFaultStat_BBIOM_FailTB 6000;
BA_REL_ "GenSigFirstTimeoutTime" BU_SG_REL_ IC SG_ 1201 DiagFaultStat_BBIOM_FailTA 24000;
BA_REL_ "GenSigTimeoutTime" BU_SG_REL_ IC SG_ 1201 DiagFaultStat_BBIOM_FailTA 6000;
BA_REL_ "GenSigFirstTimeoutTime" BU_SG_REL_ IC SG_ 1201 DiagFaultStat_BBIOM_EcuAdr 24000;
BA_REL_ "GenSigTimeoutTime" BU_SG_REL_ IC SG_ 1201 DiagFaultStat_BBIOM_EcuAdr 6000;
BA_REL_ "GenSigFirstTimeoutTime" BU_SG_REL_ IC SG_ 903 ManTransmiOilTemp 12000;
BA_REL_ "GenSigTimeoutTime" BU_SG_REL_ IC SG_ 903 ManTransmiOilTemp 3000;
BA_REL_ "GenSigFirstTimeoutTime" BU_SG_REL_ IC SG_ 903 EngineTurbo1BoostPressure 12000;
BA_REL_ "GenSigTimeoutTime" BU_SG_REL_ IC SG_ 903 EngineTurbo1BoostPressure 3000;
BA_REL_ "GenSigFirstTimeoutTime" BU_SG_REL_ IC SG_ 903 LastDriveAxleBellowPressure 12000;
BA_REL_ "GenSigTimeoutTime" BU_SG_REL_ IC SG_ 903 LastDriveAxleBellowPressure 3000;
BA_REL_ "GenSigFirstTimeoutTime" BU_SG_REL_ IC SG_ 902 Cur_LG5CutoffValue 12000;
BA_REL_ "GenSigTimeoutTime" BU_SG_REL_ IC SG_ 902 Cur_LG5CutoffValue 3000;
BA_REL_ "GenSigFirstTimeoutTime" BU_SG_REL_ IC SG_ 902 Cur_LG4CutoffValue 12000;
BA_REL_ "GenSigTimeoutTime" BU_SG_REL_ IC SG_ 902 Cur_LG4CutoffValue 3000;
BA_REL_ "GenSigFirstTimeoutTime" BU_SG_REL_ IC SG_ 902 Cur_LG1CutoffValue 12000;
BA_REL_ "GenSigTimeoutTime" BU_SG_REL_ IC SG_ 902 Cur_LG1CutoffValue 3000;
BA_REL_ "GenSigFirstTimeoutTime" BU_SG_REL_ IC SG_ 902 Cur_LG2CutoffValue 12000;
BA_REL_ "GenSigTimeoutTime" BU_SG_REL_ IC SG_ 902 Cur_LG2CutoffValue 3000;
BA_REL_ "GenSigFirstTimeoutTime" BU_SG_REL_ IC SG_ 902 Cur_EnergySetting 12000;
BA_REL_ "GenSigTimeoutTime" BU_SG_REL_ IC SG_ 902 Cur_EnergySetting 3000;
BA_REL_ "GenSigFirstTimeoutTime" BU_SG_REL_ IC SG_ 902 UltracapDisplay_Stat 12000;
BA_REL_ "GenSigTimeoutTime" BU_SG_REL_ IC SG_ 902 UltracapDisplay_Stat 3000;
BA_REL_ "GenSigFirstTimeoutTime" BU_SG_REL_ IC SG_ 902 Cur_LG6CutoffValue 12000;
BA_REL_ "GenSigTimeoutTime" BU_SG_REL_ IC SG_ 902 Cur_LG6CutoffValue 3000;
BA_REL_ "GenSigFirstTimeoutTime" BU_SG_REL_ IC SG_ 902 Cur_LG3CutoffValue 12000;
BA_REL_ "GenSigTimeoutTime" BU_SG_REL_ IC SG_ 902 Cur_LG3CutoffValue 3000;
BA_REL_ "GenSigFirstTimeoutTime" BU_SG_REL_ IC SG_ 902 Ultracap_Status 12000;
BA_REL_ "GenSigTimeoutTime" BU_SG_REL_ IC SG_ 902 Ultracap_Status 3000;
BA_REL_ "GenSigFirstTimeoutTime" BU_SG_REL_ IC SG_ 901 AxleLoadStatus 12000;
BA_REL_ "GenSigTimeoutTime" BU_SG_REL_ IC SG_ 901 AxleLoadStatus 3000;
BA_REL_ "GenSigFirstTimeoutTime" BU_SG_REL_ IC SG_ 901 ClutchAbuseStatus 12000;
BA_REL_ "GenSigTimeoutTime" BU_SG_REL_ IC SG_ 901 ClutchAbuseStatus 3000;
BA_REL_ "GenSigFirstTimeoutTime" BU_SG_REL_ IC SG_ 901 ISeeStatus 12000;
BA_REL_ "GenSigTimeoutTime" BU_SG_REL_ IC SG_ 901 ISeeStatus 3000;
BA_REL_ "GenSigFirstTimeoutTime" BU_SG_REL_ IC SG_ 901 TransmissionSplitboxPTOMode 12000;
BA_REL_ "GenSigTimeoutTime" BU_SG_REL_ IC SG_ 901 TransmissionSplitboxPTOMode 3000;
BA_REL_ "GenSigFirstTimeoutTime" BU_SG_REL_ IC SG_ 901 OilLevelDrvInstr_IncorrEngSpe 12000;
BA_REL_ "GenSigTimeoutTime" BU_SG_REL_ IC SG_ 901 OilLevelDrvInstr_IncorrEngSpe 3000;
BA_REL_ "GenSigFirstTimeoutTime" BU_SG_REL_ IC SG_ 901 OilLevelDrvInstr_ChangeGearTxt 12000;
BA_REL_ "GenSigTimeoutTime" BU_SG_REL_ IC SG_ 901 OilLevelDrvInstr_ChangeGearTxt 3000;
BA_REL_ "GenSigFirstTimeoutTime" BU_SG_REL_ IC SG_ 901 PredeliveryModeIndication_cmd 12000;
BA_REL_ "GenSigTimeoutTime" BU_SG_REL_ IC SG_ 901 PredeliveryModeIndication_cmd 3000;
BA_REL_ "GenSigFirstTimeoutTime" BU_SG_REL_ IC SG_ 901 OilLevelDrvInstr_Wait60SecTxt 12000;
BA_REL_ "GenSigTimeoutTime" BU_SG_REL_ IC SG_ 901 OilLevelDrvInstr_Wait60SecTxt 3000;
BA_REL_ "GenSigFirstTimeoutTime" BU_SG_REL_ IC SG_ 901 DPF_LimitedSpeedDuetoInhibit 12000;
BA_REL_ "GenSigTimeoutTime" BU_SG_REL_ IC SG_ 901 DPF_LimitedSpeedDuetoInhibit 3000;
BA_REL_ "GenSigFirstTimeoutTime" BU_SG_REL_ IC SG_ 901 DPF_ParkedRegenStatus 12000;
BA_REL_ "GenSigTimeoutTime" BU_SG_REL_ IC SG_ 901 DPF_ParkedRegenStatus 3000;
BA_REL_ "GenSigFirstTimeoutTime" BU_SG_REL_ IC SG_ 901 OilLevelDrvInstr_OilTempTxt 12000;
BA_REL_ "GenSigTimeoutTime" BU_SG_REL_ IC SG_ 901 OilLevelDrvInstr_OilTempTxt 3000;
BA_REL_ "GenSigFirstTimeoutTime" BU_SG_REL_ IC SG_ 901 OilLevelDrvInstr_StopVehicle 12000;
BA_REL_ "GenSigTimeoutTime" BU_SG_REL_ IC SG_ 901 OilLevelDrvInstr_StopVehicle 3000;
BA_REL_ "GenSigFirstTimeoutTime" BU_SG_REL_ IC SG_ 901 ClutchCalibration_stat 12000;
BA_REL_ "GenSigTimeoutTime" BU_SG_REL_ IC SG_ 901 ClutchCalibration_stat 3000;
BA_REL_ "GenSigFirstTimeoutTime" BU_SG_REL_ CCM SG_ 901 FuelVolume 12000;
BA_REL_ "GenSigTimeoutTime" BU_SG_REL_ CCM SG_ 901 FuelVolume 3000;
BA_REL_ "GenSigFirstTimeoutTime" BU_SG_REL_ IC SG_ 901 FuelVolume 12000;
BA_REL_ "GenSigTimeoutTime" BU_SG_REL_ IC SG_ 901 FuelVolume 3000;
BA_REL_ "GenSigFirstTimeoutTime" BU_SG_REL_ IC SG_ 901 OilLevelDrvInstr_NotHorizonTxt 12000;
BA_REL_ "GenSigTimeoutTime" BU_SG_REL_ IC SG_ 901 OilLevelDrvInstr_NotHorizonTxt 3000;
BA_REL_ "GenSigFirstTimeoutTime" BU_SG_REL_ CCM SG_ 901 FuelLevel 12000;
BA_REL_ "GenSigTimeoutTime" BU_SG_REL_ CCM SG_ 901 FuelLevel 3000;
BA_REL_ "GenSigFirstTimeoutTime" BU_SG_REL_ IC SG_ 868 DrainPrimingStatus 6000;
BA_REL_ "GenSigTimeoutTime" BU_SG_REL_ IC SG_ 868 DrainPrimingStatus 1500;
BA_REL_ "GenSigFirstTimeoutTime" BU_SG_REL_ IC SG_ 868 FrontConspicLamp_stat_HiRight 6000;
BA_REL_ "GenSigTimeoutTime" BU_SG_REL_ IC SG_ 868 FrontConspicLamp_stat_HiRight 1500;
BA_REL_ "GenSigFirstTimeoutTime" BU_SG_REL_ IC SG_ 868 FrontConspicLamp_stat_LoRight 6000;
BA_REL_ "GenSigTimeoutTime" BU_SG_REL_ IC SG_ 868 FrontConspicLamp_stat_LoRight 1500;
BA_REL_ "GenSigFirstTimeoutTime" BU_SG_REL_ IC SG_ 868 CoolantTempHigh 6000;
BA_REL_ "GenSigTimeoutTime" BU_SG_REL_ IC SG_ 868 CoolantTempHigh 1500;
BA_REL_ "GenSigFirstTimeoutTime" BU_SG_REL_ IC SG_ 868 AutoWheelBrakesStatus 6000;
BA_REL_ "GenSigTimeoutTime" BU_SG_REL_ IC SG_ 868 AutoWheelBrakesStatus 1500;
BA_REL_ "GenSigFirstTimeoutTime" BU_SG_REL_ IC SG_ 868 OilLevelLow 6000;
BA_REL_ "GenSigTimeoutTime" BU_SG_REL_ IC SG_ 868 OilLevelLow 1500;
BA_REL_ "GenSigFirstTimeoutTime" BU_SG_REL_ IC SG_ 868 InletAirHeaterStatus1 6000;
BA_REL_ "GenSigTimeoutTime" BU_SG_REL_ IC SG_ 868 InletAirHeaterStatus1 1500;
BA_REL_ "GenSigFirstTimeoutTime" BU_SG_REL_ IC SG_ 868 DeicingFunction_Stat 6000;
BA_REL_ "GenSigTimeoutTime" BU_SG_REL_ IC SG_ 868 DeicingFunction_Stat 1500;
BA_REL_ "GenSigFirstTimeoutTime" BU_SG_REL_ IC SG_ 868 SelfStartAssist_stat 6000;
BA_REL_ "GenSigTimeoutTime" BU_SG_REL_ IC SG_ 868 SelfStartAssist_stat 1500;
BA_REL_ "GenSigFirstTimeoutTime" BU_SG_REL_ IC SG_ 868 TrailerDirIndLeftOutputStat 6000;
BA_REL_ "GenSigTimeoutTime" BU_SG_REL_ IC SG_ 868 TrailerDirIndLeftOutputStat 1500;
BA_REL_ "GenSigFirstTimeoutTime" BU_SG_REL_ IC SG_ 868 TrailerPosLightLeftOutputStat 6000;
BA_REL_ "GenSigTimeoutTime" BU_SG_REL_ IC SG_ 868 TrailerPosLightLeftOutputStat 1500;
BA_REL_ "GenSigFirstTimeoutTime" BU_SG_REL_ IC SG_ 868 TrailerBrakeLightOutputStat 6000;
BA_REL_ "GenSigTimeoutTime" BU_SG_REL_ IC SG_ 868 TrailerBrakeLightOutputStat 1500;
BA_REL_ "GenSigFirstTimeoutTime" BU_SG_REL_ IC SG_ 868 StartBatteryDisplay_stat 6000;
BA_REL_ "GenSigTimeoutTime" BU_SG_REL_ IC SG_ 868 StartBatteryDisplay_stat 1500;
BA_REL_ "GenSigFirstTimeoutTime" BU_SG_REL_ IC SG_ 868 DeicingBulb_Stat 6000;
BA_REL_ "GenSigTimeoutTime" BU_SG_REL_ IC SG_ 868 DeicingBulb_Stat 1500;
BA_REL_ "GenSigFirstTimeoutTime" BU_SG_REL_ IC SG_ 868 LivBatDisconnectDetectStat 6000;
BA_REL_ "GenSigTimeoutTime" BU_SG_REL_ IC SG_ 868 LivBatDisconnectDetectStat 1500;
BA_REL_ "GenSigFirstTimeoutTime" BU_SG_REL_ IC SG_ 868 FrontConspicLamp_stat_LoLeft 6000;
BA_REL_ "GenSigTimeoutTime" BU_SG_REL_ IC SG_ 868 FrontConspicLamp_stat_LoLeft 1500;
BA_REL_ "GenSigFirstTimeoutTime" BU_SG_REL_ IC SG_ 868 FuelFilterClogged 6000;
BA_REL_ "GenSigTimeoutTime" BU_SG_REL_ IC SG_ 868 FuelFilterClogged 1500;
BA_REL_ "GenSigFirstTimeoutTime" BU_SG_REL_ IC SG_ 868 EngineFanOverspeed 6000;
BA_REL_ "GenSigTimeoutTime" BU_SG_REL_ IC SG_ 868 EngineFanOverspeed 1500;
BA_REL_ "GenSigFirstTimeoutTime" BU_SG_REL_ IC SG_ 868 JumpChargeInterface_stat 6000;
BA_REL_ "GenSigTimeoutTime" BU_SG_REL_ IC SG_ 868 JumpChargeInterface_stat 1500;
BA_REL_ "GenSigFirstTimeoutTime" BU_SG_REL_ IC SG_ 868 OilPressureLow 6000;
BA_REL_ "GenSigTimeoutTime" BU_SG_REL_ IC SG_ 868 OilPressureLow 1500;
BA_REL_ "GenSigFirstTimeoutTime" BU_SG_REL_ IC SG_ 868 FrontConspicLamp_stat_HiLeft 6000;
BA_REL_ "GenSigTimeoutTime" BU_SG_REL_ IC SG_ 868 FrontConspicLamp_stat_HiLeft 1500;
BA_REL_ "GenSigFirstTimeoutTime" BU_SG_REL_ IC SG_ 868 GChargerStatus 6000;
BA_REL_ "GenSigTimeoutTime" BU_SG_REL_ IC SG_ 868 GChargerStatus 1500;
BA_REL_ "GenSigFirstTimeoutTime" BU_SG_REL_ IC SG_ 868 TrailerRevAndFogOutput_stat 6000;
BA_REL_ "GenSigTimeoutTime" BU_SG_REL_ IC SG_ 868 TrailerRevAndFogOutput_stat 1500;
BA_REL_ "GenSigFirstTimeoutTime" BU_SG_REL_ IC SG_ 867 DirIndSideLamp_stat 6000;
BA_REL_ "GenSigTimeoutTime" BU_SG_REL_ IC SG_ 867 DirIndSideLamp_stat 1500;
BA_REL_ "GenSigFirstTimeoutTime" BU_SG_REL_ IC SG_ 867 DirInd_Front_Status 6000;
BA_REL_ "GenSigTimeoutTime" BU_SG_REL_ IC SG_ 867 DirInd_Front_Status 1500;
BA_REL_ "GenSigFirstTimeoutTime" BU_SG_REL_ IC SG_ 867 FogLightFrontLamp_stat 6000;
BA_REL_ "GenSigTimeoutTime" BU_SG_REL_ IC SG_ 867 FogLightFrontLamp_stat 1500;
BA_REL_ "GenSigFirstTimeoutTime" BU_SG_REL_ IC SG_ 867 MainBeamLEDStatusRight 6000;
BA_REL_ "GenSigTimeoutTime" BU_SG_REL_ IC SG_ 867 MainBeamLEDStatusRight 1500;
BA_REL_ "GenSigFirstTimeoutTime" BU_SG_REL_ IC SG_ 867 RevLightLamp_stat 6000;
BA_REL_ "GenSigTimeoutTime" BU_SG_REL_ IC SG_ 867 RevLightLamp_stat 1500;
BA_REL_ "GenSigFirstTimeoutTime" BU_SG_REL_ IC SG_ 867 ExtraMainBeamLamp_stat 6000;
BA_REL_ "GenSigTimeoutTime" BU_SG_REL_ IC SG_ 867 ExtraMainBeamLamp_stat 1500;
BA_REL_ "GenSigFirstTimeoutTime" BU_SG_REL_ IC SG_ 867 MainBeamLEDStatusLeft 6000;
BA_REL_ "GenSigTimeoutTime" BU_SG_REL_ IC SG_ 867 MainBeamLEDStatusLeft 1500;
BA_REL_ "GenSigFirstTimeoutTime" BU_SG_REL_ IC SG_ 867 PositionLightRearLamp_stat 6000;
BA_REL_ "GenSigTimeoutTime" BU_SG_REL_ IC SG_ 867 PositionLightRearLamp_stat 1500;
BA_REL_ "GenSigFirstTimeoutTime" BU_SG_REL_ IC SG_ 867 TrailerPosLightRightOutputStat 6000;
BA_REL_ "GenSigTimeoutTime" BU_SG_REL_ IC SG_ 867 TrailerPosLightRightOutputStat 1500;
BA_REL_ "GenSigFirstTimeoutTime" BU_SG_REL_ IC SG_ 867 DirIndRearLamp_Stat 6000;
BA_REL_ "GenSigTimeoutTime" BU_SG_REL_ IC SG_ 867 DirIndRearLamp_Stat 1500;
BA_REL_ "GenSigFirstTimeoutTime" BU_SG_REL_ IC SG_ 867 FogLightRearLamp_stat 6000;
BA_REL_ "GenSigTimeoutTime" BU_SG_REL_ IC SG_ 867 FogLightRearLamp_stat 1500;
BA_REL_ "GenSigFirstTimeoutTime" BU_SG_REL_ IC SG_ 867 BrakeLightLamp_stat 6000;
BA_REL_ "GenSigTimeoutTime" BU_SG_REL_ IC SG_ 867 BrakeLightLamp_stat 1500;
BA_REL_ "GenSigFirstTimeoutTime" BU_SG_REL_ IC SG_ 867 DippedBeamLamp_stat 6000;
BA_REL_ "GenSigTimeoutTime" BU_SG_REL_ IC SG_ 867 DippedBeamLamp_stat 1500;
BA_REL_ "GenSigFirstTimeoutTime" BU_SG_REL_ IC SG_ 867 ChassiInstepLightsLamp_stat 6000;
BA_REL_ "GenSigTimeoutTime" BU_SG_REL_ IC SG_ 867 ChassiInstepLightsLamp_stat 1500;
BA_REL_ "GenSigFirstTimeoutTime" BU_SG_REL_ IC SG_ 867 DRLLamp_stat 6000;
BA_REL_ "GenSigTimeoutTime" BU_SG_REL_ IC SG_ 867 DRLLamp_stat 1500;
BA_REL_ "GenSigFirstTimeoutTime" BU_SG_REL_ IC SG_ 867 TrailerDirIndRightOutputStat 6000;
BA_REL_ "GenSigTimeoutTime" BU_SG_REL_ IC SG_ 867 TrailerDirIndRightOutputStat 1500;
BA_REL_ "GenSigFirstTimeoutTime" BU_SG_REL_ IC SG_ 867 HeadlampFan_stat 6000;
BA_REL_ "GenSigTimeoutTime" BU_SG_REL_ IC SG_ 867 HeadlampFan_stat 1500;
BA_REL_ "GenSigFirstTimeoutTime" BU_SG_REL_ IC SG_ 867 MainBeamLamp_stat 6000;
BA_REL_ "GenSigTimeoutTime" BU_SG_REL_ IC SG_ 867 MainBeamLamp_stat 1500;
BA_REL_ "GenSigFirstTimeoutTime" BU_SG_REL_ IC SG_ 867 StaticCornerLightLamp_stat 6000;
BA_REL_ "GenSigTimeoutTime" BU_SG_REL_ IC SG_ 867 StaticCornerLightLamp_stat 1500;
BA_REL_ "GenSigFirstTimeoutTime" BU_SG_REL_ IC SG_ 867 AuxFogLightLamp_stat 6000;
BA_REL_ "GenSigTimeoutTime" BU_SG_REL_ IC SG_ 867 AuxFogLightLamp_stat 1500;
BA_REL_ "GenSigFirstTimeoutTime" BU_SG_REL_ IC SG_ 867 PositionLightLamp_stat 6000;
BA_REL_ "GenSigTimeoutTime" BU_SG_REL_ IC SG_ 867 PositionLightLamp_stat 1500;
BA_REL_ "GenSigFirstTimeoutTime" BU_SG_REL_ IC SG_ 866 LoadDistributionSelected2 6000;
BA_REL_ "GenSigTimeoutTime" BU_SG_REL_ IC SG_ 866 LoadDistributionSelected2 1500;
BA_REL_ "GenSigFirstTimeoutTime" BU_SG_REL_ IC SG_ 866 DriveAxleLoad 6000;
BA_REL_ "GenSigTimeoutTime" BU_SG_REL_ IC SG_ 866 DriveAxleLoad 1500;
BA_REL_ "GenSigFirstTimeoutTime" BU_SG_REL_ IC SG_ 866 StarterMotorRecoveryTime 6000;
BA_REL_ "GenSigTimeoutTime" BU_SG_REL_ IC SG_ 866 StarterMotorRecoveryTime 1500;
BA_REL_ "GenSigFirstTimeoutTime" BU_SG_REL_ CCM SG_ 865 MonthLocal 6000;
BA_REL_ "GenSigTimeoutTime" BU_SG_REL_ CCM SG_ 865 MonthLocal 1500;
BA_REL_ "GenSigFirstTimeoutTime" BU_SG_REL_ CCM SG_ 865 SecondsLocal 6000;
BA_REL_ "GenSigTimeoutTime" BU_SG_REL_ CCM SG_ 865 SecondsLocal 1500;
BA_REL_ "GenSigFirstTimeoutTime" BU_SG_REL_ CCM SG_ 865 YearLocal 6000;
BA_REL_ "GenSigTimeoutTime" BU_SG_REL_ CCM SG_ 865 YearLocal 1500;
BA_REL_ "GenSigFirstTimeoutTime" BU_SG_REL_ CCM SG_ 865 DayLocal 6000;
BA_REL_ "GenSigTimeoutTime" BU_SG_REL_ CCM SG_ 865 DayLocal 1500;
BA_REL_ "GenSigFirstTimeoutTime" BU_SG_REL_ CCM SG_ 865 MinutesLocal 6000;
BA_REL_ "GenSigTimeoutTime" BU_SG_REL_ CCM SG_ 865 MinutesLocal 1500;
BA_REL_ "GenSigFirstTimeoutTime" BU_SG_REL_ CCM SG_ 865 HoursLocal 6000;
BA_REL_ "GenSigTimeoutTime" BU_SG_REL_ CCM SG_ 865 HoursLocal 1500;
BA_REL_ "GenSigFirstTimeoutTime" BU_SG_REL_ CCM SG_ 865 DayOfWeek_stat 6000;
BA_REL_ "GenSigTimeoutTime" BU_SG_REL_ CCM SG_ 865 DayOfWeek_stat 1500;
BA_REL_ "GenSigFirstTimeoutTime" BU_SG_REL_ IC SG_ 865 DayOfWeek_stat 6000;
BA_REL_ "GenSigTimeoutTime" BU_SG_REL_ IC SG_ 865 DayOfWeek_stat 1500;
BA_REL_ "GenSigFirstTimeoutTime" BU_SG_REL_ CCM SG_ 864 SecondsUTC 6000;
BA_REL_ "GenSigTimeoutTime" BU_SG_REL_ CCM SG_ 864 SecondsUTC 1500;
BA_REL_ "GenSigFirstTimeoutTime" BU_SG_REL_ CCM SG_ 864 MinutesUTC 6000;
BA_REL_ "GenSigTimeoutTime" BU_SG_REL_ CCM SG_ 864 MinutesUTC 1500;
BA_REL_ "GenSigFirstTimeoutTime" BU_SG_REL_ CCM SG_ 864 MonthUTC 6000;
BA_REL_ "GenSigTimeoutTime" BU_SG_REL_ CCM SG_ 864 MonthUTC 1500;
BA_REL_ "GenSigFirstTimeoutTime" BU_SG_REL_ CCM SG_ 864 YearUTC 6000;
BA_REL_ "GenSigTimeoutTime" BU_SG_REL_ CCM SG_ 864 YearUTC 1500;
BA_REL_ "GenSigFirstTimeoutTime" BU_SG_REL_ CCM SG_ 864 DayUTC 6000;
BA_REL_ "GenSigTimeoutTime" BU_SG_REL_ CCM SG_ 864 DayUTC 1500;
BA_REL_ "GenSigFirstTimeoutTime" BU_SG_REL_ CCM SG_ 864 HoursUTC 6000;
BA_REL_ "GenSigTimeoutTime" BU_SG_REL_ CCM SG_ 864 HoursUTC 1500;
BA_REL_ "GenSigFirstTimeoutTime" BU_SG_REL_ IC SG_ 696 RedGladHand_SqC 3000;
BA_REL_ "GenSigTimeoutTime" BU_SG_REL_ IC SG_ 696 RedGladHand_SqC 600;
BA_REL_ "GenSigFirstTimeoutTime" BU_SG_REL_ IC SG_ 696 RedGladHand_CRC 3000;
BA_REL_ "GenSigTimeoutTime" BU_SG_REL_ IC SG_ 696 RedGladHand_CRC 600;
BA_REL_ "GenSigFirstTimeoutTime" BU_SG_REL_ IC SG_ 696 TrailerStatus_IntegrityLvl 3000;
BA_REL_ "GenSigTimeoutTime" BU_SG_REL_ IC SG_ 696 TrailerStatus_IntegrityLvl 600;
BA_REL_ "GenSigFirstTimeoutTime" BU_SG_REL_ IC SG_ 696 TrailerStatus_CRC 3000;
BA_REL_ "GenSigTimeoutTime" BU_SG_REL_ IC SG_ 696 TrailerStatus_CRC 600;
BA_REL_ "GenSigFirstTimeoutTime" BU_SG_REL_ IC SG_ 696 RedGladHand_ConfidenceLvl 3000;
BA_REL_ "GenSigTimeoutTime" BU_SG_REL_ IC SG_ 696 RedGladHand_ConfidenceLvl 600;
BA_REL_ "GenSigFirstTimeoutTime" BU_SG_REL_ IC SG_ 696 TrailerStatus_SqC 3000;
BA_REL_ "GenSigTimeoutTime" BU_SG_REL_ IC SG_ 696 TrailerStatus_SqC 600;
BA_REL_ "GenSigFirstTimeoutTime" BU_SG_REL_ IC SG_ 696 TrailerStatus_Actuation 3000;
BA_REL_ "GenSigTimeoutTime" BU_SG_REL_ IC SG_ 696 TrailerStatus_Actuation 600;
BA_REL_ "GenSigFirstTimeoutTime" BU_SG_REL_ IC SG_ 696 RedGladHand_ConnectStatus 3000;
BA_REL_ "GenSigTimeoutTime" BU_SG_REL_ IC SG_ 696 RedGladHand_ConnectStatus 600;
BA_REL_ "GenSigFirstTimeoutTime" BU_SG_REL_ IC SG_ 695 TrafficSitPathEvent2_Type 3000;
BA_REL_ "GenSigTimeoutTime" BU_SG_REL_ IC SG_ 695 TrafficSitPathEvent2_Type 600;
BA_REL_ "GenSigFirstTimeoutTime" BU_SG_REL_ IC SG_ 695 TrafficSitPathEvent1_Distance 3000;
BA_REL_ "GenSigTimeoutTime" BU_SG_REL_ IC SG_ 695 TrafficSitPathEvent1_Distance 600;
BA_REL_ "GenSigFirstTimeoutTime" BU_SG_REL_ IC SG_ 695 TrafficSitPathEvent1_Speed 3000;
BA_REL_ "GenSigTimeoutTime" BU_SG_REL_ IC SG_ 695 TrafficSitPathEvent1_Speed 600;
BA_REL_ "GenSigFirstTimeoutTime" BU_SG_REL_ IC SG_ 695 TrafficSitPathEvent2_Speed 3000;
BA_REL_ "GenSigTimeoutTime" BU_SG_REL_ IC SG_ 695 TrafficSitPathEvent2_Speed 600;
BA_REL_ "GenSigFirstTimeoutTime" BU_SG_REL_ IC SG_ 695 TrafficSitPathEvent1_Type 3000;
BA_REL_ "GenSigTimeoutTime" BU_SG_REL_ IC SG_ 695 TrafficSitPathEvent1_Type 600;
BA_REL_ "GenSigFirstTimeoutTime" BU_SG_REL_ IC SG_ 695 TrafficSitPathEvent2_Distance 3000;
BA_REL_ "GenSigTimeoutTime" BU_SG_REL_ IC SG_ 695 TrafficSitPathEvent2_Distance 600;
BA_REL_ "GenSigFirstTimeoutTime" BU_SG_REL_ IC SG_ 694 BatteryCapacity 3000;
BA_REL_ "GenSigTimeoutTime" BU_SG_REL_ IC SG_ 694 BatteryCapacity 600;
BA_REL_ "GenSigFirstTimeoutTime" BU_SG_REL_ IC SG_ 694 BatteryCurrent 3000;
BA_REL_ "GenSigTimeoutTime" BU_SG_REL_ IC SG_ 694 BatteryCurrent 600;
BA_REL_ "GenSigFirstTimeoutTime" BU_SG_REL_ IC SG_ 694 AmbientLight_stat 3000;
BA_REL_ "GenSigTimeoutTime" BU_SG_REL_ IC SG_ 694 AmbientLight_stat 600;
BA_REL_ "GenSigFirstTimeoutTime" BU_SG_REL_ IC SG_ 693 TransmissionRangeSelected 3000;
BA_REL_ "GenSigTimeoutTime" BU_SG_REL_ IC SG_ 693 TransmissionRangeSelected 600;
BA_REL_ "GenSigFirstTimeoutTime" BU_SG_REL_ IC SG_ 693 TransmissionRangeAttained 3000;
BA_REL_ "GenSigTimeoutTime" BU_SG_REL_ IC SG_ 693 TransmissionRangeAttained 600;
BA_REL_ "GenSigFirstTimeoutTime" BU_SG_REL_ IC SG_ 693 FrontRoadWheelAngleEstimate1 3000;
BA_REL_ "GenSigTimeoutTime" BU_SG_REL_ IC SG_ 693 FrontRoadWheelAngleEstimate1 600;
BA_REL_ "GenSigFirstTimeoutTime" BU_SG_REL_ CCM SG_ 693 WheelBasedVehicleSpeed 3000;
BA_REL_ "GenSigTimeoutTime" BU_SG_REL_ CCM SG_ 693 WheelBasedVehicleSpeed 600;
BA_REL_ "GenSigFirstTimeoutTime" BU_SG_REL_ IC SG_ 692 BatterySOCactCriticalAlert 3000;
BA_REL_ "GenSigTimeoutTime" BU_SG_REL_ IC SG_ 692 BatterySOCactCriticalAlert 600;
BA_REL_ "GenSigFirstTimeoutTime" BU_SG_REL_ IC SG_ 692 BatterySOCTrustLevel 3000;
BA_REL_ "GenSigTimeoutTime" BU_SG_REL_ IC SG_ 692 BatterySOCTrustLevel 600;
BA_REL_ "GenSigFirstTimeoutTime" BU_SG_REL_ IC SG_ 692 BatterySOCnom 3000;
BA_REL_ "GenSigTimeoutTime" BU_SG_REL_ IC SG_ 692 BatterySOCnom 600;
BA_REL_ "GenSigFirstTimeoutTime" BU_SG_REL_ IC SG_ 692 BatteryTemp 3000;
BA_REL_ "GenSigTimeoutTime" BU_SG_REL_ IC SG_ 692 BatteryTemp 600;
BA_REL_ "GenSigFirstTimeoutTime" BU_SG_REL_ IC SG_ 692 BatteryVoltageDisplayValue 3000;
BA_REL_ "GenSigTimeoutTime" BU_SG_REL_ IC SG_ 692 BatteryVoltageDisplayValue 600;
BA_REL_ "GenSigFirstTimeoutTime" BU_SG_REL_ IC SG_ 692 BatterySOCact 3000;
BA_REL_ "GenSigTimeoutTime" BU_SG_REL_ IC SG_ 692 BatterySOCact 600;
BA_REL_ "GenSigFirstTimeoutTime" BU_SG_REL_ IC SG_ 692 BatterySOH 3000;
BA_REL_ "GenSigTimeoutTime" BU_SG_REL_ IC SG_ 692 BatterySOH 600;
VAL_ 880 PHTimerTGWEvCmd_PhTimer1_cmd 7 "PhTimer_cmd_NotAvailable" 6 "PhTimer_cmd_Error" 5 "PhTimer_cmd_Spare_02" 4 "PhTimer_cmd_Spare_01" 3 "PhTimer_cmd_TimerDeleted" 2 "PhTimer_cmd_TimerDisable" 1 "PhTimer_cmd_TimerEnable" 0 "PhTimer_cmd_NoAction" ;
VAL_ 880 PHTimerTGWEvCmd_Timer2Temp 31 "TemperatureRqstIndication_cmd_NotAvailable" 30 "TemperatureRqstIndication_cmd_Error" 29 "TemperatureRqstIndication_cmd_Spare_01" 28 "TemperatureRqstIndication_cmd_Spare" 27 "TemperatureRqstIndication_cmd_Max" 26 "TemperatureRqstIndication_cmd_29C" 25 "TemperatureRqstIndication_cmd_28C" 24 "TemperatureRqstIndication_cmd_27C" 23 "TemperatureRqstIndication_cmd_26C" 22 "TemperatureRqstIndication_cmd_25_5C" 21 "TemperatureRqstIndication_cmd_25C" 20 "TemperatureRqstIndication_cmd_24_5C" 19 "TemperatureRqstIndication_cmd_24C" 18 "TemperatureRqstIndication_cmd_23_5C" 17 "TemperatureRqstIndication_cmd_23C" 16 "TemperatureRqstIndication_cmd_22_5C" 15 "TemperatureRqstIndication_cmd_22C" 14 "TemperatureRqstIndication_cmd_21_5C" 13 "TemperatureRqstIndication_cmd_21C" 12 "TemperatureRqstIndication_cmd_20_5C" 11 "TemperatureRqstIndication_cmd_20C" 10 "TemperatureRqstIndication_cmd_19_5C" 9 "TemperatureRqstIndication_cmd_19C" 8 "TemperatureRqstIndication_cmd_18_5C" 7 "TemperatureRqstIndication_cmd_18C" 6 "TemperatureRqstIndication_cmd_17_5C" 5 "TemperatureRqstIndication_cmd_17C" 4 "TemperatureRqstIndication_cmd_16_5C" 3 "TemperatureRqstIndication_cmd_16C" 2 "TemperatureRqstIndication_cmd_15C" 1 "TemperatureRqstIndication_cmd_Min" 0 "TemperatureRqstIndication_cmd_NoTempDisplayed" ;
VAL_ 880 PHTimerTGWEvCmd_Timer3StartDay 15 "HeaterTimerStartDay_NotAvailable" 14 "HeaterTimerStartDay_Error" 13 "HeaterTimerStartDay_Spare_05" 12 "HeaterTimerStartDay_Spare_04" 11 "HeaterTimerStartDay_Spare_03" 10 "HeaterTimerStartDay_Spare_02" 9 "HeaterTimerStartDay_Spare_01" 8 "HeaterTimerStartDay_Spare" 7 "HeaterTimerStartDay_Sunday" 6 "HeaterTimerStartDay_Saturday" 5 "HeaterTimerStartDay_Friday" 4 "HeaterTimerStartDay_Thursday" 3 "HeaterTimerStartDay_Wednesday" 2 "HeaterTimerStartDay_Tuesday" 1 "HeaterTimerStartDay_Monday" 0 "HeaterTimerStartDay_NotUsed" ;
VAL_ 880 PHTimerTGWEvCmd_Timer2StartDay 15 "HeaterTimerStartDay_NotAvailable" 14 "HeaterTimerStartDay_Error" 13 "HeaterTimerStartDay_Spare_05" 12 "HeaterTimerStartDay_Spare_04" 11 "HeaterTimerStartDay_Spare_03" 10 "HeaterTimerStartDay_Spare_02" 9 "HeaterTimerStartDay_Spare_01" 8 "HeaterTimerStartDay_Spare" 7 "HeaterTimerStartDay_Sunday" 6 "HeaterTimerStartDay_Saturday" 5 "HeaterTimerStartDay_Friday" 4 "HeaterTimerStartDay_Thursday" 3 "HeaterTimerStartDay_Wednesday" 2 "HeaterTimerStartDay_Tuesday" 1 "HeaterTimerStartDay_Monday" 0 "HeaterTimerStartDay_NotUsed" ;
VAL_ 880 PHTimerTGWEvCmd_PhTimer3_cmd 7 "PhTimer_cmd_NotAvailable" 6 "PhTimer_cmd_Error" 5 "PhTimer_cmd_Spare_02" 4 "PhTimer_cmd_Spare_01" 3 "PhTimer_cmd_TimerDeleted" 2 "PhTimer_cmd_TimerDisable" 1 "PhTimer_cmd_TimerEnable" 0 "PhTimer_cmd_NoAction" ;
VAL_ 880 PHTimerTGWEvCmd_Timer2Recur 15 "HeaterTimerRecurrence_NotAvailable" 14 "HeaterTimerRecurrence_Error" 13 "HeaterTimerRecurrence_Spare_3" 12 "HeaterTimerRecurrence_Spare_2" 11 "HeaterTimerRecurrence_Spare_1" 10 "HeaterTimerRecurrence_Sundays" 9 "HeaterTimerRecurrence_Saturdays" 8 "HeaterTimerRecurrence_Fridays" 7 "HeaterTimerRecurrence_Thursdays" 6 "HeaterTimerRecurrence_Wednesdays" 5 "HeaterTimerRecurrence_Tuesdays" 4 "HeaterTimerRecurrence_Mondays" 3 "HeaterTimerRecurrence_Weekends" 2 "HeaterTimerRecurrence_AllWeekdays" 1 "HeaterTimerRecurrence_Daily" 0 "HeaterTimerRecurrence_None" ;
VAL_ 880 PHTimerTGWEvCmd_PhTimer2_cmd 7 "PhTimer_cmd_NotAvailable" 6 "PhTimer_cmd_Error" 5 "PhTimer_cmd_Spare_02" 4 "PhTimer_cmd_Spare_01" 3 "PhTimer_cmd_TimerDeleted" 2 "PhTimer_cmd_TimerDisable" 1 "PhTimer_cmd_TimerEnable" 0 "PhTimer_cmd_NoAction" ;
VAL_ 880 PHTimerTGWEvCmd_Timer3Temp 31 "TemperatureRqstIndication_cmd_NotAvailable" 30 "TemperatureRqstIndication_cmd_Error" 29 "TemperatureRqstIndication_cmd_Spare_01" 28 "TemperatureRqstIndication_cmd_Spare" 27 "TemperatureRqstIndication_cmd_Max" 26 "TemperatureRqstIndication_cmd_29C" 25 "TemperatureRqstIndication_cmd_28C" 24 "TemperatureRqstIndication_cmd_27C" 23 "TemperatureRqstIndication_cmd_26C" 22 "TemperatureRqstIndication_cmd_25_5C" 21 "TemperatureRqstIndication_cmd_25C" 20 "TemperatureRqstIndication_cmd_24_5C" 19 "TemperatureRqstIndication_cmd_24C" 18 "TemperatureRqstIndication_cmd_23_5C" 17 "TemperatureRqstIndication_cmd_23C" 16 "TemperatureRqstIndication_cmd_22_5C" 15 "TemperatureRqstIndication_cmd_22C" 14 "TemperatureRqstIndication_cmd_21_5C" 13 "TemperatureRqstIndication_cmd_21C" 12 "TemperatureRqstIndication_cmd_20_5C" 11 "TemperatureRqstIndication_cmd_20C" 10 "TemperatureRqstIndication_cmd_19_5C" 9 "TemperatureRqstIndication_cmd_19C" 8 "TemperatureRqstIndication_cmd_18_5C" 7 "TemperatureRqstIndication_cmd_18C" 6 "TemperatureRqstIndication_cmd_17_5C" 5 "TemperatureRqstIndication_cmd_17C" 4 "TemperatureRqstIndication_cmd_16_5C" 3 "TemperatureRqstIndication_cmd_16C" 2 "TemperatureRqstIndication_cmd_15C" 1 "TemperatureRqstIndication_cmd_Min" 0 "TemperatureRqstIndication_cmd_NoTempDisplayed" ;
VAL_ 880 PHTimerTGWEvCmd_Timer3Recur 15 "HeaterTimerRecurrence_NotAvailable" 14 "HeaterTimerRecurrence_Error" 13 "HeaterTimerRecurrence_Spare_3" 12 "HeaterTimerRecurrence_Spare_2" 11 "HeaterTimerRecurrence_Spare_1" 10 "HeaterTimerRecurrence_Sundays" 9 "HeaterTimerRecurrence_Saturdays" 8 "HeaterTimerRecurrence_Fridays" 7 "HeaterTimerRecurrence_Thursdays" 6 "HeaterTimerRecurrence_Wednesdays" 5 "HeaterTimerRecurrence_Tuesdays" 4 "HeaterTimerRecurrence_Mondays" 3 "HeaterTimerRecurrence_Weekends" 2 "HeaterTimerRecurrence_AllWeekdays" 1 "HeaterTimerRecurrence_Daily" 0 "HeaterTimerRecurrence_None" ;
VAL_ 880 PHTimerTGWEvCmd_Timer1Recur 15 "HeaterTimerRecurrence_NotAvailable" 14 "HeaterTimerRecurrence_Error" 13 "HeaterTimerRecurrence_Spare_3" 12 "HeaterTimerRecurrence_Spare_2" 11 "HeaterTimerRecurrence_Spare_1" 10 "HeaterTimerRecurrence_Sundays" 9 "HeaterTimerRecurrence_Saturdays" 8 "HeaterTimerRecurrence_Fridays" 7 "HeaterTimerRecurrence_Thursdays" 6 "HeaterTimerRecurrence_Wednesdays" 5 "HeaterTimerRecurrence_Tuesdays" 4 "HeaterTimerRecurrence_Mondays" 3 "HeaterTimerRecurrence_Weekends" 2 "HeaterTimerRecurrence_AllWeekdays" 1 "HeaterTimerRecurrence_Daily" 0 "HeaterTimerRecurrence_None" ;
VAL_ 880 PHTimerTGWEvCmd_Timer1StartDay 15 "HeaterTimerStartDay_NotAvailable" 14 "HeaterTimerStartDay_Error" 13 "HeaterTimerStartDay_Spare_05" 12 "HeaterTimerStartDay_Spare_04" 11 "HeaterTimerStartDay_Spare_03" 10 "HeaterTimerStartDay_Spare_02" 9 "HeaterTimerStartDay_Spare_01" 8 "HeaterTimerStartDay_Spare" 7 "HeaterTimerStartDay_Sunday" 6 "HeaterTimerStartDay_Saturday" 5 "HeaterTimerStartDay_Friday" 4 "HeaterTimerStartDay_Thursday" 3 "HeaterTimerStartDay_Wednesday" 2 "HeaterTimerStartDay_Tuesday" 1 "HeaterTimerStartDay_Monday" 0 "HeaterTimerStartDay_NotUsed" ;
VAL_ 880 PHTimerTGWEvCmd_Timer1Temp 31 "TemperatureRqstIndication_cmd_NotAvailable" 30 "TemperatureRqstIndication_cmd_Error" 29 "TemperatureRqstIndication_cmd_Spare_01" 28 "TemperatureRqstIndication_cmd_Spare" 27 "TemperatureRqstIndication_cmd_Max" 26 "TemperatureRqstIndication_cmd_29C" 25 "TemperatureRqstIndication_cmd_28C" 24 "TemperatureRqstIndication_cmd_27C" 23 "TemperatureRqstIndication_cmd_26C" 22 "TemperatureRqstIndication_cmd_25_5C" 21 "TemperatureRqstIndication_cmd_25C" 20 "TemperatureRqstIndication_cmd_24_5C" 19 "TemperatureRqstIndication_cmd_24C" 18 "TemperatureRqstIndication_cmd_23_5C" 17 "TemperatureRqstIndication_cmd_23C" 16 "TemperatureRqstIndication_cmd_22_5C" 15 "TemperatureRqstIndication_cmd_22C" 14 "TemperatureRqstIndication_cmd_21_5C" 13 "TemperatureRqstIndication_cmd_21C" 12 "TemperatureRqstIndication_cmd_20_5C" 11 "TemperatureRqstIndication_cmd_20C" 10 "TemperatureRqstIndication_cmd_19_5C" 9 "TemperatureRqstIndication_cmd_19C" 8 "TemperatureRqstIndication_cmd_18_5C" 7 "TemperatureRqstIndication_cmd_18C" 6 "TemperatureRqstIndication_cmd_17_5C" 5 "TemperatureRqstIndication_cmd_17C" 4 "TemperatureRqstIndication_cmd_16_5C" 3 "TemperatureRqstIndication_cmd_16C" 2 "TemperatureRqstIndication_cmd_15C" 1 "TemperatureRqstIndication_cmd_Min" 0 "TemperatureRqstIndication_cmd_NoTempDisplayed" ;
VAL_ 1209 LNGRestrictionStatus_Spare4 1 "InactiveActive1b_Active" 0 "InactiveActive1b_Inactive" ;
VAL_ 1209 LNGRestrictionStatus_V1Closed 1 "InactiveActive1b_Active" 0 "InactiveActive1b_Inactive" ;
VAL_ 1209 LNGRestrictionStatus_Spare3 1 "InactiveActive1b_Active" 0 "InactiveActive1b_Inactive" ;
VAL_ 1209 LngTank2WarnStat 3 "OkEmpty_NotAvailable" 2 "OkEmpty_Error" 1 "OkEmpty_Empty" 0 "OkEmpty_OK" ;
VAL_ 1209 LNGRestrictionStatus_Spare2 1 "InactiveActive1b_Active" 0 "InactiveActive1b_Inactive" ;
VAL_ 1209 LngSystemReadinessStat 7 "LngSystemReadinessStat_NotAvailable" 6 "LngSystemReadinessStat_Error" 5 "LngSystemReadinessStat_Spare2" 4 "LngSystemReadinessStat_Spare1" 3 "LngSystemReadinessStat_LNGSystemReady" 2 "LngSystemReadinessStat_LNGInLimpingMode" 1 "LngSystemReadinessStat_LNGSystemWarmingUpPleaseWait" 0 "LngSystemReadinessStat_LNGSystemOff" ;
VAL_ 1209 LNGOperatorInducementReason 7 "LNGOperatorInducementReason_NotAvailable" 6 "LNGOperatorInducementReason_Error" 5 "LNGOperatorInducementReason_Spare2" 4 "LNGOperatorInducementReason_Spare1" 3 "LNGOperatorInducementReason_IncorrectConsumption" 2 "LNGOperatorInducementReason_GasSupplyMalfunction" 1 "LNGOperatorInducementReason_LNGLevelLow" 0 "LNGOperatorInducementReason_OK" ;
VAL_ 1209 LNGRestrictionStatus_Spare1 1 "InactiveActive1b_Active" 0 "InactiveActive1b_Inactive" ;
VAL_ 1209 LNGRestrictionStatus_V2Closed 1 "InactiveActive1b_Active" 0 "InactiveActive1b_Inactive" ;
VAL_ 1209 LngTank1WarnStat 3 "OkEmpty_NotAvailable" 2 "OkEmpty_Error" 1 "OkEmpty_Empty" 0 "OkEmpty_OK" ;
VAL_ 1209 LNGRestrictionStatus_SInfo 3 "SignalInfo2bitType_NotAvailable" 2 "SignalInfo2bitType_ErrorIndication" 1 "SignalInfo2bitType_Spare" 0 "SignalInfo2bitType_Valid" ;
VAL_ 1209 LngGspWarnStat 3 "OkPrepareToDerate_NotAvailable" 2 "OkPrepareToDerate_Error" 1 "OkPrepareToDerate_PrepareToDerate" 0 "OkPrepareToDerate_Ok" ;
VAL_ 1202 SCROperatorInducementSeverity 7 "SCROperatorInducementSeverity_NotAvailable" 6 "SCROperatorInducementSeverity_Reserved" 5 "SCROperatorInducementSeverity_SevereInducementActive" 4 "SCROperatorInducementSeverity_SevereIndEnabledWaitActCondition" 3 "SCROperatorInducementSeverity_IndLevel3LowLevelInducementActive" 2 "SCROperatorInducementSeverity_IndLevel2IntensiveWarning" 1 "SCROperatorInducementSeverity_IndLevel1InitialWarning" 0 "SCROperatorInducementSeverity_NoInducementActive" ;
VAL_ 1202 CatalystTankLevelLow 3 "Warning_NotAvailable" 2 "Warning_Error" 1 "Warning_Warning" 0 "Warning_NoWarning" ;
VAL_ 1202 MIStatusExtEMS 3 "MIStatusExt_NotAvailable" 2 "MIStatusExt_Error" 1 "MIStatusExt_Ready" 0 "MIStatusExt_NotReady5Flash" ;
VAL_ 1202 FuelOperatorDeratingReason 3 "FuelOperatorDeratingReason_NotAvailable" 2 "FuelOperatorDeratingReason_IncorrectQuality" 1 "FuelOperatorDeratingReason_IncorrectFuelBlend" 0 "FuelOperatorDeratingReason_FuelBlendOK" ;
VAL_ 1202 ActualFasPersSettingsButton 7 "FasPersSettingsButton_NotAvailable" 6 "FasPersSettingsButton_Error" 5 "FasPersSettingsButton_Spare" 4 "FasPersSettingsButton_UserDefinedButton" 3 "FasPersSettingsButton_PresetButtonHeavy" 2 "FasPersSettingsButton_PresetButtonFirm" 1 "FasPersSettingsButton_PresetButtonLight" 0 "FasPersSettingsButton_PresetButtonDefault" ;
VAL_ 1202 BatteryEndOfCharge 3 "FalseTrue_NotAvaiable" 2 "FalseTrue_Error" 1 "FalseTrue_True" 0 "FalseTrue_False" ;
VAL_ 1202 LiningWearWarning 3 "Warning_NotAvailable" 2 "Warning_Error" 1 "Warning_Warning" 0 "Warning_NoWarning" ;
VAL_ 1202 TorqueReductionStatus_OBD 7 "TorqueReductionStatus_OBD_NotAvailable" 6 "TorqueReductionStatus_OBD_Error" 5 "TorqueReductionStatus_OBD_Spare_01" 4 "TorqueReductionStatus_OBD_Spare" 3 "TorqueReductionStatus_OBD_TorqueReductionActive" 2 "TorqueReductionStatus_OBD_TorqueReductionActiveNextStandstill" 1 "TorqueReductionStatus_OBD_Pending" 0 "TorqueReductionStatus_OBD_NotActive" ;
VAL_ 1202 LoadCalibrationFeedback 7 "LoadCalibrationFeedback_NotAvailable" 6 "LoadCalibrationFeedback_Spare3" 5 "LoadCalibrationFeedback_Spare2" 4 "LoadCalibrationFeedback_Spare1" 3 "LoadCalibrationFeedback_NOK" 2 "LoadCalibrationFeedback_OK" 1 "LoadCalibrationFeedback_InProgress" 0 "LoadCalibrationFeedback_NotRequested" ;
VAL_ 1202 FuelOperatorDeratingSeverity 7 "FuelOperatorDeratingSeverity_NotAvailable" 6 "FuelOperatorDeratingSeverity_TemporaryOverrideOfDerating" 5 "FuelOperatorDeratingSeverity_SevereDerate" 4 "FuelOperatorDeratingSeverity_SevereDeratePending" 3 "FuelOperatorDeratingSeverity_EngineDerate" 2 "FuelOperatorDeratingSeverity_EngineDeratePending" 1 "FuelOperatorDeratingSeverity_Warning" 0 "FuelOperatorDeratingSeverity_NoDeratingActive" ;
VAL_ 1202 SCROperatorInducementReason 7 "SCROperatorInducementReason_NotAvailable" 6 "SCROperatorInducementReason_Error" 5 "SCROperatorInducementReason_Spare" 4 "SCROperatorInducementReason_Tampering" 3 "SCROperatorInducementReason_IncorrectConsumption" 2 "SCROperatorInducementReason_IncorrectQuality" 1 "SCROperatorInducementReason_ReagentLevelLow" 0 "SCROperatorInducementReason_OK" ;
VAL_ 1202 MIDistinctWarningExtEMS 15 "MIDistinctWarningExt_NotAvailable" 14 "MIDistinctWarningExt_Error" 3 "MIDistinctWarningExt_ContinuousMISteady" 2 "MIDistinctWarningExt_ShortMI3Flash" 1 "MIDistinctWarningExt_OnDemandMI2Flash" 0 "MIDistinctWarningExt_Off1Flash" ;
VAL_ 1202 FasDriver 15 "FasDriver_NotAvailable" 14 "FasDriver_Error" 13 "FasDriver_Spare3" 12 "FasDriver_Spare2" 11 "FasDriver_Spare1" 10 "FasDriver_Driver10" 9 "FasDriver_Driver9" 8 "FasDriver_Driver8" 7 "FasDriver_Driver7" 6 "FasDriver_Driver6" 5 "FasDriver_Driver5" 4 "FasDriver_Driver4" 3 "FasDriver_Driver3" 2 "FasDriver_Driver2" 1 "FasDriver_Driver1" 0 "FasDriver_DefaultDriver" ;
VAL_ 1202 MIDistinctWarning 3 "OffOn_NotAvailable" 2 "OffOn_Error" 1 "OffOn_On" 0 "OffOn_Off" ;
VAL_ 902 Cur_EnergySetting 7 "EnergySetting_NotAvailable" 6 "EnergySetting_Error" 5 "EnergySetting_Spare2" 4 "EnergySetting_Spare1" 3 "EnergySetting_Customise" 2 "EnergySetting_PresetLevel2_HighEnergySaving" 1 "EnergySetting_PresetLevel1_EnergySaving" 0 "EnergySetting_OFF" ;
VAL_ 902 UltracapDisplay_Stat 7 "StartBatteryDisplay_NotAvailable" 6 "StartBatteryDisplay_Error" 5 "StartBatteryDisplay_StartBattery_ShortCircuit" 4 "StartBatteryDisplay_StartBattery_OverVoltage" 3 "StartBatteryDisplay_StartBattery_OpenCircuit" 2 "StartBatteryDisplay_StartBattery_Idle" 1 "StartBatteryDisplay_StartBattery_Charged" 0 "StartBatteryDisplay_StartBattery_Charging" ;
VAL_ 902 Ultracap_Status 7 "Ultracap_Status_NotAvailable" 6 "Ultracap_Status_Error" 5 "Ultracap_Status_Spare3" 4 "Ultracap_Status_Spare2" 3 "Ultracap_Status_Spare1" 2 "Ultracap_Status_Malfunction" 1 "Ultracap_Status_ForceCharging" 0 "Ultracap_Status_Healthy" ;
VAL_ 901 AxleLoadStatus 7 "AxleLoadStatus_NotAvailable" 6 "AxleLoadStatus_Error" 5 "AxleLoadStatus_Spare2" 4 "AxleLoadStatus_Spare1" 3 "AxleLoadStatus_Overload" 2 "AxleLoadStatus_HighLoad2" 1 "AxleLoadStatus_HighLoad1" 0 "AxleLoadStatus_NormalLoad" ;
VAL_ 901 ClutchAbuseStatus 3 "ClutchAbuseStatus_NotAvailable" 2 "ClutchAbuseStatus_Error" 1 "ClutchAbuseStatus_ClutchAbused" 0 "ClutchAbuseStatus_ClutchNotAbused" ;
VAL_ 901 ISeeStatus 7 "ISeeStatus_NotAvailable" 6 "ISeeStatus_Error" 5 "ISeeStatus_Spare2" 4 "ISeeStatus_Spare1" 3 "ISeeStatus_EnabledAndActive" 2 "ISeeStatus_EnabledButInactive" 1 "ISeeStatus_Disabled" 0 "ISeeStatus_Off" ;
VAL_ 901 TransmissionSplitboxPTOMode 7 "TransmissionSplitboxPTOMode_NotAvailable" 6 "TransmissionSplitboxPTOMode_Error" 5 "TransmissionSplitboxPTOMode_Spare3" 4 "TransmissionSplitboxPTOMode_Spare2" 3 "TransmissionSplitboxPTOMode_Spare1" 2 "TransmissionSplitboxPTOMode_Running" 1 "TransmissionSplitboxPTOMode_Standby" 0 "TransmissionSplitboxPTOMode_Inactive" ;
VAL_ 901 OilLevelDrvInstr_IncorrEngSpe 3 "DisplayText_NotAvailable" 2 "DisplayText_Error" 1 "DisplayText_DisplayText" 0 "DisplayText_DoNotDisplayText" ;
VAL_ 901 OilLevelDrvInstr_ChangeGearTxt 3 "DisplayText_NotAvailable" 2 "DisplayText_Error" 1 "DisplayText_DisplayText" 0 "DisplayText_DoNotDisplayText" ;
VAL_ 901 PredeliveryModeIndication_cmd 3 "DeactivateActivate_NotAvailable" 2 "DeactivateActivate_Error" 1 "DeactivateActivate_Activate" 0 "DeactivateActivate_Deactivate" ;
VAL_ 901 OilLevelDrvInstr_Wait60SecTxt 3 "DisplayText_NotAvailable" 2 "DisplayText_Error" 1 "DisplayText_DisplayText" 0 "DisplayText_DoNotDisplayText" ;
VAL_ 901 DPF_LimitedSpeedDuetoInhibit 7 "LimitedSpeedInhibit_NotAvailable" 6 "LimitedSpeedInhibit_Error" 5 "LimitedSpeedInhibit_Spare2" 4 "LimitedSpeedInhibit_Spare1" 3 "LimitedSpeedInhibit_SpeedNotLimited_InhibitActive" 2 "LimitedSpeedInhibit_SpeedNotLimited_InhibitDenied" 1 "LimitedSpeedInhibit_SpeedLimited_InhibitionActive" 0 "LimitedSpeedInhibit_SpeedNotLimited_NoInhibitRequest" ;
VAL_ 901 DPF_ParkedRegenStatus 7 "ParkedRegenStatus_NotAvailable" 6 "ParkedRegenStatus_Error" 5 "ParkedRegenStatus_Spare2" 4 "ParkedRegenStatus_HCRegenOngoing" 3 "ParkedRegenStatus_ParkedRegenOngoing" 2 "ParkedRegenStatus_Aborted" 1 "ParkedRegenStatus_Completed" 0 "ParkedRegenStatus_NoInformation" ;
VAL_ 901 OilLevelDrvInstr_OilTempTxt 3 "DisplayText_NotAvailable" 2 "DisplayText_Error" 1 "DisplayText_DisplayText" 0 "DisplayText_DoNotDisplayText" ;
VAL_ 901 OilLevelDrvInstr_StopVehicle 3 "DisplayText_NotAvailable" 2 "DisplayText_Error" 1 "DisplayText_DisplayText" 0 "DisplayText_DoNotDisplayText" ;
VAL_ 901 ClutchCalibration_stat 3 "InactiveActive_NotAvailable" 2 "InactiveActive_Error" 1 "InactiveActive_Active" 0 "InactiveActive_Inactive" ;
VAL_ 901 OilLevelDrvInstr_NotHorizonTxt 3 "DisplayText_NotAvailable" 2 "DisplayText_Error" 1 "DisplayText_DisplayText" 0 "DisplayText_DoNotDisplayText" ;
VAL_ 868 DrainPrimingStatus 7 "DrainPrimingStatus_NotAvailable" 6 "DrainPrimingStatus_Error" 5 "DrainPrimingStatus_SpareValue_01" 4 "DrainPrimingStatus_SpareValue" 3 "DrainPrimingStatus_DrainingActive" 2 "DrainPrimingStatus_PrimingActive" 1 "DrainPrimingStatus_DrainingPrimingNotAllowed" 0 "DrainPrimingStatus_DrainingPrimingInactive" ;
VAL_ 868 FrontConspicLamp_stat_HiRight 7 "LampCheck_stat_NotAvailable" 6 "LampCheck_stat_Error" 5 "LampCheck_stat_Spare_02" 4 "LampCheck_stat_Spare_01" 3 "LampCheck_stat_Spare" 2 "LampCheck_stat_TestedLampNOK" 1 "LampCheck_stat_TestedLampOK" 0 "LampCheck_stat_NotTested" ;
VAL_ 868 FrontConspicLamp_stat_LoRight 7 "LampCheck_stat_NotAvailable" 6 "LampCheck_stat_Error" 5 "LampCheck_stat_Spare_02" 4 "LampCheck_stat_Spare_01" 3 "LampCheck_stat_Spare" 2 "LampCheck_stat_TestedLampNOK" 1 "LampCheck_stat_TestedLampOK" 0 "LampCheck_stat_NotTested" ;
VAL_ 868 CoolantTempHigh 7 "TempHigh3bit_NotAvailable" 6 "TempHigh3bit_Error" 5 "TempHigh3bit_HighLevel5" 4 "TempHigh3bit_HighLevel4" 3 "TempHigh3bit_HighLevel3" 2 "TempHigh3bit_HighLevel2" 1 "TempHigh3bit_HighLevel1" 0 "TempHigh3bit_OK" ;
VAL_ 868 AutoWheelBrakesStatus 7 "AutoWheelBrakesStatus_NotAvailable" 6 "AutoWheelBrakesStatus_Error" 5 "AutoWheelBrakesStatus_Spare3" 4 "AutoWheelBrakesStatus_Spare2" 3 "AutoWheelBrakesStatus_AWBActive" 2 "AutoWheelBrakesStatus_ReducedAutoBraking_WithoutSerBrkDemand" 1 "AutoWheelBrakesStatus_FullAutoBraking_withSerBrksDemand" 0 "AutoWheelBrakesStatus_NoAutoBrakingActive" ;
VAL_ 868 OilLevelLow 7 "LevelLow3bit_NotAvailable" 6 "LevelLow3bit_Error" 5 "LevelLow3bit_LowLevel5" 4 "LevelLow3bit_LowLevel4" 3 "LevelLow3bit_LowLevel3" 2 "LevelLow3bit_LowLevel2" 1 "LevelLow3bit_LowLevel1" 0 "LevelLow3bit_OK" ;
VAL_ 868 InletAirHeaterStatus1 3 "OffOn_NotAvailable" 2 "OffOn_Error" 1 "OffOn_On" 0 "OffOn_Off" ;
VAL_ 868 DeicingFunction_Stat 7 "DeicingFunction_Stat_NotAvailable" 6 "DeicingFunction_Stat_Spare2" 5 "DeicingFunction_Stat_Spare1" 4 "DeicingFunction_Stat_Fault" 3 "DeicingFunction_Stat_Deactivated" 2 "DeicingFunction_Stat_Ongoing" 1 "DeicingFunction_Stat_Activated" 0 "DeicingFunction_Stat_NotTested" ;
VAL_ 868 SelfStartAssist_stat 3 "SelfStartAssist_stat_NotAvailable" 2 "SelfStartAssist_stat_Requested_Initiated" 1 "SelfStartAssist_stat_Ready" 0 "SelfStartAssist_stat_NotRequested" ;
VAL_ 868 TrailerDirIndLeftOutputStat 7 "TrailerLightOutputStat_NotAvailable" 6 "TrailerLightOutputStat_Error" 5 "TrailerLightOutputStat_OutputActiveStatusUncertain" 4 "TrailerLightOutputStat_OutputActiveLightDetectedOnActivation" 3 "TrailerLightOutputStat_OutputActiveLightDetected" 2 "TrailerLightOutputStat_OutputActiveNoLightDetected" 1 "TrailerLightOutputStat_OutputActiveDetectionOngoing" 0 "TrailerLightOutputStat_OutputInactive" ;
VAL_ 868 TrailerPosLightLeftOutputStat 7 "TrailerLightOutputStat_NotAvailable" 6 "TrailerLightOutputStat_Error" 5 "TrailerLightOutputStat_OutputActiveStatusUncertain" 4 "TrailerLightOutputStat_OutputActiveLightDetectedOnActivation" 3 "TrailerLightOutputStat_OutputActiveLightDetected" 2 "TrailerLightOutputStat_OutputActiveNoLightDetected" 1 "TrailerLightOutputStat_OutputActiveDetectionOngoing" 0 "TrailerLightOutputStat_OutputInactive" ;
VAL_ 868 TrailerBrakeLightOutputStat 7 "TrailerLightOutputStat_NotAvailable" 6 "TrailerLightOutputStat_Error" 5 "TrailerLightOutputStat_OutputActiveStatusUncertain" 4 "TrailerLightOutputStat_OutputActiveLightDetectedOnActivation" 3 "TrailerLightOutputStat_OutputActiveLightDetected" 2 "TrailerLightOutputStat_OutputActiveNoLightDetected" 1 "TrailerLightOutputStat_OutputActiveDetectionOngoing" 0 "TrailerLightOutputStat_OutputInactive" ;
VAL_ 868 StartBatteryDisplay_stat 7 "StartBatteryDisplay_NotAvailable" 6 "StartBatteryDisplay_Error" 5 "StartBatteryDisplay_StartBattery_ShortCircuit" 4 "StartBatteryDisplay_StartBattery_OverVoltage" 3 "StartBatteryDisplay_StartBattery_OpenCircuit" 2 "StartBatteryDisplay_StartBattery_Idle" 1 "StartBatteryDisplay_StartBattery_Charged" 0 "StartBatteryDisplay_StartBattery_Charging" ;
VAL_ 868 DeicingBulb_Stat 7 "DeicingBulb_Stat_NotAvailable" 6 "DeicingBulb_Stat_Error" 5 "DeicingBulb_Stat_Spare2" 4 "DeicingBulb_Stat_Spare1" 3 "DeicingBulb_Stat_BothLampsNOK" 2 "DeicingBulb_Stat_AtleastOneLampOK" 1 "DeicingBulb_Stat_BothLampsOK" 0 "DeicingBulb_Stat_NotTested" ;
VAL_ 868 LivBatDisconnectDetectStat 3 "LivBatDisconnectDetectStat_Not_Available" 2 "LivBatDisconnectDetectStat_Error" 1 "LivBatDisconnectDetectStat_Battery_Disconnected" 0 "LivBatDisconnectDetectStat_Battery_NotDisconnected" ;
VAL_ 868 FrontConspicLamp_stat_LoLeft 7 "LampCheck_stat_NotAvailable" 6 "LampCheck_stat_Error" 5 "LampCheck_stat_Spare_02" 4 "LampCheck_stat_Spare_01" 3 "LampCheck_stat_Spare" 2 "LampCheck_stat_TestedLampNOK" 1 "LampCheck_stat_TestedLampOK" 0 "LampCheck_stat_NotTested" ;
VAL_ 868 FuelFilterClogged 7 "LevelLow3bit_NotAvailable" 6 "LevelLow3bit_Error" 5 "LevelLow3bit_LowLevel5" 4 "LevelLow3bit_LowLevel4" 3 "LevelLow3bit_LowLevel3" 2 "LevelLow3bit_LowLevel2" 1 "LevelLow3bit_LowLevel1" 0 "LevelLow3bit_OK" ;
VAL_ 868 EngineFanOverspeed 3 "NoYes_NotAvailable" 2 "NoYes_Error" 1 "NoYes_Yes" 0 "NoYes_No" ;
VAL_ 868 JumpChargeInterface_stat 3 "Connection_Status_NotAvailable" 2 "Connection_Status_Error" 1 "Connection_Status_Connected" 0 "Connection_Status_NotConnected" ;
VAL_ 868 OilPressureLow 7 "LevelLow3bit_NotAvailable" 6 "LevelLow3bit_Error" 5 "LevelLow3bit_LowLevel5" 4 "LevelLow3bit_LowLevel4" 3 "LevelLow3bit_LowLevel3" 2 "LevelLow3bit_LowLevel2" 1 "LevelLow3bit_LowLevel1" 0 "LevelLow3bit_OK" ;
VAL_ 868 FrontConspicLamp_stat_HiLeft 7 "LampCheck_stat_NotAvailable" 6 "LampCheck_stat_Error" 5 "LampCheck_stat_Spare_02" 4 "LampCheck_stat_Spare_01" 3 "LampCheck_stat_Spare" 2 "LampCheck_stat_TestedLampNOK" 1 "LampCheck_stat_TestedLampOK" 0 "LampCheck_stat_NotTested" ;
VAL_ 868 GChargerStatus 7 "GridCharger_stat_NotAvailable" 6 "GridCharger_stat_Error" 5 "GridCharger_stat_GridchargerTemperatureIssue" 4 "GridCharger_stat_Reversepolarityissue" 3 "GridCharger_stat_MaintenanceCharging" 2 "GridCharger_stat_Charging" 1 "GridCharger_stat_Connected" 0 "GridCharger_stat_NotConnected" ;
VAL_ 868 TrailerRevAndFogOutput_stat 3 "TrailerRevAndFogOutput_stat_NotAvailable" 2 "TrailerRevAndFogOutput_stat_AtLeastOneLampNotOK" 1 "TrailerRevAndFogOutput_stat_AllLampsOK" 0 "TrailerRevAndFogOutput_stat_NotTested" ;
VAL_ 867 DirIndSideLamp_stat 7 "LampCheckLeftRight_stat_NotAvailable" 6 "LampCheckLeftRight_stat_Error" 5 "LampCheckLeftRight_stat_Spare" 4 "LampCheckLeftRight_stat_TestedLeftAndRightLampNOK" 3 "LampCheckLeftRight_stat_TestedRightLampNOK" 2 "LampCheckLeftRight_stat_TestedLeftLampNOK" 1 "LampCheckLeftRight_stat_TestedLampOK" 0 "LampCheckLeftRight_stat_NotTested" ;
VAL_ 867 DirInd_Front_Status 7 "DirIndFaultStatus_NotAvailable" 6 "DirIndFaultStatus_Error" 5 "DirIndFaultStatus_SpareValue_01" 4 "DirIndFaultStatus_SpareValue" 3 "DirIndFaultStatus_BothLeftAndRightDirectionIndicatorsFault" 2 "DirIndFaultStatus_RightDirectionIndicatorLampFault" 1 "DirIndFaultStatus_LeftDirectionIndicatorLampFault" 0 "DirIndFaultStatus_NoError" ;
VAL_ 867 FogLightFrontLamp_stat 7 "LampCheck_stat_NotAvailable" 6 "LampCheck_stat_Error" 5 "LampCheck_stat_Spare_02" 4 "LampCheck_stat_Spare_01" 3 "LampCheck_stat_Spare" 2 "LampCheck_stat_TestedLampNOK" 1 "LampCheck_stat_TestedLampOK" 0 "LampCheck_stat_NotTested" ;
VAL_ 867 MainBeamLEDStatusRight 7 "LampCheck_stat_NotAvailable" 6 "LampCheck_stat_Error" 5 "LampCheck_stat_Spare_02" 4 "LampCheck_stat_Spare_01" 3 "LampCheck_stat_Spare" 2 "LampCheck_stat_TestedLampNOK" 1 "LampCheck_stat_TestedLampOK" 0 "LampCheck_stat_NotTested" ;
VAL_ 867 RevLightLamp_stat 7 "LampCheckLeftRight_stat_NotAvailable" 6 "LampCheckLeftRight_stat_Error" 5 "LampCheckLeftRight_stat_Spare" 4 "LampCheckLeftRight_stat_TestedLeftAndRightLampNOK" 3 "LampCheckLeftRight_stat_TestedRightLampNOK" 2 "LampCheckLeftRight_stat_TestedLeftLampNOK" 1 "LampCheckLeftRight_stat_TestedLampOK" 0 "LampCheckLeftRight_stat_NotTested" ;
VAL_ 867 ExtraMainBeamLamp_stat 7 "LampCheckLeftRight_stat_NotAvailable" 6 "LampCheckLeftRight_stat_Error" 5 "LampCheckLeftRight_stat_Spare" 4 "LampCheckLeftRight_stat_TestedLeftAndRightLampNOK" 3 "LampCheckLeftRight_stat_TestedRightLampNOK" 2 "LampCheckLeftRight_stat_TestedLeftLampNOK" 1 "LampCheckLeftRight_stat_TestedLampOK" 0 "LampCheckLeftRight_stat_NotTested" ;
VAL_ 867 MainBeamLEDStatusLeft 7 "LampCheck_stat_NotAvailable" 6 "LampCheck_stat_Error" 5 "LampCheck_stat_Spare_02" 4 "LampCheck_stat_Spare_01" 3 "LampCheck_stat_Spare" 2 "LampCheck_stat_TestedLampNOK" 1 "LampCheck_stat_TestedLampOK" 0 "LampCheck_stat_NotTested" ;
VAL_ 867 PositionLightRearLamp_stat 7 "LampCheckLeftRight_stat_NotAvailable" 6 "LampCheckLeftRight_stat_Error" 5 "LampCheckLeftRight_stat_Spare" 4 "LampCheckLeftRight_stat_TestedLeftAndRightLampNOK" 3 "LampCheckLeftRight_stat_TestedRightLampNOK" 2 "LampCheckLeftRight_stat_TestedLeftLampNOK" 1 "LampCheckLeftRight_stat_TestedLampOK" 0 "LampCheckLeftRight_stat_NotTested" ;
VAL_ 867 TrailerPosLightRightOutputStat 7 "TrailerLightOutputStat_NotAvailable" 6 "TrailerLightOutputStat_Error" 5 "TrailerLightOutputStat_OutputActiveStatusUncertain" 4 "TrailerLightOutputStat_OutputActiveLightDetectedOnActivation" 3 "TrailerLightOutputStat_OutputActiveLightDetected" 2 "TrailerLightOutputStat_OutputActiveNoLightDetected" 1 "TrailerLightOutputStat_OutputActiveDetectionOngoing" 0 "TrailerLightOutputStat_OutputInactive" ;
VAL_ 867 DirIndRearLamp_Stat 7 "LampCheckLeftRight_stat_NotAvailable" 6 "LampCheckLeftRight_stat_Error" 5 "LampCheckLeftRight_stat_Spare" 4 "LampCheckLeftRight_stat_TestedLeftAndRightLampNOK" 3 "LampCheckLeftRight_stat_TestedRightLampNOK" 2 "LampCheckLeftRight_stat_TestedLeftLampNOK" 1 "LampCheckLeftRight_stat_TestedLampOK" 0 "LampCheckLeftRight_stat_NotTested" ;
VAL_ 867 FogLightRearLamp_stat 7 "LampCheck_stat_NotAvailable" 6 "LampCheck_stat_Error" 5 "LampCheck_stat_Spare_02" 4 "LampCheck_stat_Spare_01" 3 "LampCheck_stat_Spare" 2 "LampCheck_stat_TestedLampNOK" 1 "LampCheck_stat_TestedLampOK" 0 "LampCheck_stat_NotTested" ;
VAL_ 867 BrakeLightLamp_stat 7 "LampCheckLeftRight_stat_NotAvailable" 6 "LampCheckLeftRight_stat_Error" 5 "LampCheckLeftRight_stat_Spare" 4 "LampCheckLeftRight_stat_TestedLeftAndRightLampNOK" 3 "LampCheckLeftRight_stat_TestedRightLampNOK" 2 "LampCheckLeftRight_stat_TestedLeftLampNOK" 1 "LampCheckLeftRight_stat_TestedLampOK" 0 "LampCheckLeftRight_stat_NotTested" ;
VAL_ 867 DippedBeamLamp_stat 7 "LampCheckLeftRight_stat_NotAvailable" 6 "LampCheckLeftRight_stat_Error" 5 "LampCheckLeftRight_stat_Spare" 4 "LampCheckLeftRight_stat_TestedLeftAndRightLampNOK" 3 "LampCheckLeftRight_stat_TestedRightLampNOK" 2 "LampCheckLeftRight_stat_TestedLeftLampNOK" 1 "LampCheckLeftRight_stat_TestedLampOK" 0 "LampCheckLeftRight_stat_NotTested" ;
VAL_ 867 ChassiInstepLightsLamp_stat 7 "LampCheck_stat_NotAvailable" 6 "LampCheck_stat_Error" 5 "LampCheck_stat_Spare_02" 4 "LampCheck_stat_Spare_01" 3 "LampCheck_stat_Spare" 2 "LampCheck_stat_TestedLampNOK" 1 "LampCheck_stat_TestedLampOK" 0 "LampCheck_stat_NotTested" ;
VAL_ 867 DRLLamp_stat 7 "LampCheckLeftRight_stat_NotAvailable" 6 "LampCheckLeftRight_stat_Error" 5 "LampCheckLeftRight_stat_Spare" 4 "LampCheckLeftRight_stat_TestedLeftAndRightLampNOK" 3 "LampCheckLeftRight_stat_TestedRightLampNOK" 2 "LampCheckLeftRight_stat_TestedLeftLampNOK" 1 "LampCheckLeftRight_stat_TestedLampOK" 0 "LampCheckLeftRight_stat_NotTested" ;
VAL_ 867 TrailerDirIndRightOutputStat 7 "TrailerLightOutputStat_NotAvailable" 6 "TrailerLightOutputStat_Error" 5 "TrailerLightOutputStat_OutputActiveStatusUncertain" 4 "TrailerLightOutputStat_OutputActiveLightDetectedOnActivation" 3 "TrailerLightOutputStat_OutputActiveLightDetected" 2 "TrailerLightOutputStat_OutputActiveNoLightDetected" 1 "TrailerLightOutputStat_OutputActiveDetectionOngoing" 0 "TrailerLightOutputStat_OutputInactive" ;
VAL_ 867 HeadlampFan_stat 7 "LampFanTestStat_NotAvailable" 6 "LampFanTestStat_Error" 5 "LampFanTestStat_Spare3" 4 "LampFanTestStat_Spare2" 3 "LampFanTestStat_Spare1" 2 "LampFanTestStat_FanTestedNOK" 1 "LampFanTestStat_FanTestedOK" 0 "LampFanTestStat_NotTested" ;
VAL_ 867 MainBeamLamp_stat 7 "LampCheckLeftRight_stat_NotAvailable" 6 "LampCheckLeftRight_stat_Error" 5 "LampCheckLeftRight_stat_Spare" 4 "LampCheckLeftRight_stat_TestedLeftAndRightLampNOK" 3 "LampCheckLeftRight_stat_TestedRightLampNOK" 2 "LampCheckLeftRight_stat_TestedLeftLampNOK" 1 "LampCheckLeftRight_stat_TestedLampOK" 0 "LampCheckLeftRight_stat_NotTested" ;
VAL_ 867 StaticCornerLightLamp_stat 7 "LampCheckLeftRight_stat_NotAvailable" 6 "LampCheckLeftRight_stat_Error" 5 "LampCheckLeftRight_stat_Spare" 4 "LampCheckLeftRight_stat_TestedLeftAndRightLampNOK" 3 "LampCheckLeftRight_stat_TestedRightLampNOK" 2 "LampCheckLeftRight_stat_TestedLeftLampNOK" 1 "LampCheckLeftRight_stat_TestedLampOK" 0 "LampCheckLeftRight_stat_NotTested" ;
VAL_ 867 AuxFogLightLamp_stat 7 "LampCheckLeftRight_stat_NotAvailable" 6 "LampCheckLeftRight_stat_Error" 5 "LampCheckLeftRight_stat_Spare" 4 "LampCheckLeftRight_stat_TestedLeftAndRightLampNOK" 3 "LampCheckLeftRight_stat_TestedRightLampNOK" 2 "LampCheckLeftRight_stat_TestedLeftLampNOK" 1 "LampCheckLeftRight_stat_TestedLampOK" 0 "LampCheckLeftRight_stat_NotTested" ;
VAL_ 867 PositionLightLamp_stat 7 "LampCheckLeftRight_stat_NotAvailable" 6 "LampCheckLeftRight_stat_Error" 5 "LampCheckLeftRight_stat_Spare" 4 "LampCheckLeftRight_stat_TestedLeftAndRightLampNOK" 3 "LampCheckLeftRight_stat_TestedRightLampNOK" 2 "LampCheckLeftRight_stat_TestedLeftLampNOK" 1 "LampCheckLeftRight_stat_TestedLampOK" 0 "LampCheckLeftRight_stat_NotTested" ;
VAL_ 866 LoadDistributionSelected2 15 "LoadDistributionSelected2_NotAvailable" 14 "LoadDistributionSelected2_Error" 13 "LoadDistributionSelected2_Reserved_01" 12 "LoadDistributionSelected2_TractionHelp2InterDiff" 11 "LoadDistributionSelected2_StartingHelp2InterDiff" 10 "LoadDistributionSelected2_TractionHelp2" 9 "LoadDistributionSelected2_StartingHelp2" 8 "LoadDistributionSelected2_VariableAxleLoad" 7 "LoadDistributionSelected2_NoLoadDistribution" 6 "LoadDistributionSelected2_TractionHelpInterDiff" 5 "LoadDistributionSelected2_StartingHelpInterDiff" 4 "LoadDistributionSelected2_AlternativeLoad" 3 "LoadDistributionSelected2_TractionHelp" 2 "LoadDistributionSelected2_StartingHelp" 1 "LoadDistributionSelected2_OptimisedTraction" 0 "LoadDistributionSelected2_NormalLoad" ;
VAL_ 865 DayOfWeek_stat 15 "DayOfWeek_NotAvailable" 14 "DayOfWeek_Error" 13 "DayOfWeek_Spare_7" 12 "DayOfWeek_Spare_6" 11 "DayOfWeek_Spare_5" 10 "DayOfWeek_Spare_4" 9 "DayOfWeek_Spare_3" 8 "DayOfWeek_Spare_2" 7 "DayOfWeek_Spare_1" 6 "DayOfWeek_Sunday" 5 "DayOfWeek_Saturday" 4 "DayOfWeek_Friday" 3 "DayOfWeek_Thursday" 2 "DayOfWeek_Wednesday" 1 "DayOfWeek_Tuesday" 0 "DayOfWeek_Monday" ;
VAL_ 696 TrailerStatus_IntegrityLvl 3 "IntegrityLvl_HighIntegrity" 2 "IntegrityLvl_Spare" 1 "IntegrityLvl_LowIntegrity" 0 "IntegrityLvl_Downgraded" ;
VAL_ 696 RedGladHand_ConfidenceLvl 3 "LowHigh_NotAvailable" 2 "LowHigh_Error" 1 "LowHigh_High" 0 "LowHigh_Low" ;
VAL_ 696 TrailerStatus_Actuation 7 "TrailerStatusActuation_NotAvailable" 6 "TrailerStatusActuation_Error" 5 "TrailerStatusActuation_Spare3" 4 "TrailerStatusActuation_Spare2" 3 "TrailerStatusActuation_Spare1" 2 "TrailerStatusActuation_Deflated" 1 "TrailerStatusActuation_Intermediate" 0 "TrailerStatusActuation_Inflated" ;
VAL_ 696 RedGladHand_ConnectStatus 3 "TLConnectStatus_NotAvailable" 2 "TLConnectStatus_Unknown" 1 "TLConnectStatus_Attached" 0 "TLConnectStatus_Detached" ;
VAL_ 695 TrafficSitPathEvent2_Type 255 "TrafficSitEventType_NotAvailable" 254 "TrafficSitEventType_Error" 253 "TrafficSitEventType_NotUsed3" 252 "TrafficSitEventType_NotUsed2" 251 "TrafficSitEventType_NotUsed1" 250 "TrafficSitEventType_GeneralEvent" 249 "TrafficSitEventType_spare242" 248 "TrafficSitEventType_spare241" 247 "TrafficSitEventType_spare240" 246 "TrafficSitEventType_spare239" 245 "TrafficSitEventType_spare238" 244 "TrafficSitEventType_spare237" 243 "TrafficSitEventType_spare236" 242 "TrafficSitEventType_spare235" 241 "TrafficSitEventType_spare234" 240 "TrafficSitEventType_spare233" 239 "TrafficSitEventType_spare232" 238 "TrafficSitEventType_spare231" 237 "TrafficSitEventType_spare230" 236 "TrafficSitEventType_spare229" 235 "TrafficSitEventType_spare228" 234 "TrafficSitEventType_spare227" 233 "TrafficSitEventType_spare226" 232 "TrafficSitEventType_spare225" 231 "TrafficSitEventType_spare224" 230 "TrafficSitEventType_spare223" 229 "TrafficSitEventType_spare222" 228 "TrafficSitEventType_spare221" 227 "TrafficSitEventType_spare220" 226 "TrafficSitEventType_spare219" 225 "TrafficSitEventType_spare218" 224 "TrafficSitEventType_spare217" 223 "TrafficSitEventType_spare216" 222 "TrafficSitEventType_spare215" 221 "TrafficSitEventType_spare214" 220 "TrafficSitEventType_spare213" 219 "TrafficSitEventType_spare212" 218 "TrafficSitEventType_spare211" 217 "TrafficSitEventType_spare210" 216 "TrafficSitEventType_spare209" 215 "TrafficSitEventType_spare208" 214 "TrafficSitEventType_spare207" 213 "TrafficSitEventType_spare206" 212 "TrafficSitEventType_spare205" 211 "TrafficSitEventType_spare204" 210 "TrafficSitEventType_spare203" 209 "TrafficSitEventType_spare202" 208 "TrafficSitEventType_spare201" 207 "TrafficSitEventType_spare200" 206 "TrafficSitEventType_spare199" 205 "TrafficSitEventType_spare198" 204 "TrafficSitEventType_spare197" 203 "TrafficSitEventType_spare196" 202 "TrafficSitEventType_spare195" 201 "TrafficSitEventType_spare194" 200 "TrafficSitEventType_spare193" 199 "TrafficSitEventType_spare192" 198 "TrafficSitEventType_spare191" 197 "TrafficSitEventType_spare190" 196 "TrafficSitEventType_spare189" 195 "TrafficSitEventType_spare188" 194 "TrafficSitEventType_spare187" 193 "TrafficSitEventType_spare186" 192 "TrafficSitEventType_spare185" 191 "TrafficSitEventType_spare184" 190 "TrafficSitEventType_spare183" 189 "TrafficSitEventType_spare182" 188 "TrafficSitEventType_spare181" 187 "TrafficSitEventType_spare180" 186 "TrafficSitEventType_spare179" 185 "TrafficSitEventType_spare178" 184 "TrafficSitEventType_spare177" 183 "TrafficSitEventType_spare176" 182 "TrafficSitEventType_spare175" 181 "TrafficSitEventType_spare174" 180 "TrafficSitEventType_spare173" 179 "TrafficSitEventType_spare172" 178 "TrafficSitEventType_spare171" 177 "TrafficSitEventType_spare170" 176 "TrafficSitEventType_spare169" 175 "TrafficSitEventType_spare168" 174 "TrafficSitEventType_spare167" 173 "TrafficSitEventType_spare166" 172 "TrafficSitEventType_spare165" 171 "TrafficSitEventType_spare164" 170 "TrafficSitEventType_spare163" 169 "TrafficSitEventType_spare162" 168 "TrafficSitEventType_spare161" 167 "TrafficSitEventType_spare160" 166 "TrafficSitEventType_spare159" 165 "TrafficSitEventType_spare158" 164 "TrafficSitEventType_spare157" 163 "TrafficSitEventType_spare156" 162 "TrafficSitEventType_spare155" 161 "TrafficSitEventType_spare154" 160 "TrafficSitEventType_spare153" 159 "TrafficSitEventType_spare152" 158 "TrafficSitEventType_spare151" 157 "TrafficSitEventType_spare150" 156 "TrafficSitEventType_spare149" 155 "TrafficSitEventType_spare148" 154 "TrafficSitEventType_spare147" 153 "TrafficSitEventType_spare146" 152 "TrafficSitEventType_spare145" 151 "TrafficSitEventType_spare144" 150 "TrafficSitEventType_spare143" 149 "TrafficSitEventType_spare142" 148 "TrafficSitEventType_spare141" 147 "TrafficSitEventType_spare140" 146 "TrafficSitEventType_spare139" 145 "TrafficSitEventType_spare138" 144 "TrafficSitEventType_spare137" 143 "TrafficSitEventType_spare136" 142 "TrafficSitEventType_spare135" 141 "TrafficSitEventType_spare134" 140 "TrafficSitEventType_spare133" 139 "TrafficSitEventType_spare132" 138 "TrafficSitEventType_spare131" 137 "TrafficSitEventType_spare130" 136 "TrafficSitEventType_spare129" 135 "TrafficSitEventType_spare128" 134 "TrafficSitEventType_spare127" 133 "TrafficSitEventType_spare126" 132 "TrafficSitEventType_spare125" 131 "TrafficSitEventType_spare124" 130 "TrafficSitEventType_spare123" 129 "TrafficSitEventType_spare122" 128 "TrafficSitEventType_spare121" 127 "TrafficSitEventType_spare120" 126 "TrafficSitEventType_spare119" 125 "TrafficSitEventType_spare118" 124 "TrafficSitEventType_spare117" 123 "TrafficSitEventType_spare116" 122 "TrafficSitEventType_spare115" 121 "TrafficSitEventType_spare114" 120 "TrafficSitEventType_spare113" 119 "TrafficSitEventType_spare112" 118 "TrafficSitEventType_spare111" 117 "TrafficSitEventType_spare110" 116 "TrafficSitEventType_spare109" 115 "TrafficSitEventType_spare108" 114 "TrafficSitEventType_spare107" 113 "TrafficSitEventType_spare106" 112 "TrafficSitEventType_spare105" 111 "TrafficSitEventType_spare104" 110 "TrafficSitEventType_spare103" 109 "TrafficSitEventType_spare102" 108 "TrafficSitEventType_spare101" 107 "TrafficSitEventType_spare100" 106 "TrafficSitEventType_spare99" 105 "TrafficSitEventType_spare98" 104 "TrafficSitEventType_spare97" 103 "TrafficSitEventType_spare96" 102 "TrafficSitEventType_spare95" 101 "TrafficSitEventType_spare94" 100 "TrafficSitEventType_spare93" 99 "TrafficSitEventType_spare92" 98 "TrafficSitEventType_spare91" 97 "TrafficSitEventType_spare90" 96 "TrafficSitEventType_spare89" 95 "TrafficSitEventType_spare88" 94 "TrafficSitEventType_spare87" 93 "TrafficSitEventType_spare86" 92 "TrafficSitEventType_spare85" 91 "TrafficSitEventType_spare84" 90 "TrafficSitEventType_spare83" 89 "TrafficSitEventType_spare82" 88 "TrafficSitEventType_spare81" 87 "TrafficSitEventType_spare80" 86 "TrafficSitEventType_spare79" 85 "TrafficSitEventType_spare78" 84 "TrafficSitEventType_spare77" 83 "TrafficSitEventType_spare76" 82 "TrafficSitEventType_spare75" 81 "TrafficSitEventType_spare74" 80 "TrafficSitEventType_spare73" 79 "TrafficSitEventType_spare72" 78 "TrafficSitEventType_spare71" 77 "TrafficSitEventType_spare70" 76 "TrafficSitEventType_spare69" 75 "TrafficSitEventType_spare68" 74 "TrafficSitEventType_spare67" 73 "TrafficSitEventType_spare66" 72 "TrafficSitEventType_spare65" 71 "TrafficSitEventType_spare64" 70 "TrafficSitEventType_spare63" 69 "TrafficSitEventType_spare62" 68 "TrafficSitEventType_spare61" 67 "TrafficSitEventType_spare60" 66 "TrafficSitEventType_spare59" 65 "TrafficSitEventType_spare58" 64 "TrafficSitEventType_spare57" 63 "TrafficSitEventType_spare56" 62 "TrafficSitEventType_spare55" 61 "TrafficSitEventType_spare54" 60 "TrafficSitEventType_spare53" 59 "TrafficSitEventType_spare52" 58 "TrafficSitEventType_spare51" 57 "TrafficSitEventType_spare50" 56 "TrafficSitEventType_spare49" 55 "TrafficSitEventType_spare48" 54 "TrafficSitEventType_spare47" 53 "TrafficSitEventType_spare46" 52 "TrafficSitEventType_spare45" 51 "TrafficSitEventType_spare44" 50 "TrafficSitEventType_spare43" 49 "TrafficSitEventType_spare42" 48 "TrafficSitEventType_spare41" 47 "TrafficSitEventType_spare40" 46 "TrafficSitEventType_spare39" 45 "TrafficSitEventType_spare38" 44 "TrafficSitEventType_spare37" 43 "TrafficSitEventType_spare36" 42 "TrafficSitEventType_spare35" 41 "TrafficSitEventType_spare34" 40 "TrafficSitEventType_spare33" 39 "TrafficSitEventType_spare32" 38 "TrafficSitEventType_spare31" 37 "TrafficSitEventType_spare30" 36 "TrafficSitEventType_spare29" 35 "TrafficSitEventType_spare28" 34 "TrafficSitEventType_spare27" 33 "TrafficSitEventType_spare26" 32 "TrafficSitEventType_spare25" 31 "TrafficSitEventType_spare24" 30 "TrafficSitEventType_spare23" 29 "TrafficSitEventType_spare22" 28 "TrafficSitEventType_spare21" 27 "TrafficSitEventType_spare20" 26 "TrafficSitEventType_spare19" 25 "TrafficSitEventType_spare18" 24 "TrafficSitEventType_spare17" 23 "TrafficSitEventType_spare16" 22 "TrafficSitEventType_spare15" 21 "TrafficSitEventType_spare14" 20 "TrafficSitEventType_spare13" 19 "TrafficSitEventType_spare12" 18 "TrafficSitEventType_spare11" 17 "TrafficSitEventType_spare10" 16 "TrafficSitEventType_spare9" 15 "TrafficSitEventType_spare8" 14 "TrafficSitEventType_spare7" 13 "TrafficSitEventType_spare6" 12 "TrafficSitEventType_spare5" 11 "TrafficSitEventType_spare4" 10 "TrafficSitEventType_spare3" 9 "TrafficSitEventType_spare2" 8 "TrafficSitEventType_spare1" 7 "TrafficSitEventType_NarrowRoad" 6 "TrafficSitEventType_TrafficJam_OR_SlowTraffic" 5 "TrafficSitEventType_Crossing" 4 "TrafficSitEventType_Roundabout" 3 "TrafficSitEventType_CurveRight" 2 "TrafficSitEventType_CurveLeft" 1 "TrafficSitEventType_SpeedLimit" 0 "TrafficSitEventType_NoEvent" ;
VAL_ 695 TrafficSitPathEvent1_Type 255 "TrafficSitEventType_NotAvailable" 254 "TrafficSitEventType_Error" 253 "TrafficSitEventType_NotUsed3" 252 "TrafficSitEventType_NotUsed2" 251 "TrafficSitEventType_NotUsed1" 250 "TrafficSitEventType_GeneralEvent" 249 "TrafficSitEventType_spare242" 248 "TrafficSitEventType_spare241" 247 "TrafficSitEventType_spare240" 246 "TrafficSitEventType_spare239" 245 "TrafficSitEventType_spare238" 244 "TrafficSitEventType_spare237" 243 "TrafficSitEventType_spare236" 242 "TrafficSitEventType_spare235" 241 "TrafficSitEventType_spare234" 240 "TrafficSitEventType_spare233" 239 "TrafficSitEventType_spare232" 238 "TrafficSitEventType_spare231" 237 "TrafficSitEventType_spare230" 236 "TrafficSitEventType_spare229" 235 "TrafficSitEventType_spare228" 234 "TrafficSitEventType_spare227" 233 "TrafficSitEventType_spare226" 232 "TrafficSitEventType_spare225" 231 "TrafficSitEventType_spare224" 230 "TrafficSitEventType_spare223" 229 "TrafficSitEventType_spare222" 228 "TrafficSitEventType_spare221" 227 "TrafficSitEventType_spare220" 226 "TrafficSitEventType_spare219" 225 "TrafficSitEventType_spare218" 224 "TrafficSitEventType_spare217" 223 "TrafficSitEventType_spare216" 222 "TrafficSitEventType_spare215" 221 "TrafficSitEventType_spare214" 220 "TrafficSitEventType_spare213" 219 "TrafficSitEventType_spare212" 218 "TrafficSitEventType_spare211" 217 "TrafficSitEventType_spare210" 216 "TrafficSitEventType_spare209" 215 "TrafficSitEventType_spare208" 214 "TrafficSitEventType_spare207" 213 "TrafficSitEventType_spare206" 212 "TrafficSitEventType_spare205" 211 "TrafficSitEventType_spare204" 210 "TrafficSitEventType_spare203" 209 "TrafficSitEventType_spare202" 208 "TrafficSitEventType_spare201" 207 "TrafficSitEventType_spare200" 206 "TrafficSitEventType_spare199" 205 "TrafficSitEventType_spare198" 204 "TrafficSitEventType_spare197" 203 "TrafficSitEventType_spare196" 202 "TrafficSitEventType_spare195" 201 "TrafficSitEventType_spare194" 200 "TrafficSitEventType_spare193" 199 "TrafficSitEventType_spare192" 198 "TrafficSitEventType_spare191" 197 "TrafficSitEventType_spare190" 196 "TrafficSitEventType_spare189" 195 "TrafficSitEventType_spare188" 194 "TrafficSitEventType_spare187" 193 "TrafficSitEventType_spare186" 192 "TrafficSitEventType_spare185" 191 "TrafficSitEventType_spare184" 190 "TrafficSitEventType_spare183" 189 "TrafficSitEventType_spare182" 188 "TrafficSitEventType_spare181" 187 "TrafficSitEventType_spare180" 186 "TrafficSitEventType_spare179" 185 "TrafficSitEventType_spare178" 184 "TrafficSitEventType_spare177" 183 "TrafficSitEventType_spare176" 182 "TrafficSitEventType_spare175" 181 "TrafficSitEventType_spare174" 180 "TrafficSitEventType_spare173" 179 "TrafficSitEventType_spare172" 178 "TrafficSitEventType_spare171" 177 "TrafficSitEventType_spare170" 176 "TrafficSitEventType_spare169" 175 "TrafficSitEventType_spare168" 174 "TrafficSitEventType_spare167" 173 "TrafficSitEventType_spare166" 172 "TrafficSitEventType_spare165" 171 "TrafficSitEventType_spare164" 170 "TrafficSitEventType_spare163" 169 "TrafficSitEventType_spare162" 168 "TrafficSitEventType_spare161" 167 "TrafficSitEventType_spare160" 166 "TrafficSitEventType_spare159" 165 "TrafficSitEventType_spare158" 164 "TrafficSitEventType_spare157" 163 "TrafficSitEventType_spare156" 162 "TrafficSitEventType_spare155" 161 "TrafficSitEventType_spare154" 160 "TrafficSitEventType_spare153" 159 "TrafficSitEventType_spare152" 158 "TrafficSitEventType_spare151" 157 "TrafficSitEventType_spare150" 156 "TrafficSitEventType_spare149" 155 "TrafficSitEventType_spare148" 154 "TrafficSitEventType_spare147" 153 "TrafficSitEventType_spare146" 152 "TrafficSitEventType_spare145" 151 "TrafficSitEventType_spare144" 150 "TrafficSitEventType_spare143" 149 "TrafficSitEventType_spare142" 148 "TrafficSitEventType_spare141" 147 "TrafficSitEventType_spare140" 146 "TrafficSitEventType_spare139" 145 "TrafficSitEventType_spare138" 144 "TrafficSitEventType_spare137" 143 "TrafficSitEventType_spare136" 142 "TrafficSitEventType_spare135" 141 "TrafficSitEventType_spare134" 140 "TrafficSitEventType_spare133" 139 "TrafficSitEventType_spare132" 138 "TrafficSitEventType_spare131" 137 "TrafficSitEventType_spare130" 136 "TrafficSitEventType_spare129" 135 "TrafficSitEventType_spare128" 134 "TrafficSitEventType_spare127" 133 "TrafficSitEventType_spare126" 132 "TrafficSitEventType_spare125" 131 "TrafficSitEventType_spare124" 130 "TrafficSitEventType_spare123" 129 "TrafficSitEventType_spare122" 128 "TrafficSitEventType_spare121" 127 "TrafficSitEventType_spare120" 126 "TrafficSitEventType_spare119" 125 "TrafficSitEventType_spare118" 124 "TrafficSitEventType_spare117" 123 "TrafficSitEventType_spare116" 122 "TrafficSitEventType_spare115" 121 "TrafficSitEventType_spare114" 120 "TrafficSitEventType_spare113" 119 "TrafficSitEventType_spare112" 118 "TrafficSitEventType_spare111" 117 "TrafficSitEventType_spare110" 116 "TrafficSitEventType_spare109" 115 "TrafficSitEventType_spare108" 114 "TrafficSitEventType_spare107" 113 "TrafficSitEventType_spare106" 112 "TrafficSitEventType_spare105" 111 "TrafficSitEventType_spare104" 110 "TrafficSitEventType_spare103" 109 "TrafficSitEventType_spare102" 108 "TrafficSitEventType_spare101" 107 "TrafficSitEventType_spare100" 106 "TrafficSitEventType_spare99" 105 "TrafficSitEventType_spare98" 104 "TrafficSitEventType_spare97" 103 "TrafficSitEventType_spare96" 102 "TrafficSitEventType_spare95" 101 "TrafficSitEventType_spare94" 100 "TrafficSitEventType_spare93" 99 "TrafficSitEventType_spare92" 98 "TrafficSitEventType_spare91" 97 "TrafficSitEventType_spare90" 96 "TrafficSitEventType_spare89" 95 "TrafficSitEventType_spare88" 94 "TrafficSitEventType_spare87" 93 "TrafficSitEventType_spare86" 92 "TrafficSitEventType_spare85" 91 "TrafficSitEventType_spare84" 90 "TrafficSitEventType_spare83" 89 "TrafficSitEventType_spare82" 88 "TrafficSitEventType_spare81" 87 "TrafficSitEventType_spare80" 86 "TrafficSitEventType_spare79" 85 "TrafficSitEventType_spare78" 84 "TrafficSitEventType_spare77" 83 "TrafficSitEventType_spare76" 82 "TrafficSitEventType_spare75" 81 "TrafficSitEventType_spare74" 80 "TrafficSitEventType_spare73" 79 "TrafficSitEventType_spare72" 78 "TrafficSitEventType_spare71" 77 "TrafficSitEventType_spare70" 76 "TrafficSitEventType_spare69" 75 "TrafficSitEventType_spare68" 74 "TrafficSitEventType_spare67" 73 "TrafficSitEventType_spare66" 72 "TrafficSitEventType_spare65" 71 "TrafficSitEventType_spare64" 70 "TrafficSitEventType_spare63" 69 "TrafficSitEventType_spare62" 68 "TrafficSitEventType_spare61" 67 "TrafficSitEventType_spare60" 66 "TrafficSitEventType_spare59" 65 "TrafficSitEventType_spare58" 64 "TrafficSitEventType_spare57" 63 "TrafficSitEventType_spare56" 62 "TrafficSitEventType_spare55" 61 "TrafficSitEventType_spare54" 60 "TrafficSitEventType_spare53" 59 "TrafficSitEventType_spare52" 58 "TrafficSitEventType_spare51" 57 "TrafficSitEventType_spare50" 56 "TrafficSitEventType_spare49" 55 "TrafficSitEventType_spare48" 54 "TrafficSitEventType_spare47" 53 "TrafficSitEventType_spare46" 52 "TrafficSitEventType_spare45" 51 "TrafficSitEventType_spare44" 50 "TrafficSitEventType_spare43" 49 "TrafficSitEventType_spare42" 48 "TrafficSitEventType_spare41" 47 "TrafficSitEventType_spare40" 46 "TrafficSitEventType_spare39" 45 "TrafficSitEventType_spare38" 44 "TrafficSitEventType_spare37" 43 "TrafficSitEventType_spare36" 42 "TrafficSitEventType_spare35" 41 "TrafficSitEventType_spare34" 40 "TrafficSitEventType_spare33" 39 "TrafficSitEventType_spare32" 38 "TrafficSitEventType_spare31" 37 "TrafficSitEventType_spare30" 36 "TrafficSitEventType_spare29" 35 "TrafficSitEventType_spare28" 34 "TrafficSitEventType_spare27" 33 "TrafficSitEventType_spare26" 32 "TrafficSitEventType_spare25" 31 "TrafficSitEventType_spare24" 30 "TrafficSitEventType_spare23" 29 "TrafficSitEventType_spare22" 28 "TrafficSitEventType_spare21" 27 "TrafficSitEventType_spare20" 26 "TrafficSitEventType_spare19" 25 "TrafficSitEventType_spare18" 24 "TrafficSitEventType_spare17" 23 "TrafficSitEventType_spare16" 22 "TrafficSitEventType_spare15" 21 "TrafficSitEventType_spare14" 20 "TrafficSitEventType_spare13" 19 "TrafficSitEventType_spare12" 18 "TrafficSitEventType_spare11" 17 "TrafficSitEventType_spare10" 16 "TrafficSitEventType_spare9" 15 "TrafficSitEventType_spare8" 14 "TrafficSitEventType_spare7" 13 "TrafficSitEventType_spare6" 12 "TrafficSitEventType_spare5" 11 "TrafficSitEventType_spare4" 10 "TrafficSitEventType_spare3" 9 "TrafficSitEventType_spare2" 8 "TrafficSitEventType_spare1" 7 "TrafficSitEventType_NarrowRoad" 6 "TrafficSitEventType_TrafficJam_OR_SlowTraffic" 5 "TrafficSitEventType_Crossing" 4 "TrafficSitEventType_Roundabout" 3 "TrafficSitEventType_CurveRight" 2 "TrafficSitEventType_CurveLeft" 1 "TrafficSitEventType_SpeedLimit" 0 "TrafficSitEventType_NoEvent" ;
VAL_ 694 BatteryCapacity 15 "BatteryType_NotAvailable" 14 "BatteryType_Error" 13 "BatteryType_NoSelectionMade" 12 "BatteryType_OtherBatteryType" 11 "BatteryType_BatteryType11" 10 "BatteryType_BatteryType10" 9 "BatteryType_BatteryType9" 8 "BatteryType_BatteryType8" 7 "BatteryType_BatteryType7" 6 "BatteryType_BatteryType6" 5 "BatteryType_BatteryType5" 4 "BatteryType_BatteryType4" 3 "BatteryType_BatteryType3" 2 "BatteryType_BatteryType2" 1 "BatteryType_BatteryType1" 0 "BatteryType_BatteryType0" ;
SIG_GROUP_ 880 PHTimerTGWEvCmd_sg 1 : PHTimerTGWEvCmd_PhTimer1_cmd PHTimerTGWEvCmd_Timer2Temp PHTimerTGWEvCmd_Timer2Hours PHTimerTGWEvCmd_Timer3StartDay PHTimerTGWEvCmd_Timer2StartDay PHTimerTGWEvCmd_PhTimer3_cmd PHTimerTGWEvCmd_Timer3Hours PHTimerTGWEvCmd_Timer2Recur PHTimerTGWEvCmd_PhTimer2_cmd PHTimerTGWEvCmd_Timer3Temp PHTimerTGWEvCmd_Timer1Hours PHTimerTGWEvCmd_Timer3Recur PHTimerTGWEvCmd_Timer3Minutes PHTimerTGWEvCmd_Timer1Minutes PHTimerTGWEvCmd_Timer1Recur PHTimerTGWEvCmd_Timer1StartDay PHTimerTGWEvCmd_Timer2Minutes PHTimerTGWEvCmd_Timer1Duration PHTimerTGWEvCmd_Timer1Temp;
SIG_GROUP_ 1209 LNGRestrictionStatus_sg 1 : LNGRestrictionStatus_Spare4 LNGRestrictionStatus_V1Closed LNGRestrictionStatus_Spare3 LNGRestrictionStatus_Spare2 LNGRestrictionStatus_Spare1 LNGRestrictionStatus_V2Closed LNGRestrictionStatus_SInfo;
SIG_GROUP_ 1201 DiagFaultStat_BBIOM_sg 1 : DiagFaultStat_BBIOM_DtcIdB DiagFaultStat_BBIOM_DtcIdA DiagFaultStat_BBIOM_FailTB DiagFaultStat_BBIOM_FailTA DiagFaultStat_BBIOM_EcuAdr;
SIG_GROUP_ 901 OilLevelDrvInstr_sg 1 : OilLevelDrvInstr_IncorrEngSpe OilLevelDrvInstr_ChangeGearTxt OilLevelDrvInstr_Wait60SecTxt OilLevelDrvInstr_OilTempTxt OilLevelDrvInstr_StopVehicle OilLevelDrvInstr_NotHorizonTxt;
SIG_GROUP_ 868 FrontConspicLamp_stat_sg 1 : FrontConspicLamp_stat_HiRight FrontConspicLamp_stat_LoRight FrontConspicLamp_stat_LoLeft FrontConspicLamp_stat_HiLeft;
SIG_GROUP_ 696 RedGladHand_sg 1 : RedGladHand_SqC RedGladHand_CRC RedGladHand_ConfidenceLvl RedGladHand_ConnectStatus;
SIG_GROUP_ 696 TrailerStatus_sg 1 : TrailerStatus_IntegrityLvl TrailerStatus_CRC TrailerStatus_SqC TrailerStatus_Actuation;
SIG_GROUP_ 695 TrafficSitPathEvent2_sg 1 : TrafficSitPathEvent2_Type TrafficSitPathEvent2_Speed TrafficSitPathEvent2_Distance;
SIG_GROUP_ 695 TrafficSitPathEvent1_sg 1 : TrafficSitPathEvent1_Distance TrafficSitPathEvent1_Speed TrafficSitPathEvent1_Type;
